VERSION ""

NS_ :

BS_:

BU_: Inverter1 Tester OBC_DDC VCU IPB Labcar_Transmit OBD_Tester TestTool_RB IMU_RB HU_B HU_C HU_A EPAS CKM12RX CKM12TX
VAL_TABLE_ CLU_Types 15 "Unknown" 14 "Unknown" 13 "Unknown" 12 "Unknown" 11 "Unknown" 10 "Unknown" 9 "Unknown" 8 "Unknown" 7 "Unknown" 6 "Unknown" 5 "Unknown" 4 "Unknown" 3 "Unknown" 2 " DRS-MM5.8" 1 "Unknown" 0 "Unknown" ;
VAL_TABLE_ CLU_Status 3 "Sync underflow" 2 "Sync overflow" 1 "Invalid" 0 "No sync failure" ;
VAL_TABLE_ Switches 1 "On" 0 "Off" ;
VAL_TABLE_ IMU_Sensor_Status 15 "Reserved" 14 "Reserved" 13 "Reserved" 12 "Reserved" 11 "Reserved" 10 "Reserved" 9 "Reserved" 8 "Reserved" 7 "Initialization running" 6 "Initialization running" 5 "Initialization running" 4 "Initialization running" 3 "Reserved" 2 "Signal failure" 1 "Sensor not available" 0 "Signal in specification" ;
VAL_TABLE_ Indicator_Color_Table 15 "Dim White" 14 "Dim Violet" 13 "Dim Blue" 12 "Dim Cyan" 11 "Dim Green" 10 "Dim Yellow" 9 "Dim Red" 8 "White" 7 "Violet" 6 "Blue" 5 "Cyan" 4 "Green" 3 "Yellow" 2 "Orange" 1 "Red" 0 "Black" ;

BO_ 3221225472 VECTOR__INDEPENDENT_SIG_MSG: 0 Vector__XXX
 SG_ MDriverRequest_Updated : 0|1@0+ (1,0) [0|1] "-" Vector__XXX
 SG_ MMotAct_Updated : 0|1@0+ (1,0) [0|1] "-" Vector__XXX
 SG_ HMI_OPD_Set_VirtualZeroPoint : 0|8@0+ (0.5,0) [0|50] "%" Vector__XXX
 SG_ HMI_OPD_MaxDeceleration : 0|8@0- (0.05,-3) [-3|0] "m/s 2" Vector__XXX

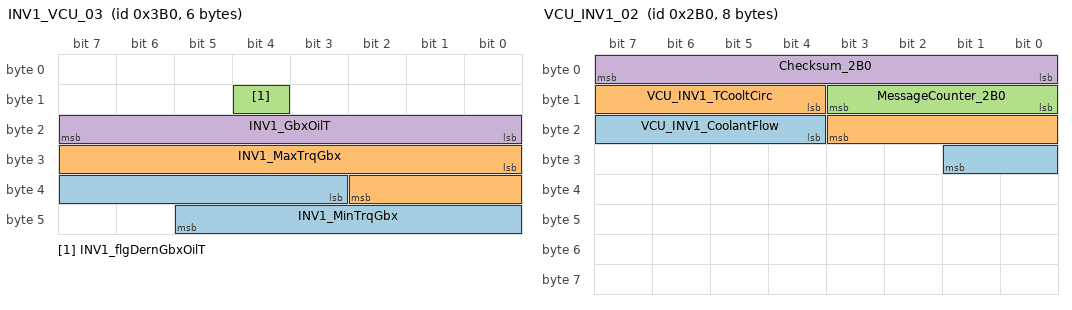
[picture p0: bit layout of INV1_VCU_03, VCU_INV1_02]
BO_ 944 INV1_VCU_03: 6 Inverter1
 SG_ INV1_MinTrqGbx : 35|11@1+ (1,-1023) [-1023|1024] "Nm"  VCU
 SG_ INV1_MaxTrqGbx : 24|11@1+ (1,-1023) [-1023|1024] "Nm"  VCU
 SG_ INV1_flgDernGbxOilT : 12|1@1+ (1,0) [0|1] "-"  VCU
 SG_ INV1_GbxOilT : 16|8@1+ (1,-40) [-40|213] "°C"  VCU

BO_ 688 VCU_INV1_02: 8 VCU
 SG_ VCU_INV1_CoolantFlow : 20|6@1+ (0.25,0) [0|15.5] "l/min"  Inverter1
 SG_ VCU_INV1_TCooltCirc : 12|8@1+ (1,-40) [-40|213] "°C"  Inverter1
 SG_ MessageCounter_2B0 : 8|4@1+ (1,0) [0|15] "-"  Inverter1
 SG_ Checksum_2B0 : 0|8@1+ (1,0) [0|255] "-"  Inverter1

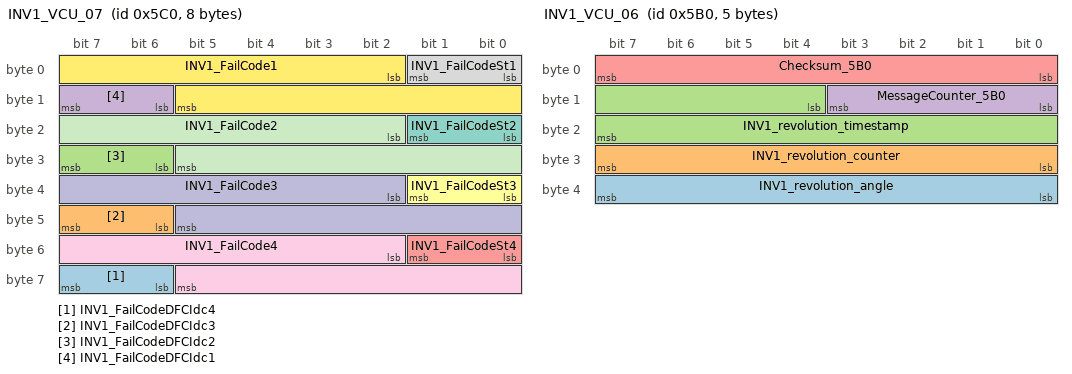
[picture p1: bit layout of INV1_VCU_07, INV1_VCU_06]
BO_ 1472 INV1_VCU_07: 8 Inverter1
 SG_ INV1_FailCodeDFCIdc4 : 62|2@1+ (1,0) [0|3] "" Vector__XXX
 SG_ INV1_FailCodeDFCIdc3 : 46|2@1+ (1,0) [0|3] "" Vector__XXX
 SG_ INV1_FailCodeDFCIdc2 : 30|2@1+ (1,0) [0|3] "" Vector__XXX
 SG_ INV1_FailCodeDFCIdc1 : 14|2@1+ (1,0) [0|3] "" Vector__XXX
 SG_ INV1_FailCodeSt4 : 48|2@1+ (1,0) [0|3] "" Vector__XXX
 SG_ INV1_FailCodeSt3 : 32|2@1+ (1,0) [0|3] "" Vector__XXX
 SG_ INV1_FailCodeSt2 : 16|2@1+ (1,0) [0|3] "" Vector__XXX
 SG_ INV1_FailCodeSt1 : 0|2@1+ (1,0) [0|3] "" Vector__XXX
 SG_ INV1_FailCode4 : 50|12@1+ (1,0) [0|4095] "" Vector__XXX
 SG_ INV1_FailCode3 : 34|12@1+ (1,0) [0|4095] "" Vector__XXX
 SG_ INV1_FailCode2 : 18|12@1+ (1,0) [0|4095] "" Vector__XXX
 SG_ INV1_FailCode1 : 2|12@1+ (1,0) [0|4095] "" Vector__XXX

BO_ 1456 INV1_VCU_06: 5 Inverter1
 SG_ INV1_revolution_angle : 32|8@1+ (2,0) [0|360] ""  VCU
 SG_ INV1_revolution_counter : 24|8@1+ (1,0) [0|255] ""  VCU
 SG_ INV1_revolution_timestamp : 12|12@1+ (1,0) [0|4095] ""  VCU
 SG_ MessageCounter_5B0 : 8|4@1+ (1,0) [0|15] "-"  VCU
 SG_ Checksum_5B0 : 0|8@1+ (1,0) [0|255] "-"  VCU

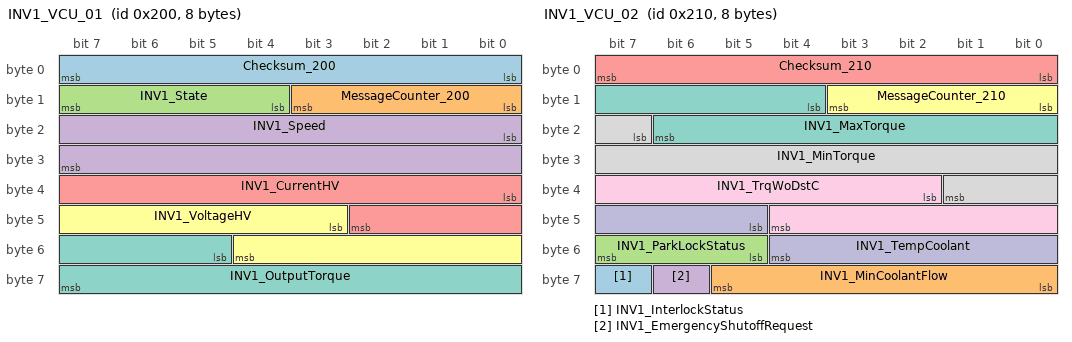
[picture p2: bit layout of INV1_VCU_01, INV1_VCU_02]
BO_ 512 INV1_VCU_01: 8 Inverter1
 SG_ Checksum_200 : 0|8@1+ (1,0) [0|255] "-"  VCU
 SG_ MessageCounter_200 : 8|4@1+ (1,0) [0|15] "-"  VCU
 SG_ INV1_State : 12|4@1+ (1,0) [0|15] "-"  VCU
 SG_ INV1_Speed : 16|16@1+ (1,-32767) [-32767|32766] "1/min"  VCU
 SG_ INV1_CurrentHV : 32|11@1+ (1,-1023) [-1023|1022] "A"  VCU
 SG_ INV1_VoltageHV : 43|10@1+ (1,0) [0|1021] "V"  VCU
 SG_ INV1_OutputTorque : 53|11@1+ (1,-1023) [-1023|1022] "Nm"  VCU

BO_ 528 INV1_VCU_02: 8 Inverter1
 SG_ INV1_InterlockStatus : 63|1@1+ (1,0) [0|1] "-"  VCU
 SG_ INV1_MinCoolantFlow : 56|6@1+ (0.25,0) [0|15.75] "l/min"  VCU
 SG_ INV1_ParkLockStatus : 53|3@1+ (1,0) [0|4] "-"  VCU
 SG_ INV1_EmergencyShutoffRequest : 62|1@1+ (1,0) [0|1] "-"  VCU
 SG_ Checksum_210 : 0|8@1+ (1,0) [0|255] "-"  VCU
 SG_ MessageCounter_210 : 8|4@1+ (1,0) [0|15] "-"  VCU
 SG_ INV1_MaxTorque : 12|11@1+ (1,-1023) [-1023|1024] "Nm"  VCU
 SG_ INV1_MinTorque : 23|11@1+ (1,-1023) [-1023|1024] "Nm"  VCU
 SG_ INV1_TrqWoDstC : 34|11@1+ (1,-1023) [-1023|1022] "Nm"  VCU
 SG_ INV1_TempCoolant : 45|8@1+ (1,-40) [-40|213] "°C"  VCU

BO_ 1568 INV1_VCU_04: 8 Inverter1
 SG_ INV1_MIL : 53|1@1+ (1,0) [0|1] "-"  VCU
 SG_ INV1_bDernTemp_Inverter : 48|1@1+ (1,0) [0|1] "-"  VCU
 SG_ INV1_bReadyHV : 63|1@1+ (1,0) [0|1] "-"  VCU
 SG_ INV1_bDstActive : 62|1@1+ (1,0) [0|1] "-"  VCU
 SG_ INV1_bDernTrqMax : 60|1@1+ (1,0) [0|1] "-"  VCU
 SG_ INV1_bDernTrqMin : 59|1@1+ (1,0) [0|1] "-"  VCU
 SG_ INV1_bDiagReq : 61|1@1+ (1,0) [0|1] "-"  VCU
 SG_ INV1_bDernTemp_EMachine : 58|1@1+ (1,0) [0|1] "-"  VCU
 SG_ INV1_bDernUndrIdc : 57|1@1+ (1,0) [0|1] "-"  VCU
 SG_ INV1_bDernOvrIdc : 56|1@1+ (1,0) [0|1] "-"  VCU
 SG_ INV1_bDernUndrUdc : 55|1@1+ (1,0) [0|1] "-"  VCU
 SG_ INV1_bDernOvrUdc : 54|1@1+ (1,0) [0|1] "-"  VCU
 SG_ INV1_StatorTemperature : 33|9@1+ (1,-40) [-40|469] "°C"  VCU
 SG_ Checksum_620 : 0|8@1+ (1,0) [0|255] "-"  VCU
 SG_ MessageCounter_620 : 8|4@1+ (1,0) [0|15] "-"  VCU
 SG_ INV1_EVServiceLight : 12|2@1+ (1,0) [0|3] "-"  VCU
 SG_ INV1_ElecTractionCtrlLight : 14|2@1+ (1,0) [0|3] "-"  VCU
 SG_ INV1_InverterTemperature : 16|8@1+ (1,-40) [-40|213] "°C"  VCU
 SG_ INV1_VoltageT30 : 42|6@1+ (0.5,0) [0|31.5] "V"  VCU
 SG_ INV1_RotorTemperature : 24|9@1+ (1,-40) [-40|469] "°C"  VCU

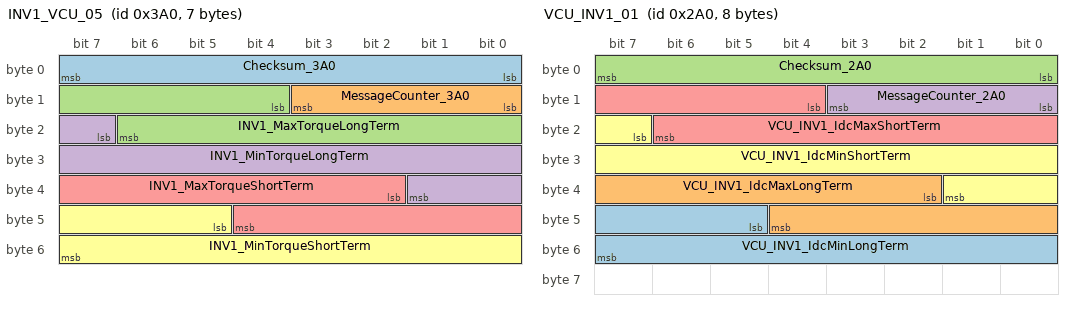
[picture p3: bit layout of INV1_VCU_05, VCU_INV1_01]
BO_ 928 INV1_VCU_05: 7 Inverter1
 SG_ Checksum_3A0 : 0|8@1+ (1,0) [0|255] "-"  VCU
 SG_ MessageCounter_3A0 : 8|4@1+ (1,0) [0|15] "-"  VCU
 SG_ INV1_MaxTorqueLongTerm : 12|11@1+ (1,-1023) [-1023|1024] "Nm"  VCU
 SG_ INV1_MinTorqueLongTerm : 23|11@1+ (1,-1023) [-1023|1024] "Nm"  VCU
 SG_ INV1_MaxTorqueShortTerm : 34|11@1+ (1,-1023) [-1023|1024] "Nm"  VCU
 SG_ INV1_MinTorqueShortTerm : 45|11@1+ (1,-1023) [-1023|1024] "Nm"  VCU

BO_ 672 VCU_INV1_01: 8 VCU
 SG_ VCU_INV1_IdcMinLongTerm : 45|11@1+ (1,-1023) [-1023|1022] "A"  Inverter1
 SG_ VCU_INV1_IdcMaxLongTerm : 34|11@1+ (1,-1023) [-1023|1022] "A"  Inverter1
 SG_ Checksum_2A0 : 0|8@1+ (1,0) [0|255] "-"  Inverter1
 SG_ MessageCounter_2A0 : 8|4@1+ (1,0) [0|15] "-"  Inverter1
 SG_ VCU_INV1_IdcMaxShortTerm : 12|11@1+ (1,-1023) [-1023|1022] "A"  Inverter1
 SG_ VCU_INV1_IdcMinShortTerm : 23|11@1+ (1,-1023) [-1023|1022] "A"  Inverter1

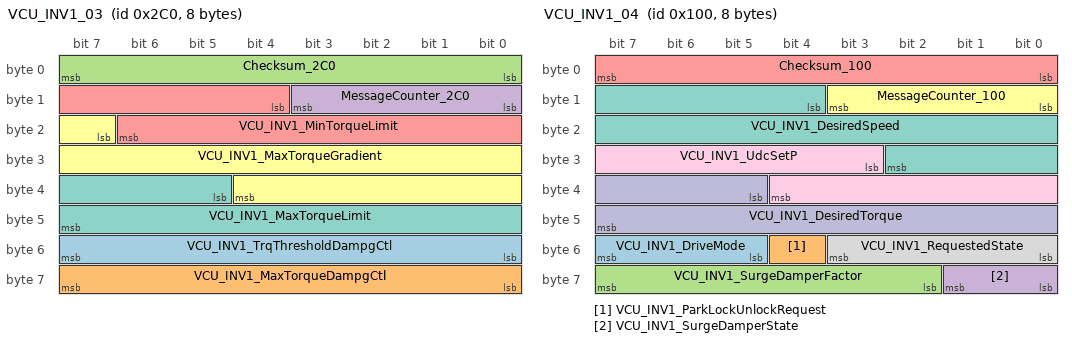
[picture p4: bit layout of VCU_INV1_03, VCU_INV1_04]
BO_ 704 VCU_INV1_03: 8 VCU
 SG_ VCU_INV1_TrqThresholdDampgCtl : 48|8@1+ (0.1,0) [0|25] "Nm"  Inverter1
 SG_ VCU_INV1_MaxTorqueDampgCtl : 56|8@1+ (1,0) [0|253] "Nm"  Inverter1
 SG_ Checksum_2C0 : 0|8@1+ (1,0) [0|255] "-"  Inverter1
 SG_ MessageCounter_2C0 : 8|4@1+ (1,0) [0|15] "-"  Inverter1
 SG_ VCU_INV1_MinTorqueLimit : 12|11@1+ (1,-1023) [-1023|1022] "Nm"  Inverter1
 SG_ VCU_INV1_MaxTorqueGradient : 23|14@1+ (32,0) [0|524192] "Nm/s"  Inverter1
 SG_ VCU_INV1_MaxTorqueLimit : 37|11@1+ (1,-1023) [-1023|1022] "Nm"  Inverter1

BO_ 256 VCU_INV1_04: 8 VCU
 SG_ VCU_INV1_DriveMode : 53|3@1+ (1,0) [0|7] ""  Inverter1
 SG_ VCU_INV1_ParkLockUnlockRequest : 52|1@1+ (1,0) [0|1] "-"  Inverter1
 SG_ VCU_INV1_SurgeDamperFactor : 58|6@1+ (0.125,0) [0|7.625] "-"  Inverter1
 SG_ VCU_INV1_SurgeDamperState : 56|2@1+ (1,0) [0|3] "-"  Inverter1
 SG_ Checksum_100 : 0|8@1+ (1,0) [0|255] "-"  Inverter1
 SG_ MessageCounter_100 : 8|4@1+ (1,0) [0|15] "-"  Inverter1
 SG_ VCU_INV1_DesiredSpeed : 12|15@1+ (1,-16383) [-16383|16382] "1/min"  Inverter1
 SG_ VCU_INV1_RequestedState : 48|4@1+ (1,0) [0|15] "-"  Inverter1
 SG_ VCU_INV1_UdcSetP : 27|10@1+ (1,0) [0|1021] "V"  Inverter1
 SG_ VCU_INV1_DesiredTorque : 37|11@1+ (1,-1023) [-1023|1022] "Nm"  Inverter1

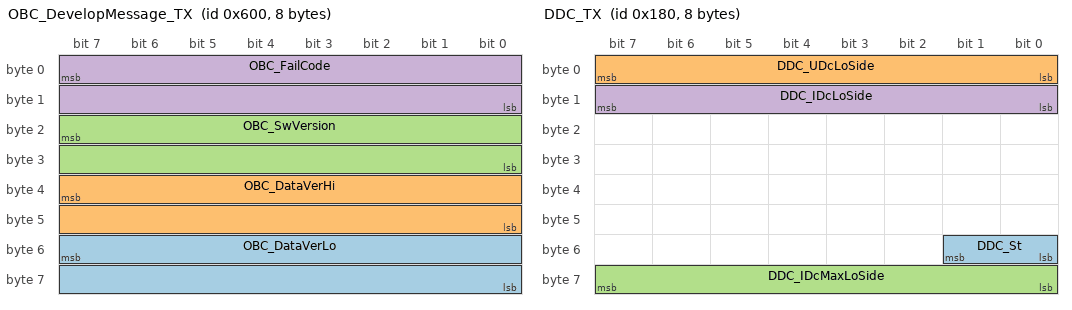
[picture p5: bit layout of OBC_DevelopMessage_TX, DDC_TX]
BO_ 1536 OBC_DevelopMessage_TX: 8 OBC_DDC
 SG_ OBC_DataVerLo : 55|16@0+ (1,0) [0|65535] ""  Tester
 SG_ OBC_DataVerHi : 39|16@0+ (1,0) [0|65535] ""  Tester
 SG_ OBC_SwVersion : 23|16@0+ (1,0) [0|65535] ""  Tester
 SG_ OBC_FailCode : 7|16@0+ (1,0) [0|65535] ""  Tester

BO_ 1637 DDC_TX1: 8 OBC_DDC
 SG_ DDC_UDcHiSide : 41|13@0+ (0.1,0) [0|510] "V"  Tester
 SG_ DDC_IDcHiSide : 15|8@0+ (1,0) [0|254] "A"  Tester

BO_ 384 DDC_TX: 8 OBC_DDC
 SG_ DDC_St : 49|2@0+ (1,0) [0|3] ""  Tester
 SG_ DDC_UDcLoSide : 7|8@0+ (0.1,0) [0|25.4] "V"  Tester
 SG_ DDC_IDcMaxLoSide : 63|8@0+ (1,0) [0|254] "A"  Tester
 SG_ DDC_IDcLoSide : 15|8@0+ (1,0) [0|255] "A"  Tester

BO_ 357 Tester_DDC_Ctrl: 8 Tester
 SG_ Tester_DDC_DesMod : 15|1@0+ (1,0) [0|1] ""  OBC_DDC
 SG_ Tester_DDC_UDcDes : 7|8@0+ (0.025,10.6) [10.6|16.95] "V"  OBC_DDC

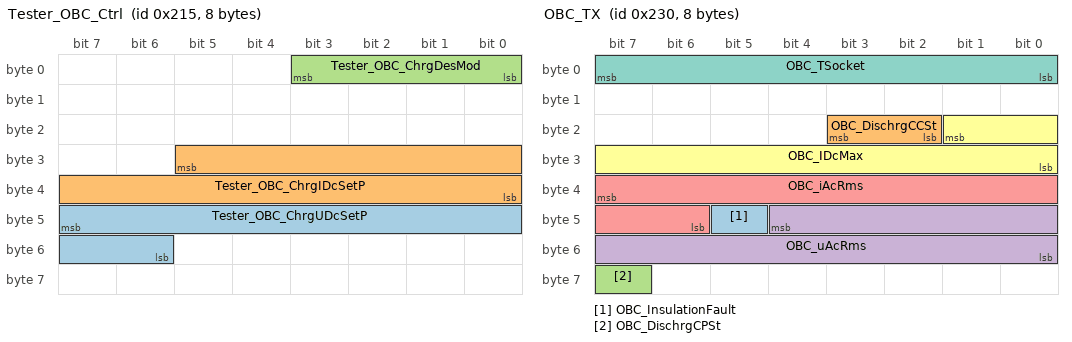
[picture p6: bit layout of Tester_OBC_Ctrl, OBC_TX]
BO_ 533 Tester_OBC_Ctrl: 8 Tester
 SG_ Tester_OBC_ChrgUDcSetP : 47|10@0+ (0.1,0) [0|100] "A"  OBC_DDC
 SG_ Tester_OBC_ChrgIDcSetP : 29|14@0+ (0.1,0) [0|500] "V"  OBC_DDC
 SG_ Tester_OBC_ChrgDesMod : 3|4@0+ (1,0) [0|15] ""  OBC_DDC

BO_ 640 Tester_ELK_Ctrl: 8 Tester
 SG_ Tester_ELK_Des : 7|3@0+ (1,0) [0|7] ""  OBC_DDC

BO_ 560 OBC_TX: 8 OBC_DDC
 SG_ OBC_InsulationFault : 45|1@0+ (1,0) [0|1] ""  Tester
 SG_ OBC_DischrgCCSt : 19|2@0+ (1,0) [0|3] ""  Tester
 SG_ OBC_DischrgCPSt : 63|1@0+ (1,0) [0|1] ""  Tester
 SG_ OBC_uAcRms : 44|13@0+ (0.1,0) [0|500] "V"  Tester
 SG_ OBC_iAcRms : 39|10@0+ (0.1,0) [0|100] "A"  Tester
 SG_ OBC_IDcMax : 17|10@0+ (0.1,0) [0|50] "A"  Tester
 SG_ OBC_TSocket : 7|8@0+ (1,-40) [-40|214] "DegreeC"  Tester

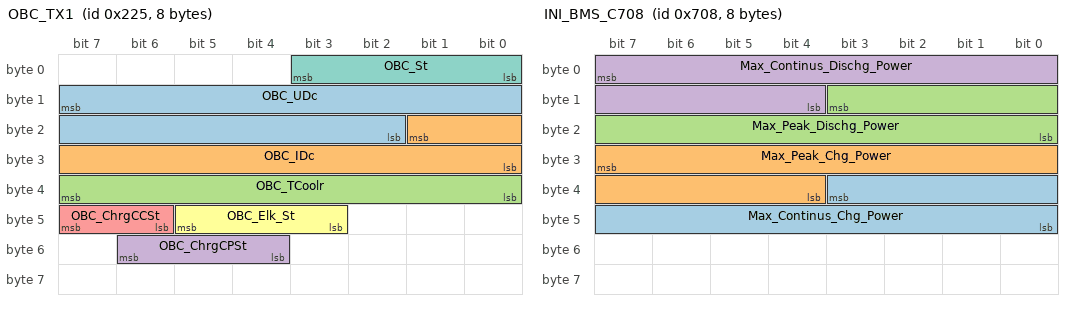
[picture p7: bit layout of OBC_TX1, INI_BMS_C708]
BO_ 549 OBC_TX1: 8 OBC_DDC
 SG_ OBC_UDc : 15|14@0+ (0.1,0) [0|1000] "V"  Tester
 SG_ OBC_IDc : 17|10@0+ (0.1,-50) [-50|50] "A"  Tester
 SG_ OBC_TCoolr : 39|8@0+ (1,-40) [-40|214] "DegreeC"  Tester
 SG_ OBC_ChrgCPSt : 54|3@0+ (1,0) [0|7] ""  Tester
 SG_ OBC_ChrgCCSt : 47|2@0+ (1,0) [0|3] ""  Tester
 SG_ OBC_Elk_St : 45|3@0+ (1,0) [0|4] ""  Tester
 SG_ OBC_St : 3|4@0+ (1,0) [0|15] ""  Tester

BO_ 1800 INI_BMS_C708: 8 Vector__XXX
 SG_ Max_Continus_Chg_Power : 35|12@0+ (0.1,0) [0|300] ""  VCU
 SG_ Max_Peak_Chg_Power : 31|12@0+ (0.1,0) [0|300] ""  VCU
 SG_ Max_Peak_Dischg_Power : 11|12@0+ (0.1,0) [0|300] ""  VCU
 SG_ Max_Continus_Dischg_Power : 7|12@0+ (0.1,0) [0|300] ""  VCU

BO_ 1799 INI_BMS_C707: 8 Vector__XXX
 SG_ BMUFault : 36|1@0+ (1,0) [0|1] ""  VCU
 SG_ LowVoltSupplyAlarm : 39|1@0+ (1,0) [0|1] ""  VCU
 SG_ PrechargeFaultAlarm : 37|1@0+ (1,0) [0|1] ""  VCU
 SG_ BattDischrgOverCurrAlarm : 31|2@0+ (1,0) [0|3] ""  VCU
 SG_ BattFBOverCurrAlarm : 17|2@0+ (1,0) [0|3] ""  VCU
 SG_ SOCJump : 19|2@0+ (1,0) [0|3] ""  VCU
 SG_ SOCLowAlarm : 21|2@0+ (1,0) [0|3] ""  VCU
 SG_ InsulationFault : 29|2@0+ (1,0) [0|3] ""  VCU
 SG_ PosMainRlyConglut : 26|1@0+ (1,0) [0|1] ""  VCU
 SG_ CAN3CommAlarm : 24|1@0+ (1,0) [0|1] ""  VCU
 SG_ CAN1CommAlarm : 25|1@0+ (1,0) [0|1] ""  VCU
 SG_ TotalBattVoltUnderAlarm : 15|2@0+ (1,0) [0|3] ""  VCU
 SG_ BattUnderTempAlarm : 11|2@0+ (1,0) [0|3] ""  VCU
 SG_ NegMainRlyConglut : 27|1@0+ (1,0) [0|1] ""  VCU
 SG_ HVILAlarm : 38|1@0+ (1,0) [0|1] ""  VCU
 SG_ TotalBattVoltOverAlarm : 1|2@0+ (1,0) [0|3] ""  VCU
 SG_ BattHighTempAlarm : 13|2@0+ (1,0) [0|3] ""  VCU
 SG_ SOCHighAlarm : 23|2@0+ (1,0) [0|3] ""  VCU
 SG_ CellVoltDiffOverAlarm : 3|2@0+ (1,0) [0|3] ""  VCU
 SG_ CellTempDiffOverAlarm : 9|2@0+ (1,0) [0|3] ""  VCU
 SG_ MinCellVoltUnderAlarm : 5|2@0+ (1,0) [0|3] ""  VCU
 SG_ MaxCellVoltOverAlarm : 7|2@0+ (1,0) [0|3] ""  VCU

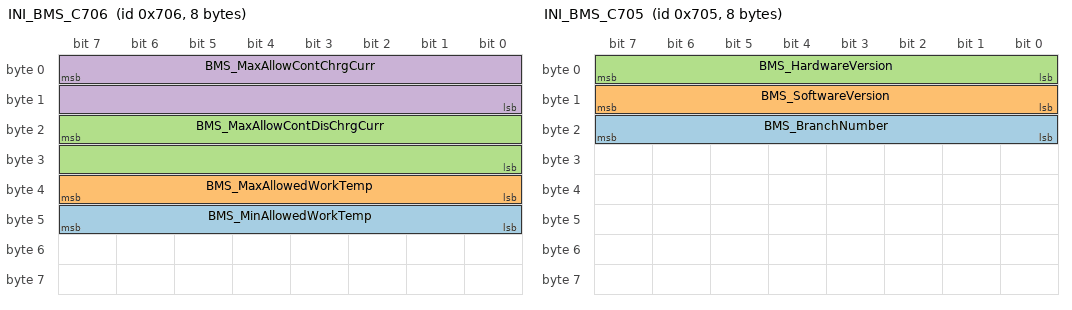
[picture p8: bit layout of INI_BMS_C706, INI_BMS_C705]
BO_ 1798 INI_BMS_C706: 8 Vector__XXX
 SG_ BMS_MinAllowedWorkTemp : 47|8@0+ (1,-40) [-40|210] "ºC"  VCU
 SG_ BMS_MaxAllowedWorkTemp : 39|8@0+ (1,-40) [-40|210] "ºC"  VCU
 SG_ BMS_MaxAllowContDisChrgCurr : 23|16@0+ (0.1,0) [0|1000] "A"  VCU
 SG_ BMS_MaxAllowContChrgCurr : 7|16@0+ (0.1,0) [0|1000] "A"  VCU

BO_ 1797 INI_BMS_C705: 8 Vector__XXX
 SG_ BMS_BranchNumber : 23|8@0+ (1,0) [0|255] ""  VCU
 SG_ BMS_SoftwareVersion : 15|8@0+ (0.1,0) [0|25.5] ""  VCU
 SG_ BMS_HardwareVersion : 7|8@0+ (0.1,0) [0|25.5] ""  VCU

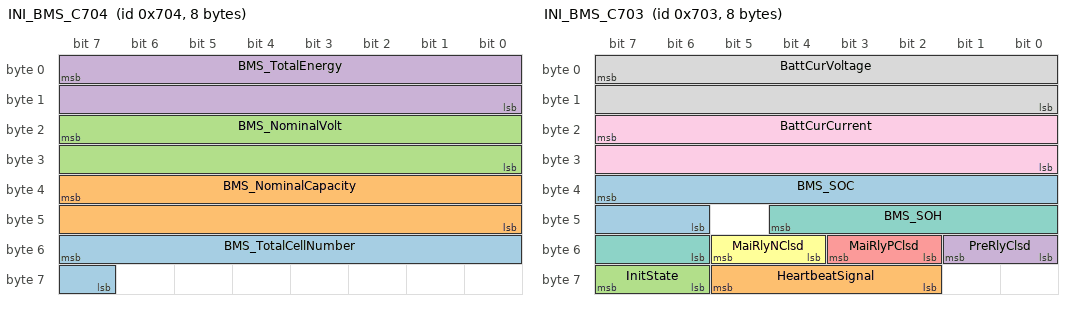
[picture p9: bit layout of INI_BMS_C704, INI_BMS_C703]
BO_ 1796 INI_BMS_C704: 8 Vector__XXX
 SG_ BMS_TotalCellNumber : 55|9@0+ (1,0) [0|511] ""  VCU
 SG_ BMS_NominalCapacity : 39|16@0+ (0.1,0) [0|1000] "AH"  VCU
 SG_ BMS_NominalVolt : 23|16@0+ (0.1,0) [0|1000] "V"  VCU
 SG_ BMS_TotalEnergy : 7|16@0+ (0.01,0) [0|655.35] "KWh"  VCU

BO_ 1795 INI_BMS_C703: 8 Vector__XXX
 SG_ BMS_SOC : 39|10@0+ (0.1,0) [0|102.3] "%"  VCU
 SG_ HeartbeatSignal : 61|4@0+ (1,0) [0|15] ""  VCU
 SG_ InitState : 63|2@0+ (1,0) [0|3] ""  VCU
 SG_ PreRlyClsd : 49|2@0+ (1,0) [0|3] ""  VCU
 SG_ MaiRlyPClsd : 51|2@0+ (1,0) [0|3] ""  VCU
 SG_ MaiRlyNClsd : 53|2@0+ (1,0) [0|3] ""  VCU
 SG_ BMS_SOH : 44|7@0+ (1,0) [0|100] "%"  VCU
 SG_ BattCurVoltage : 7|16@0+ (0.1,0) [0|500] "A"  VCU
 SG_ BattCurCurrent : 23|16@0+ (0.1,-600) [-600|600] "V"  VCU

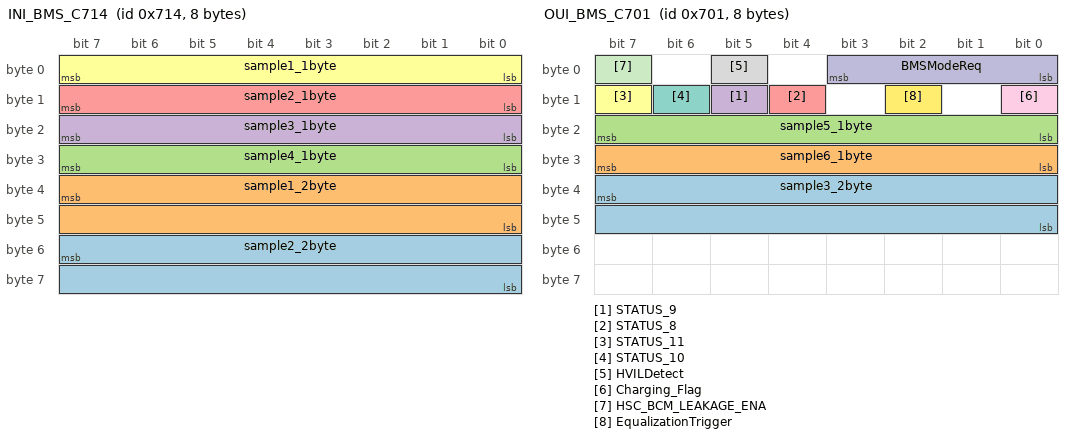
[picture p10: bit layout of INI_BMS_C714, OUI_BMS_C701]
BO_ 1812 INI_BMS_C714: 8 Vector__XXX
 SG_ sample2_2byte : 55|16@0+ (1,0) [0|65535] ""  VCU
 SG_ sample1_2byte : 39|16@0+ (1,0) [0|65535] ""  VCU
 SG_ sample4_1byte : 31|8@0+ (1,0) [0|255] ""  VCU
 SG_ sample3_1byte : 23|8@0+ (1,0) [0|255] ""  VCU
 SG_ sample2_1byte : 15|8@0+ (1,0) [0|255] ""  VCU
 SG_ sample1_1byte : 7|8@0+ (1,0) [0|255] ""  VCU

BO_ 1794 OUI_BMS_C702: 8 VCU
 SG_ Busbar_Voltage : 7|16@0+ (1,0) [0|500] "V" Vector__XXX

BO_ 1793 OUI_BMS_C701: 8 VCU
 SG_ sample3_2byte : 39|16@0+ (1,0) [0|65535] "" Vector__XXX
 SG_ sample6_1byte : 31|8@0+ (1,0) [0|255] "" Vector__XXX
 SG_ sample5_1byte : 23|8@0+ (1,0) [0|255] "" Vector__XXX
 SG_ STATUS_9 : 13|1@0+ (1,0) [0|1] "" Vector__XXX
 SG_ STATUS_8 : 12|1@0+ (1,0) [0|1] "" Vector__XXX
 SG_ STATUS_11 : 15|1@0+ (1,0) [0|1] "" Vector__XXX
 SG_ STATUS_10 : 14|1@0+ (1,0) [0|1] "" Vector__XXX
 SG_ HVILDetect : 5|1@0+ (1,0) [0|1] "" Vector__XXX
 SG_ Charging_Flag : 8|1@0+ (1,0) [0|1] "" Vector__XXX
 SG_ BMSModeReq : 3|4@0+ (1,0) [0|15] "" Vector__XXX
 SG_ HSC_BCM_LEAKAGE_ENA : 7|1@0+ (1,0) [0|1] "" Vector__XXX
 SG_ EqualizationTrigger : 10|1@0+ (1,0) [0|1] "" Vector__XXX

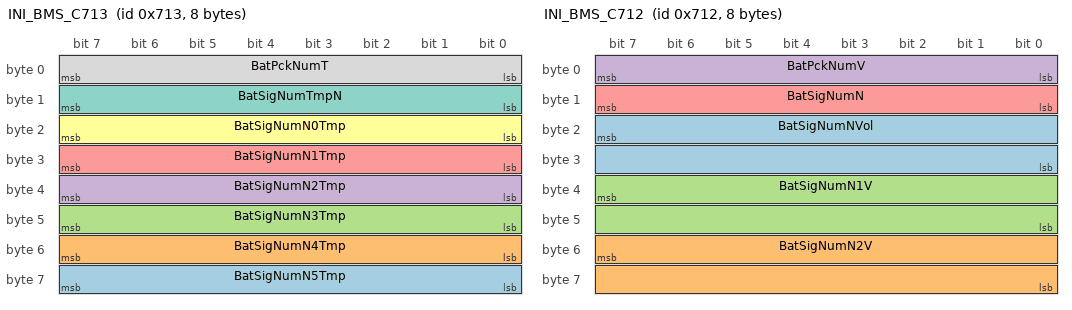
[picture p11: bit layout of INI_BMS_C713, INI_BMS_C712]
BO_ 1811 INI_BMS_C713: 8 Vector__XXX
 SG_ BatSigNumN5Tmp : 63|8@0+ (1,-40) [-40|215] "?"  VCU
 SG_ BatSigNumN4Tmp : 55|8@0+ (1,-40) [-40|215] "?"  VCU
 SG_ BatSigNumN3Tmp : 47|8@0+ (1,-40) [-40|215] "?"  VCU
 SG_ BatSigNumN2Tmp : 39|8@0+ (1,-40) [-40|215] "?"  VCU
 SG_ BatSigNumN1Tmp : 31|8@0+ (1,-40) [-40|215] "?"  VCU
 SG_ BatSigNumN0Tmp : 23|8@0+ (1,-40) [-40|215] "?"  VCU
 SG_ BatSigNumTmpN : 15|8@0+ (1,0) [0|255] ""  VCU
 SG_ BatPckNumT : 7|8@0+ (1,0) [0|255] ""  VCU

BO_ 1810 INI_BMS_C712: 8 Vector__XXX
 SG_ BatSigNumNVol : 23|16@0+ (0.001,0) [0|50] "V"  VCU
 SG_ BatSigNumN2V : 55|16@0+ (0.001,0) [0|50] "V"  VCU
 SG_ BatSigNumN1V : 39|16@0+ (0.001,0) [0|50] "V"  VCU
 SG_ BatPckNumV : 7|8@0+ (1,0) [0|255] ""  VCU
 SG_ BatSigNumN : 15|8@0+ (1,0) [0|255] ""  VCU

BO_ 1801 INI_BMS_C709: 7 Vector__XXX
 SG_ STATUS_1 : 49|1@0+ (1,0) [0|1] ""  VCU
 SG_ STATUS_2 : 50|1@0+ (1,0) [0|1] ""  VCU
 SG_ STATUS_3 : 51|1@0+ (1,0) [0|1] ""  VCU
 SG_ STATUS_4 : 52|1@0+ (1,0) [0|1] ""  VCU
 SG_ STATUS_5 : 53|1@0+ (1,0) [0|1] ""  VCU
 SG_ STATUS_6 : 54|1@0+ (1,0) [0|1] ""  VCU
 SG_ STATUS_7 : 55|1@0+ (1,0) [0|1] ""  VCU
 SG_ BMS_DerateFlag : 48|1@0+ (1,0) [0|1] ""  VCU
 SG_ SOC_CalibrationFlag : 40|1@0+ (1,0) [0|1] ""  VCU
 SG_ OperMod : 47|4@0+ (1,0) [0|15] ""  VCU
 SG_ MinTempProbeNo : 39|8@0+ (1,0) [0|255] ""  VCU
 SG_ MinTempBattPackSubSysNo : 3|4@0+ (1,0) [0|15] ""  VCU
 SG_ MinPresentTemp : 31|8@0+ (1,-50) [-50|200] "Temp"  VCU
 SG_ MaxTempProbeNo : 23|8@0+ (1,0) [0|255] ""  VCU
 SG_ MaxTempBattPackSubSysNo : 7|4@0+ (1,0) [0|15] ""  VCU
 SG_ MaxPresentTemp : 15|8@0+ (1,-50) [-50|200] "Temp"  VCU
 SG_ FltRank : 43|3@0+ (1,0) [0|7] ""  VCU

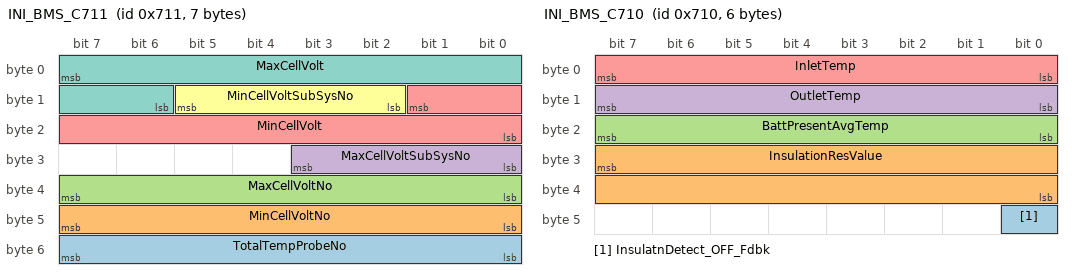
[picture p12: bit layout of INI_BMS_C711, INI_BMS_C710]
BO_ 1809 INI_BMS_C711: 7 Vector__XXX
 SG_ TotalTempProbeNo : 55|8@0+ (1,0) [0|255] ""  VCU
 SG_ MinCellVoltNo : 47|8@0+ (1,0) [0|255] ""  VCU
 SG_ MaxCellVoltNo : 39|8@0+ (1,0) [0|255] ""  VCU
 SG_ MaxCellVoltSubSysNo : 27|4@0+ (1,0) [0|15] ""  VCU
 SG_ MinCellVolt : 9|10@0+ (0.01,0) [0|10.23] ""  VCU
 SG_ MinCellVoltSubSysNo : 13|4@0+ (1,0) [0|15] ""  VCU
 SG_ MaxCellVolt : 7|10@0+ (0.01,0) [0|10.23] "V"  VCU

BO_ 1808 INI_BMS_C710: 6 Vector__XXX
 SG_ InsulatnDetect_OFF_Fdbk : 40|1@0+ (1,0) [0|1] ""  VCU
 SG_ InsulationResValue : 31|16@0+ (1,0) [0|50000] "KO"  VCU
 SG_ BattPresentAvgTemp : 23|8@0+ (1,-50) [-50|200] ""  VCU
 SG_ OutletTemp : 15|8@0+ (1,-50) [-50|200] ""  VCU
 SG_ InletTemp : 7|8@0+ (1,-50) [-50|200] ""  VCU

BO_ 701 OPD2: 3 VCU
 SG_ HMI_OPD_Enable : 7|8@0+ (1,0) [0|1] "-"  IPB

BO_ 0 New_Message_52: 8 Vector__XXX
 SG_ New_Signal_331 : 8|8@1+ (1,0) [0|0] "" Vector__XXX

BO_ 2019 VCU_DiagRequest: 8 Vector__XXX
 SG_ VCU_DiagRequest : 7|64@0+ (1,0) [0|0] ""  VCU

BO_ 2027 VCU_DiagResponse_USDT: 8 VCU
 SG_ VCU_DiagResponse_USDT : 7|64@0+ (1,0) [0|0] "" Vector__XXX

BO_ 280 BRAKE10: 8 Vector__XXX
 SG_ InhibitRecuprationAbsStatus : 6|2@0+ (1,0) [0|3] ""  VCU
 SG_ InhibitRecuprationAbs : 7|1@0+ (1,0) [0|1] ""  VCU

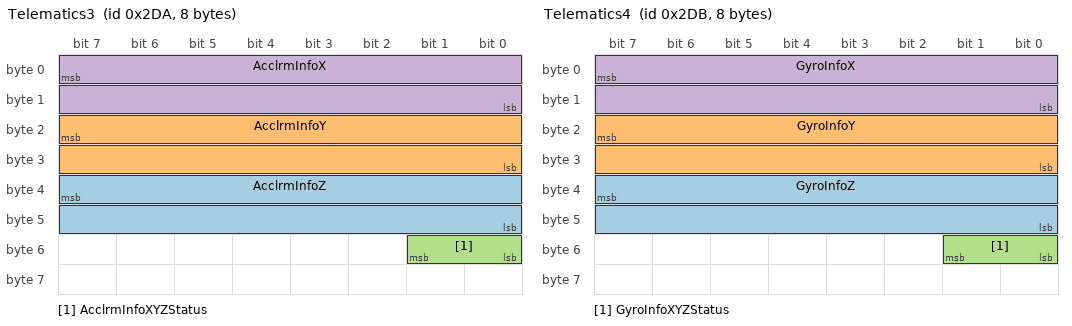
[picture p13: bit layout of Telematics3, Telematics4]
BO_ 730 Telematics3: 8 Vector__XXX
 SG_ AcclrmInfoZ : 39|16@0+ (0.01,-300) [-300|300] "m/s^2"  VCU
 SG_ AcclrmInfoY : 23|16@0+ (0.01,-300) [-300|300] "m/s^2"  VCU
 SG_ AcclrmInfoXYZStatus : 49|2@0+ (1,0) [0|3] ""  VCU
 SG_ AcclrmInfoX : 7|16@0+ (0.01,-300) [-300|300] "m/s^2"  VCU

BO_ 731 Telematics4: 8 Vector__XXX
 SG_ GyroInfoZ : 39|16@0+ (0.1,-2000) [-2000|2000] "deg/s"  VCU
 SG_ GyroInfoY : 23|16@0+ (0.1,-2000) [-2000|2000] "deg/s"  VCU
 SG_ GyroInfoXYZStatus : 49|2@0+ (1,0) [0|3] ""  VCU
 SG_ GyroInfoX : 7|16@0+ (0.1,-2000) [-2000|2000] "deg/s"  VCU

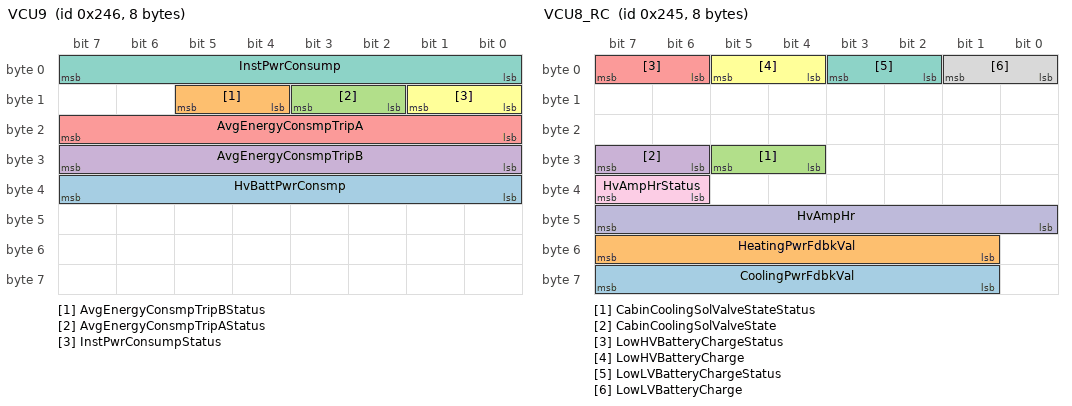
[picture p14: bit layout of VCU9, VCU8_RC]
BO_ 582 VCU9: 8 VCU
 SG_ HvBattPwrConsmp : 39|8@0+ (1,0) [0|250] "KwHr" Vector__XXX
 SG_ AvgEnergyConsmpTripBStatus : 13|2@0+ (1,0) [0|3] "" Vector__XXX
 SG_ AvgEnergyConsmpTripAStatus : 11|2@0+ (1,0) [0|3] "" Vector__XXX
 SG_ AvgEnergyConsmpTripB : 31|8@0+ (1,0) [0|250] "kwH/Km" Vector__XXX
 SG_ AvgEnergyConsmpTripA : 23|8@0+ (1,0) [0|250] "kwH/Km" Vector__XXX
 SG_ InstPwrConsumpStatus : 9|2@0+ (1,0) [0|3] "" Vector__XXX
 SG_ InstPwrConsump : 7|8@0+ (1,-100) [-100|100] "%" Vector__XXX

BO_ 719 CCM_RC2: 8 Vector__XXX
 SG_ PtcHtrForcedCutoff : 7|2@0+ (1,0) [0|3] ""  VCU

BO_ 1142 VCU_SF: 8 VCU
 SG_ PEPS_Invalid_failure_status : 55|2@0+ (1,0) [0|3] "" Vector__XXX
 SG_ Telematics_MTO_Failure_status : 61|2@0+ (1,0) [0|3] "" Vector__XXX
 SG_ Telematics_Invalid_FailureStatus : 63|2@0+ (1,0) [0|3] "" Vector__XXX
 SG_ SRS_MTO_Failure_Status : 59|2@0+ (1,0) [0|3] "" Vector__XXX
 SG_ PEPS_MTO_Failure_Status : 53|2@0+ (1,0) [0|3] "" Vector__XXX
 SG_ IPcMToFailureStatus : 49|2@0+ (1,0) [0|3] "" Vector__XXX
 SG_ IPcInvalidFailureStatus : 51|2@0+ (1,0) [0|3] "" Vector__XXX
 SG_ ABsMToFailureStatus : 7|2@0+ (1,0) [0|3] "" Vector__XXX
 SG_ ABsInvalidFailureStatus : 5|2@0+ (1,0) [0|3] "" Vector__XXX
 SG_ VCU_SW_Version : 31|16@0+ (1,0) [0|65535] "" Vector__XXX
 SG_ VCU_Err_State_Trans_Cntr : 23|8@0+ (1,0) [0|255] "" Vector__XXX
 SG_ VCU_EP_Failure_Status : 13|2@0+ (1,0) [0|3] "" Vector__XXX
 SG_ VCU_BO_Failure_Status : 15|2@0+ (1,0) [0|3] "" Vector__XXX
 SG_ GSS_EV_Invalid_Failure_Status : 41|2@0+ (1,0) [0|3] "" Vector__XXX
 SG_ GSS_EV_MTO_Failure_Status : 43|2@0+ (1,0) [0|3] "" Vector__XXX
 SG_ CCM_MTO_Failure_Status : 45|2@0+ (1,0) [0|3] "" Vector__XXX
 SG_ CCM_Invalid_Failure_Status : 47|2@0+ (1,0) [0|3] "" Vector__XXX
 SG_ BCmInvalidFailureStatus : 9|2@0+ (1,0) [0|3] "" Vector__XXX
 SG_ BCmMToFailureStatus : 11|2@0+ (1,0) [0|3] "" Vector__XXX

BO_ 581 VCU8_RC: 8 VCU
 SG_ CoolingPwrFdbkVal : 63|7@0+ (1,0) [0|100] "%" Vector__XXX
 SG_ HeatingPwrFdbkVal : 55|7@0+ (1,0) [0|100] "%" Vector__XXX
 SG_ CabinCoolingSolValveStateStatus : 29|2@0+ (1,0) [0|3] "" Vector__XXX
 SG_ CabinCoolingSolValveState : 31|2@0+ (1,0) [0|3] "" Vector__XXX
 SG_ LowHVBatteryChargeStatus : 7|2@0+ (1,0) [0|3] "" Vector__XXX
 SG_ LowHVBatteryCharge : 5|2@0+ (1,0) [0|3] "" Vector__XXX
 SG_ LowLVBatteryChargeStatus : 3|2@0+ (1,0) [0|3] "" Vector__XXX
 SG_ LowLVBatteryCharge : 1|2@0+ (1,0) [0|3] "" Vector__XXX
 SG_ HvAmpHrStatus : 39|2@0+ (1,0) [0|3] "" Vector__XXX
 SG_ HvAmpHr : 47|8@0+ (0.5,0) [0|125] "" Vector__XXX

BO_ 1288 TCU_NMPDU: 8 Vector__XXX
 SG_ PartialNetworkInformation_TCU : 14|1@0+ (1,0) [0|1] ""  VCU
 SG_ Reserved55 : 23|1@0+ (1,0) [0|1] ""  VCU
 SG_ Reserved54 : 22|1@0+ (1,0) [0|1] ""  VCU
 SG_ Reserved53 : 21|1@0+ (1,0) [0|1] ""  VCU
 SG_ Reserved52 : 20|1@0+ (1,0) [0|1] ""  VCU
 SG_ Reserved51 : 15|1@0+ (1,0) [0|1] ""  VCU
 SG_ Reserved50 : 13|1@0+ (1,0) [0|1] ""  VCU
 SG_ Reserved49 : 10|1@0+ (1,0) [0|1] ""  VCU
 SG_ Reserved48 : 9|1@0+ (1,0) [0|1] ""  VCU
 SG_ RepeatMessageReq_TCU : 8|1@0+ (1,0) [0|1] ""  VCU
 SG_ PreviousState_TCU : 19|3@0+ (1,0) [0|7] ""  VCU
 SG_ NMCoOrdSlpReady_TCU : 11|1@0+ (1,0) [0|1] ""  VCU
 SG_ CurrentState_TCU : 16|1@0+ (1,0) [0|1] ""  VCU
 SG_ TCU_NMPDU_USER_DATA_D5 : 63|8@0+ (1,0) [0|255] ""  VCU
 SG_ TCU_NMPDU_USER_DATA_D4 : 55|8@0+ (1,0) [0|255] ""  VCU
 SG_ TCU_NMPDU_USER_DATA_D3 : 47|8@0+ (1,0) [0|255] ""  VCU
 SG_ TCU_NMPDU_USER_DATA_D2 : 39|8@0+ (1,0) [0|255] ""  VCU
 SG_ TCU_NMPDU_USER_DATA_D1 : 31|8@0+ (1,0) [0|255] ""  VCU
 SG_ TCU_NMPDU_SRC_ECU_ID : 7|8@0+ (1,0) [0|255] ""  VCU
 SG_ ActiveWakeUp_TCU : 12|1@0+ (1,0) [0|1] ""  VCU

BO_ 1287 VCU_NMPDU: 8 VCU
 SG_ PartialNetworkInformation_VCU : 14|1@0+ (1,0) [0|1] "" Vector__XXX
 SG_ VCU_NMPDU_USER_DATA_D3 : 47|8@0+ (1,0) [0|255] "" Vector__XXX
 SG_ Reserved47 : 23|1@0+ (1,0) [0|1] "" Vector__XXX
 SG_ Reserved46 : 22|1@0+ (1,0) [0|1] "" Vector__XXX
 SG_ Reserved45 : 21|1@0+ (1,0) [0|1] "" Vector__XXX
 SG_ Reserved44 : 20|1@0+ (1,0) [0|1] "" Vector__XXX
 SG_ Reserved43 : 15|1@0+ (1,0) [0|1] "" Vector__XXX
 SG_ Reserved42 : 13|1@0+ (1,0) [0|1] "" Vector__XXX
 SG_ Reserved41 : 10|1@0+ (1,0) [0|1] "" Vector__XXX
 SG_ Reserved40 : 9|1@0+ (1,0) [0|1] "" Vector__XXX
 SG_ RepeatMessageReq_VCU : 8|1@0+ (1,0) [0|1] "" Vector__XXX
 SG_ PreviousState_VCU : 19|3@0+ (1,0) [0|7] "" Vector__XXX
 SG_ NMCoOrdSlpReady_VCU : 11|1@0+ (1,0) [0|1] "" Vector__XXX
 SG_ CurrentState_VCU : 16|1@0+ (1,0) [0|1] "" Vector__XXX
 SG_ VCU_NMPDU_USER_DATA_D5 : 63|8@0+ (1,0) [0|255] "" Vector__XXX
 SG_ VCU_NMPDU_USER_DATA_D4 : 55|8@0+ (1,0) [0|255] "" Vector__XXX
 SG_ VCU_NMPDU_USER_DATA_D2 : 39|8@0+ (1,0) [0|255] "" Vector__XXX
 SG_ VCU_NMPDU_USER_DATA_D1 : 31|8@0+ (1,0) [0|255] "" Vector__XXX
 SG_ VCU_NMPDU_SRC_ECU_ID : 7|8@0+ (1,0) [0|255] "" Vector__XXX
 SG_ ActiveWakeUp_VCU : 12|1@0+ (1,0) [0|1] "" Vector__XXX

BO_ 703 IPC_RC1: 8 Vector__XXX
 SG_ OATICSigNewStatus : 15|2@0+ (1,0) [0|3] ""  VCU
 SG_ OATICSigNew : 7|8@0+ (0.5,-40) [-40|85] "degC"  VCU

CM_ BU_ Inverter1 "Inverter";
CM_ BU_ VCU "Vehicle Control Unit";
CM_ BO_ 3221225472 "This is a message for not used signals, created by Vector CANdb++ DBC OLE DB Provider.";
CM_ BO_ 944 "Frame for Gearbox specific signals of eAxle. 
Inactive if INV1 is not an eAxle but a standalone Inverter.";
CM_ SG_ 944 INV1_MinTrqGbx "eAxle Gearbox minimum allowed torque";
CM_ SG_ 944 INV1_MaxTrqGbx "eAxle Gearbox maximum allowed torque";
CM_ SG_ 944 INV1_flgDernGbxOilT "Derating because of gearbox oil temperature";
CM_ SG_ 944 INV1_GbxOilT "Temperature of eAxle Gearbox Oil (INV1)";
CM_ SG_ 688 VCU_INV1_CoolantFlow "current coolant flow based on pump actuation";
CM_ SG_ 688 VCU_INV1_TCooltCirc "Temperature Coolant Circuit close to INV1 (upstream INV1 preferred)";
CM_ SG_ 688 MessageCounter_2B0 "Message counter signal for frame 2B0";
CM_ SG_ 688 Checksum_2B0 "Checksum signal for frame 2B0";
CM_ BO_ 1472 "Inverter1 Information Frame (Fault Codes).
For Fault Code Definition see TCD - technical customer documentation.";
CM_ SG_ 1472 INV1_FailCodeDFCIdc4 "Inverter1 Failure code4 DFC Id";
CM_ SG_ 1472 INV1_FailCodeDFCIdc3 "Inverter1 Failure code3 DFC Id";
CM_ SG_ 1472 INV1_FailCodeDFCIdc2 "Inverter1 Failure code2 DFC Id";
CM_ SG_ 1472 INV1_FailCodeDFCIdc1 "Inverter1 Failure code1 DFC Id";
CM_ SG_ 1472 INV1_FailCodeSt4 "Inverter1 Failure code4 state";
CM_ SG_ 1472 INV1_FailCodeSt3 "Inverter1 Failure code3 state";
CM_ SG_ 1472 INV1_FailCodeSt2 "Inverter1 Failure code2 state";
CM_ SG_ 1472 INV1_FailCodeSt1 "Inverter1 Failure code1 state";
CM_ SG_ 1472 INV1_FailCode4 "Inverter1 Failure code4 value.
For Fault Code Definition see TCD - technical customer documentation.";
CM_ SG_ 1472 INV1_FailCode3 "Inverter1 Failure code3 value.
For Fault Code Definition see TCD - technical customer documentation.";
CM_ SG_ 1472 INV1_FailCode2 "Inverter1 Failure code2 value.
For Fault Code Definition see TCD - technical customer documentation.";
CM_ SG_ 1472 INV1_FailCode1 "Inverter1 Failure code1 value.
For Fault Code Definition see TCD - technical customer documentation.";
CM_ BO_ 1456 "Inverter1 Information Frame (Temperatures / controller supply)";
CM_ SG_ 1456 INV1_revolution_angle "current angle position of the rotor";
CM_ SG_ 1456 INV1_revolution_counter "number of full electrical (not mechanical) revolutions of the e-machine";
CM_ SG_ 1456 INV1_revolution_timestamp "number of PWM task in which the other signals were calculated";
CM_ SG_ 1456 MessageCounter_5B0 "Message counter signal for frame";
CM_ SG_ 1456 Checksum_5B0 "Checksum signal for frame";
CM_ BO_ 512 "Inverter1 Information Frame (Operating Status)
DATA_ID=[0,1,2,3,4,5,6,7,8,9,10,11,12,13,14,15]";
CM_ SG_ 512 Checksum_200 "Checksum signal for frame";
CM_ SG_ 512 MessageCounter_200 "Message counter signal for frame";
CM_ SG_ 512 INV1_State "Information of the state of the electric machine";
CM_ SG_ 512 INV1_Speed "Rotional speed of electric machine";
CM_ SG_ 512 INV1_CurrentHV "HV current at the DC/AC converter";
CM_ SG_ 512 INV1_VoltageHV "HV voltage at the DC/AC converter";
CM_ SG_ 512 INV1_OutputTorque "Output torque which is currently provided by the electric machine";
CM_ BO_ 528 "Inverter1 Information Frame (Operating Limits)";
CM_ SG_ 528 INV1_InterlockStatus "Interlock Status";
CM_ SG_ 528 INV1_MinCoolantFlow "Minimum coolant flow needed for full operation";
CM_ SG_ 528 INV1_ParkLockStatus "Status of park lock system actuator";
CM_ SG_ 528 INV1_EmergencyShutoffRequest "Emergency shut off requested by inverter ECU";
CM_ SG_ 528 Checksum_210 "Checksum signal for frame";
CM_ SG_ 528 MessageCounter_210 "Message counter signal for frame";
CM_ SG_ 528 INV1_MaxTorque "Electric machine maximum available torque";
CM_ SG_ 528 INV1_MinTorque "Electric machine minimum available torque";
CM_ SG_ 528 INV1_TrqWoDstC "Electric machine actual torque without part of damping control";
CM_ SG_ 528 INV1_TempCoolant "temperature of inverter cooling water";
CM_ BO_ 1568 "Inverter1 Information Frame (Temperatures / controller supply)";
CM_ SG_ 1568 INV1_MIL "MIL (Malfunction Indicator Lamp) request by INV1";
CM_ SG_ 1568 INV1_bDernTemp_Inverter "Derating because of overtemperature E-machine";
CM_ SG_ 1568 INV1_bReadyHV "HV voltage operational";
CM_ SG_ 1568 INV1_bDstActive "Surge Damping active";
CM_ SG_ 1568 INV1_bDernTrqMax "Derating because of max torque";
CM_ SG_ 1568 INV1_bDernTrqMin "Derating because of max torque regenerative";
CM_ SG_ 1568 INV1_bDiagReq "Diag request for e-machine Inverter Calibration";
CM_ SG_ 1568 INV1_bDernTemp_EMachine "Derating because of overtemperature E-machine";
CM_ SG_ 1568 INV1_bDernUndrIdc "Derating because of overcurrent regenerative Inverter E-machine";
CM_ SG_ 1568 INV1_bDernOvrIdc "Derating because of overcurrent Inverter E-machine";
CM_ SG_ 1568 INV1_bDernUndrUdc "Derating because of undervoltage HV";
CM_ SG_ 1568 INV1_bDernOvrUdc "Derating because of overvoltage HV";
CM_ SG_ 1568 INV1_StatorTemperature "Temperature of stator";
CM_ SG_ 1568 Checksum_620 "Checksum signal for frame";
CM_ SG_ 1568 MessageCounter_620 "Message counter signal for frame";
CM_ SG_ 1568 INV1_EVServiceLight "Electric drive system light state";
CM_ SG_ 1568 INV1_ElecTractionCtrlLight "Electric traction control light state";
CM_ SG_ 1568 INV1_InverterTemperature "Current temperature of inverter";
CM_ SG_ 1568 INV1_VoltageT30 "Current UT30 Voltage at inverter";
CM_ SG_ 1568 INV1_RotorTemperature "Temperature of rotor";
CM_ BO_ 928 "Inverter1 Information Frame (Temperatures / controller supply)";
CM_ SG_ 928 Checksum_3A0 "Checksum signal for frame";
CM_ SG_ 928 MessageCounter_3A0 "Message counter signal for frame";
CM_ SG_ 928 INV1_MaxTorqueLongTerm "Maximal total drive long term torque";
CM_ SG_ 928 INV1_MinTorqueLongTerm "Minimum total brake long term torque ";
CM_ SG_ 928 INV1_MaxTorqueShortTerm "Maximal total drive short term torque";
CM_ SG_ 928 INV1_MinTorqueShortTerm "Minimum total brake short term torque ";
CM_ BO_ 672 "Inverter1 Control Frame - Limits";
CM_ SG_ 672 VCU_INV1_IdcMinLongTerm "maximum allowed inverter current generation (generator torque) for long term (negative values expected)";
CM_ SG_ 672 VCU_INV1_IdcMaxLongTerm "maximum allowed inverter current consumption (motor torque) for long term (positive values expected)";
CM_ SG_ 672 Checksum_2A0 "Checksum signal for frame";
CM_ SG_ 672 MessageCounter_2A0 "Message counter signal for frame";
CM_ SG_ 672 VCU_INV1_IdcMaxShortTerm "maximum allowed inverter current consumption (motor torque) for short term (positive values expected)";
CM_ SG_ 672 VCU_INV1_IdcMinShortTerm "maximum allowed inverter current generation (generator torque) for short term (negative values expected)";
CM_ BO_ 704 "Inverter1 Control Frame - Speed / Torque Controller Settings";
CM_ SG_ 704 VCU_INV1_TrqThresholdDampgCtl "Threshold torque for activation of damping control";
CM_ SG_ 704 VCU_INV1_MaxTorqueDampgCtl "Maximum torque active damping control";
CM_ SG_ 704 Checksum_2C0 "Checksum signal for frame";
CM_ SG_ 704 MessageCounter_2C0 "Message counter signal for frame";
CM_ SG_ 704 VCU_INV1_MinTorqueLimit "Lower limit output torque of electric machine";
CM_ SG_ 704 VCU_INV1_MaxTorqueGradient "Maximum allowed change rate of actual torque";
CM_ SG_ 704 VCU_INV1_MaxTorqueLimit "Upper limit output torque of electric machine";
CM_ BO_ 256 "Inverter1 Control Frame - Set-Points for Operation";
CM_ SG_ 256 VCU_INV1_ParkLockUnlockRequest "Lock or unlock request to park lock system";
CM_ SG_ 256 VCU_INV1_SurgeDamperFactor "Calculation factor for surge damper";
CM_ SG_ 256 VCU_INV1_SurgeDamperState "Requested surge damper state";
CM_ SG_ 256 Checksum_100 "Checksum signal for frame";
CM_ SG_ 256 MessageCounter_100 "Message counter signal for frame";
CM_ SG_ 256 VCU_INV1_DesiredSpeed "Desired speed electric machine";
CM_ SG_ 256 VCU_INV1_RequestedState "Request to the electric machine";
CM_ SG_ 256 VCU_INV1_UdcSetP "Setpoint voltage E-Machine";
CM_ SG_ 256 VCU_INV1_DesiredTorque "Desired torque electric machine";
CM_ SG_ 1536 OBC_DataVerLo "Data version low address";
CM_ SG_ 1536 OBC_DataVerHi "Data version high address";
CM_ SG_ 1536 OBC_SwVersion "Software version";
CM_ SG_ 1536 OBC_FailCode "Failure code";
CM_ SG_ 1637 DDC_UDcHiSide "Output voltage on the HV side";
CM_ SG_ 1637 DDC_IDcHiSide "Output current on the HV side";
CM_ SG_ 384 DDC_St "Operating mode DDC";
CM_ SG_ 384 DDC_UDcLoSide "Measured voltage on DDC LV side";
CM_ SG_ 384 DDC_IDcMaxLoSide "Maximum available output current from the DDC to the LV side";
CM_ SG_ 384 DDC_IDcLoSide "Output current on the LV side";
CM_ SG_ 357 Tester_DDC_DesMod "Signal requesting the DDC to be activated afterconditions are fullfilled";
CM_ SG_ 357 Tester_DDC_UDcDes "Requested Charging voltage from Voltage Control";
CM_ SG_ 533 Tester_OBC_ChrgUDcSetP "Requested Charging current";
CM_ SG_ 533 Tester_OBC_ChrgIDcSetP "Requested Charging voltage";
CM_ SG_ 533 Tester_OBC_ChrgDesMod "Signal requesting the OBC Charging";
CM_ SG_ 640 Tester_ELK_Des "Command of E-lock ";
CM_ SG_ 560 OBC_InsulationFault "Indicator of insulation fault";
CM_ SG_ 560 OBC_DischrgCCSt "Status of the discharger connection to the grid";
CM_ SG_ 560 OBC_DischrgCPSt "Status of S2";
CM_ SG_ 560 OBC_uAcRms "Actual input voltage OBC";
CM_ SG_ 560 OBC_iAcRms "Actual input current of OBC";
CM_ SG_ 560 OBC_IDcMax "Maximum available output current from the OBC to the HV side";
CM_ SG_ 560 OBC_TSocket "Temperature of AC vehicle inlet";
CM_ SG_ 549 OBC_UDc "Output voltage of charger";
CM_ SG_ 549 OBC_IDc "Output current of charger";
CM_ SG_ 549 OBC_TCoolr "Temperature of the onboard charger";
CM_ SG_ 549 OBC_ChrgCPSt "Status of the Onboard Charger PwrAvl from the grid";
CM_ SG_ 549 OBC_ChrgCCSt "Status of the Onboard Charger connection to the grid";
CM_ SG_ 549 OBC_Elk_St "State of E-lock";
CM_ SG_ 549 OBC_St "State of the charger";
CM_ SG_ 280 InhibitRecuprationAbsStatus "Recupration Request Status";
CM_ SG_ 280 InhibitRecuprationAbs "Recupration Request";
CM_ SG_ 730 AcclrmInfoZ "Z-axis accelerometer signal value published by TCU to VCU";
CM_ SG_ 730 AcclrmInfoY "Y-axis accelerometer signal value published by TCU to VCU";
CM_ SG_ 730 AcclrmInfoXYZStatus "States plausibility of the signal AccelerometerInfo ";
CM_ SG_ 730 AcclrmInfoX "X-axis accelerometer signal value published by TCU to VCU";
CM_ SG_ 731 GyroInfoZ "Z- axis gyroscope signal value published by TCU to VCU";
CM_ SG_ 731 GyroInfoY "Y- axis gyroscope signal value published by TCU to VCU";
CM_ SG_ 731 GyroInfoXYZStatus "Gyroscope signal  Status value published by TCU";
CM_ SG_ 731 GyroInfoX "X- axis gyroscope signal value published by TCU to VCU";
CM_ SG_ 582 HvBattPwrConsmp "HV Battery Power Consumption";
CM_ SG_ 582 AvgEnergyConsmpTripBStatus "Average Energy Consumption for Trip B Status";
CM_ SG_ 582 AvgEnergyConsmpTripAStatus "Average Energy Consumption for Trip A Status";
CM_ SG_ 582 AvgEnergyConsmpTripB "Average Energy Consumption for Trip B";
CM_ SG_ 582 AvgEnergyConsmpTripA "Average Energy Consumption for Trip A";
CM_ SG_ 582 InstPwrConsumpStatus "Instantaneous Power Consumption Status";
CM_ SG_ 582 InstPwrConsump "Instantaneous Power Consumption";
CM_ SG_ 719 PtcHtrForcedCutoff "This signal shall be used as a master control signal for PTC driving. ";
CM_ BO_ 1142 "Supervision frame transmitted by VCU.";
CM_ SG_ 1142 PEPS_Invalid_failure_status "Status of the PEPS invalid failure detected as per Tata-IVN_Specification_Network_Management.";
CM_ SG_ 1142 Telematics_MTO_Failure_status "Status of the Telematics Message timeout failure detected as per Tata-IVN_Specification_Network_Management.";
CM_ SG_ 1142 Telematics_Invalid_FailureStatus "Status of the Telematics Invalid failure detected as per Tata-IVN_Specification_Network_Management.";
CM_ SG_ 1142 SRS_MTO_Failure_Status "Status of the SRS  Message timeout  failure detected as per Tata-IVN_Specification_Network_Management.";
CM_ SG_ 1142 PEPS_MTO_Failure_Status "Status of the PEPS  Message timeout  failure detected as per Tata-IVN_Specification_Network_Management.";
CM_ SG_ 1142 IPcMToFailureStatus "Status of the IPC Message Timeout  failure detected as per Tata-IVN_Specification_Network_Management.";
CM_ SG_ 1142 IPcInvalidFailureStatus "Status of the IC Invalid  signal  failure detected as per Tata-IVN_Specification_Network_Management.";
CM_ SG_ 1142 ABsMToFailureStatus "Status of the ESP  Message timeout failure detected as per Tata-IVN_Specification_Network_Management.";
CM_ SG_ 1142 ABsInvalidFailureStatus "Status of the ESP signal implausible  failure detected  by EPAS  as per  communication layer spec";
CM_ SG_ 1142 VCU_SW_Version "software Version of VCU ECU";
CM_ SG_ 1142 VCU_Err_State_Trans_Cntr "Number of state transitions from bus ON to bus OFF state. Reset this value to Zero in each new Ignition cycle. Freeze this value to 65535 if number of state transitions are more than this value in a given Ignition cycle.";
CM_ SG_ 1142 VCU_EP_Failure_Status "Status of the error-passive failure detected by VCU ECU as per Tata-IVN_Specification_Network_Management.";
CM_ SG_ 1142 VCU_BO_Failure_Status "Status of the bus off failure detected by VCU  ECU as per Tata-IVN_Specification_Network_Management.";
CM_ SG_ 1142 GSS_EV_Invalid_Failure_Status "Invalid failure status of GSS";
CM_ SG_ 1142 GSS_EV_MTO_Failure_Status "Status of the GSS messege timeout";
CM_ SG_ 1142 CCM_MTO_Failure_Status "Status of the FATC Message timeout failure detected as per Tata-IVN_Specification_Network_Management.";
CM_ SG_ 1142 CCM_Invalid_Failure_Status "Status of the  FATC Invalid  signal  failure detected as per Tata-IVN_Specification_Network_Management.";
CM_ SG_ 1142 BCmInvalidFailureStatus "BCM Invalid Failure Status";
CM_ SG_ 1142 BCmMToFailureStatus "Status of the BCM Message timeout  failure detected as per Tata-IVN_Specification_Network_Management.";
CM_ SG_ 581 CoolingPwrFdbkVal "This signal is used to indicate the actual value of Cooling Power honored by VCU.";
CM_ SG_ 581 HeatingPwrFdbkVal "This signal is used to indicate the actual value of Heating Power honored by VCU.
";
CM_ SG_ 581 CabinCoolingSolValveStateStatus "Cabin Cooling Solenoid Valve Signal Status";
CM_ SG_ 581 CabinCoolingSolValveState "Cabin Cooling Solenoid Valve Signal";
CM_ SG_ 581 LowHVBatteryChargeStatus "Low HV Battery Charge Status";
CM_ SG_ 581 LowHVBatteryCharge "Low HV Battery Charge";
CM_ SG_ 581 LowLVBatteryChargeStatus "Low LV Battery Charge Status";
CM_ SG_ 581 LowLVBatteryCharge "Low LV Battery Charge";
CM_ SG_ 581 HvAmpHrStatus "HV Battery Charge Status";
CM_ SG_ 581 HvAmpHr "HV Battery Charge";
CM_ SG_ 703 OATICSigNewStatus "Signal represents Status of OATSig";
CM_ SG_ 703 OATICSigNew "Signal represents Outside Ambient Temperature raw value evaluated by Instrument Cluster 
";
BA_DEF_ SG_  "SignalType" STRING ;
BA_DEF_ SG_  "Remarks" STRING ;
BA_DEF_ SG_  "NWM_WakeupAllowed" ENUM  "No","Yes";
BA_DEF_ SG_  "GenSigTimeoutTime_HU_Mid_X451" INT 0 65535;
BA_DEF_ SG_  "GenSigTimeoutTime_HU_High_X451" INT 0 65535;
BA_DEF_ SG_  "GenSigTimeoutTime_HU_B" INT 0 65535;
BA_DEF_ SG_  "GenSigTimeoutTime_HU_A" INT 0 65535;
BA_DEF_ SG_  "GenSigTimeoutTime_BCM_Mid" INT 0 65535;
BA_DEF_ SG_  "GenSigTimeoutMsg_HU_Mid_X451" INT 0 65535;
BA_DEF_ SG_  "GenSigTimeoutMsg_HU_High_X451" INT 0 65535;
BA_DEF_ SG_  "GenSigTimeoutMsg_HU_B" INT 0 65535;
BA_DEF_ SG_  "GenSigTimeoutMsg_HU_A" INT 0 65535;
BA_DEF_ SG_  "GenSigStartValue" INT -2147483648 2147483647;
BA_DEF_ SG_  "GenSigSendType" ENUM  "Cyclic","OnWrite","OnWriteWithRepetition","OnChange","OnChangeWithRepetition","IfActive","IfActiveWithRepetition","NoSigSendType","NotUsed","NotUsed","NotUsed","NotUsed","NotUsed";
BA_DEF_ SG_  "GenSigInactiveValue" INT 0 0;
BA_DEF_ SG_  "GenSigEnvVarType" ENUM  "int","float","undef";
BA_DEF_ SG_  "GenSigCycleTimeActive" INT 0 0;
BA_DEF_ SG_  "GenSigCycleTime" INT 0 0;
BA_DEF_ SG_  "GenSigTimeoutMsg_HU_High_X445" INT 0 65535;
BA_DEF_ SG_  "GenSigTimeoutMsg_HU_Mid_X445" INT 0 65535;
BA_DEF_ SG_  "GenSigTimeoutTime_HU_High_X445" INT 0 65535;
BA_DEF_ SG_  "GenSigTimeoutTime_HU_Mid_X445" INT 0 65535;
BA_DEF_ BO_  "NmMessage" ENUM  "no","yes";
BA_DEF_ BO_  "NmAsrMessage" ENUM  "<n.a.>","No","Yes";
BA_DEF_ BO_  "MessageTimeout" INT 0 65535;
BA_DEF_ BO_  "GenMsgStartDelayTime" INT 0 0;
BA_DEF_ BO_  "GenMsgSendType" ENUM  "Cyclic","Event","Mixed","cyclicX","not_used","not_used","not_used","not_used","NoMsgSendType";
BA_DEF_ BO_  "GenMsgNrOfRepetition" INT 0 0;
BA_DEF_ BO_  "GenMsgILSupport" ENUM  "No","Yes";
BA_DEF_ BO_  "GenMsgCycleTimeFast" INT 0 0;
BA_DEF_ BO_  "GenMsgCycleTime" INT 0 65535;
BA_DEF_ BO_  "DiagUudtResponse" ENUM  "false","true";
BA_DEF_ BO_  "DiagUsdtResponse" ENUM  "false","true";
BA_DEF_ BO_  "DiagResponse" ENUM  "No","Yes";
BA_DEF_ BO_  "DiagRequest" ENUM  "No","Yes";
BA_DEF_ BU_  "NodeLayerModules" STRING ;
BA_DEF_ BU_  "NmStationAddress" INT 0 63;
BA_DEF_ BU_  "NmCAN" INT 1 3;
BA_DEF_ BU_  "NmAsrNodeIdentifier" HEX 0 255;
BA_DEF_ BU_  "NmAsrNode" ENUM  "<n.a.>","No","Yes";
BA_DEF_ BU_  "NmAsrCanMsgReducedTime" INT 1 65535;
BA_DEF_ BU_  "ECU" STRING ;
BA_DEF_  "NmType" STRING ;
BA_DEF_  "NmMessageCount" INT 0 128;
BA_DEF_  "NmAsrWaitBusSleepTime" INT 1 65535;
BA_DEF_  "NmAsrTimeoutTime" INT 1 65535;
BA_DEF_  "NmAsrRepeatMessageTime" INT 1 65535;
BA_DEF_  "NmAsrMessageCount" INT 128 128;
BA_DEF_  "NmAsrCanMsgCycleTime" INT 1 65535;
BA_DEF_  "NmAsrBaseAddress" HEX 0 2047;
BA_DEF_  "Manufacturer" STRING ;
BA_DEF_  "ILTxTimeout" INT 0 65535;
BA_DEF_  "GenEnvVarPrefix" STRING ;
BA_DEF_  "GenEnvVarEndingSnd" STRING ;
BA_DEF_  "GenEnvVarEndingDsp" STRING ;
BA_DEF_  "DBName" STRING ;
BA_DEF_  "Baudrate" INT 0 1000000;
BA_DEF_DEF_  "SignalType" "";
BA_DEF_DEF_  "Remarks" "null";
BA_DEF_DEF_  "NWM_WakeupAllowed" "No";
BA_DEF_DEF_  "GenSigTimeoutTime_HU_Mid_X451" 500;
BA_DEF_DEF_  "GenSigTimeoutTime_HU_High_X451" 500;
BA_DEF_DEF_  "GenSigTimeoutTime_HU_B" 500;
BA_DEF_DEF_  "GenSigTimeoutTime_HU_A" 500;
BA_DEF_DEF_  "GenSigTimeoutTime_BCM_Mid" 0;
BA_DEF_DEF_  "GenSigTimeoutMsg_HU_Mid_X451" 500;
BA_DEF_DEF_  "GenSigTimeoutMsg_HU_High_X451" 500;
BA_DEF_DEF_  "GenSigTimeoutMsg_HU_B" 500;
BA_DEF_DEF_  "GenSigTimeoutMsg_HU_A" 500;
BA_DEF_DEF_  "GenSigStartValue" 0;
BA_DEF_DEF_  "GenSigSendType" "Cyclic";
BA_DEF_DEF_  "GenSigInactiveValue" 0;
BA_DEF_DEF_  "GenSigEnvVarType" "undef";
BA_DEF_DEF_  "GenSigCycleTimeActive" 0;
BA_DEF_DEF_  "GenSigCycleTime" 0;
BA_DEF_DEF_  "GenSigTimeoutMsg_HU_High_X445" 500;
BA_DEF_DEF_  "GenSigTimeoutMsg_HU_Mid_X445" 500;
BA_DEF_DEF_  "GenSigTimeoutTime_HU_High_X445" 500;
BA_DEF_DEF_  "GenSigTimeoutTime_HU_Mid_X445" 500;
BA_DEF_DEF_  "NmMessage" "no";
BA_DEF_DEF_  "NmAsrMessage" "<n.a.>";
BA_DEF_DEF_  "MessageTimeout" 500;
BA_DEF_DEF_  "GenMsgStartDelayTime" 0;
BA_DEF_DEF_  "GenMsgSendType" "NoMsgSendType";
BA_DEF_DEF_  "GenMsgNrOfRepetition" 0;
BA_DEF_DEF_  "GenMsgILSupport" "Yes";
BA_DEF_DEF_  "GenMsgCycleTimeFast" 0;
BA_DEF_DEF_  "GenMsgCycleTime" 0;
BA_DEF_DEF_  "DiagUudtResponse" "false";
BA_DEF_DEF_  "DiagUsdtResponse" "false";
BA_DEF_DEF_  "DiagResponse" "No";
BA_DEF_DEF_  "DiagRequest" "No";
BA_DEF_DEF_  "NodeLayerModules" "null";
BA_DEF_DEF_  "NmStationAddress" 0;
BA_DEF_DEF_  "NmCAN" 3;
BA_DEF_DEF_  "NmAsrNodeIdentifier" 2;
BA_DEF_DEF_  "NmAsrNode" "<n.a.>";
BA_DEF_DEF_  "NmAsrCanMsgReducedTime" 50;
BA_DEF_DEF_  "ECU" "";
BA_DEF_DEF_  "NmType" "NmAsr";
BA_DEF_DEF_  "NmMessageCount" 128;
BA_DEF_DEF_  "NmAsrWaitBusSleepTime" 500;
BA_DEF_DEF_  "NmAsrTimeoutTime" 1000;
BA_DEF_DEF_  "NmAsrRepeatMessageTime" 1500;
BA_DEF_DEF_  "NmAsrMessageCount" 128;
BA_DEF_DEF_  "NmAsrCanMsgCycleTime" 200;
BA_DEF_DEF_  "NmAsrBaseAddress" 1280;
BA_DEF_DEF_  "Manufacturer" "TML";
BA_DEF_DEF_  "ILTxTimeout" 500;
BA_DEF_DEF_  "GenEnvVarPrefix" "Env";
BA_DEF_DEF_  "GenEnvVarEndingSnd" "_";
BA_DEF_DEF_  "GenEnvVarEndingDsp" "Dsp_";
BA_DEF_DEF_  "DBName" "null";
BA_DEF_DEF_  "Baudrate" 500000;
BA_ "NmMessageCount" 0;
BA_ "DBName" "CANBus_1";
BA_ "ECU" BU_ VCU "VCU";
BA_ "GenMsgCycleTime" BO_ 944 100;
BA_ "GenMsgSendType" BO_ 944 0;
BA_ "GenMsgCycleTime" BO_ 688 100;
BA_ "GenMsgSendType" BO_ 688 0;
BA_ "GenMsgCycleTime" BO_ 1472 100;
BA_ "GenMsgSendType" BO_ 1472 0;
BA_ "GenMsgCycleTime" BO_ 1456 10;
BA_ "GenMsgSendType" BO_ 1456 1;
BA_ "GenMsgCycleTime" BO_ 512 10;
BA_ "GenMsgSendType" BO_ 512 0;
BA_ "GenMsgCycleTime" BO_ 528 10;
BA_ "GenMsgSendType" BO_ 528 0;
BA_ "GenMsgCycleTime" BO_ 1568 100;
BA_ "GenMsgSendType" BO_ 1568 0;
BA_ "GenMsgCycleTime" BO_ 928 100;
BA_ "GenMsgSendType" BO_ 928 0;
BA_ "GenMsgCycleTime" BO_ 672 10;
BA_ "GenMsgSendType" BO_ 672 0;
BA_ "GenMsgCycleTime" BO_ 704 10;
BA_ "GenMsgSendType" BO_ 704 0;
BA_ "GenMsgCycleTime" BO_ 256 10;
BA_ "GenMsgSendType" BO_ 256 0;
BA_ "GenMsgCycleTime" BO_ 1536 200;
BA_ "GenMsgSendType" BO_ 1536 0;
BA_ "GenMsgCycleTime" BO_ 1637 100;
BA_ "GenMsgSendType" BO_ 1637 0;
BA_ "GenMsgCycleTime" BO_ 384 50;
BA_ "GenMsgSendType" BO_ 384 0;
BA_ "GenMsgCycleTime" BO_ 357 20;
BA_ "GenMsgCycleTime" BO_ 533 100;
BA_ "GenMsgCycleTime" BO_ 640 100;
BA_ "GenMsgSendType" BO_ 640 0;
BA_ "GenMsgCycleTime" BO_ 560 100;
BA_ "GenMsgSendType" BO_ 560 0;
BA_ "GenMsgCycleTime" BO_ 549 100;
BA_ "GenMsgSendType" BO_ 549 0;
BA_ "GenMsgCycleTime" BO_ 1800 100;
BA_ "GenMsgCycleTime" BO_ 1799 100;
BA_ "GenMsgCycleTime" BO_ 1798 100;
BA_ "GenMsgCycleTime" BO_ 1797 100;
BA_ "GenMsgCycleTime" BO_ 1796 100;
BA_ "GenMsgCycleTime" BO_ 1795 10;
BA_ "GenMsgCycleTime" BO_ 1812 100;
BA_ "GenMsgCycleTime" BO_ 1794 100;
BA_ "GenMsgCycleTime" BO_ 1793 10;
BA_ "GenMsgCycleTime" BO_ 1811 100;
BA_ "GenMsgCycleTime" BO_ 1810 100;
BA_ "GenMsgCycleTime" BO_ 1801 100;
BA_ "GenMsgCycleTime" BO_ 1809 100;
BA_ "GenMsgCycleTime" BO_ 1808 100;
BA_ "GenMsgCycleTime" BO_ 701 10;
BA_ "DiagRequest" BO_ 2019 1;
BA_ "GenMsgILSupport" BO_ 2019 0;
BA_ "MessageTimeout" BO_ 2019 0;
BA_ "DiagResponse" BO_ 2027 1;
BA_ "GenMsgILSupport" BO_ 2027 0;
BA_ "MessageTimeout" BO_ 2027 0;
BA_ "GenMsgCycleTime" BO_ 280 10;
BA_ "GenMsgCycleTime" BO_ 730 100;
BA_ "GenMsgCycleTime" BO_ 731 100;
BA_ "GenMsgCycleTime" BO_ 582 100;
BA_ "GenMsgCycleTime" BO_ 719 100;
BA_ "GenMsgCycleTime" BO_ 1142 100;
BA_ "GenMsgSendType" BO_ 1142 0;
BA_ "MessageTimeout" BO_ 1142 0;
BA_ "GenMsgCycleTime" BO_ 581 100;
BA_ "GenMsgCycleTime" BO_ 1288 200;
BA_ "MessageTimeout" BO_ 1288 1000;
BA_ "GenMsgCycleTime" BO_ 1287 200;
BA_ "MessageTimeout" BO_ 1287 1000;
BA_ "GenMsgCycleTime" BO_ 703 100;
BA_ "GenSigStartValue" SG_ 3221225472 HMI_OPD_MaxDeceleration 60;
BA_ "GenSigStartValue" SG_ 944 INV1_MinTrqGbx 1023;
BA_ "GenSigStartValue" SG_ 944 INV1_MaxTrqGbx 1023;
BA_ "GenSigStartValue" SG_ 944 INV1_GbxOilT 254;
BA_ "GenSigStartValue" SG_ 688 VCU_INV1_CoolantFlow 63;
BA_ "GenSigStartValue" SG_ 688 VCU_INV1_TCooltCirc 254;
BA_ "GenSigStartValue" SG_ 512 INV1_Speed 65534;
BA_ "GenSigStartValue" SG_ 512 INV1_CurrentHV 2046;
BA_ "GenSigStartValue" SG_ 512 INV1_VoltageHV 1022;
BA_ "GenSigStartValue" SG_ 512 INV1_OutputTorque 2046;
BA_ "GenSigStartValue" SG_ 528 INV1_MinCoolantFlow 63;
BA_ "GenSigStartValue" SG_ 528 INV1_ParkLockStatus 3;
BA_ "GenSigStartValue" SG_ 528 INV1_MaxTorque 1023;
BA_ "GenSigStartValue" SG_ 528 INV1_MinTorque 1023;
BA_ "GenSigStartValue" SG_ 528 INV1_TrqWoDstC 2046;
BA_ "GenSigStartValue" SG_ 528 INV1_TempCoolant 254;
BA_ "GenSigStartValue" SG_ 1568 INV1_StatorTemperature 510;
BA_ "GenSigStartValue" SG_ 1568 INV1_InverterTemperature 254;
BA_ "GenSigStartValue" SG_ 1568 INV1_RotorTemperature 510;
BA_ "GenSigStartValue" SG_ 928 INV1_MaxTorqueLongTerm 1023;
BA_ "GenSigStartValue" SG_ 928 INV1_MinTorqueLongTerm 1023;
BA_ "GenSigStartValue" SG_ 928 INV1_MaxTorqueShortTerm 1023;
BA_ "GenSigStartValue" SG_ 928 INV1_MinTorqueShortTerm 1023;
BA_ "GenSigStartValue" SG_ 672 VCU_INV1_IdcMinLongTerm 2046;
BA_ "GenSigStartValue" SG_ 672 VCU_INV1_IdcMaxLongTerm 2046;
BA_ "GenSigStartValue" SG_ 672 VCU_INV1_IdcMaxShortTerm 2046;
BA_ "GenSigStartValue" SG_ 672 VCU_INV1_IdcMinShortTerm 2046;
BA_ "GenSigStartValue" SG_ 704 VCU_INV1_MaxTorqueDampgCtl 254;
BA_ "GenSigStartValue" SG_ 704 VCU_INV1_MinTorqueLimit 2046;
BA_ "GenSigStartValue" SG_ 704 VCU_INV1_MaxTorqueGradient 16382;
BA_ "GenSigStartValue" SG_ 704 VCU_INV1_MaxTorqueLimit 2046;
BA_ "GenSigStartValue" SG_ 1637 DDC_UDcHiSide 200;
BA_ "GenSigStartValue" SG_ 560 OBC_TSocket 40;
BA_ "GenSigStartValue" SG_ 549 OBC_IDc 500;
BA_ "GenSigStartValue" SG_ 549 OBC_TCoolr 40;
BA_ "SignalType" SG_ 1799 BMUFault "ENM";
BA_ "SignalType" SG_ 1799 LowVoltSupplyAlarm "ENM";
BA_ "SignalType" SG_ 1799 PrechargeFaultAlarm "ENM";
BA_ "SignalType" SG_ 1799 BattDischrgOverCurrAlarm "ENM";
BA_ "SignalType" SG_ 1799 BattFBOverCurrAlarm "ENM";
BA_ "SignalType" SG_ 1799 SOCJump "ENM";
BA_ "SignalType" SG_ 1799 SOCLowAlarm "ENM";
BA_ "SignalType" SG_ 1799 InsulationFault "ENM";
BA_ "SignalType" SG_ 1799 PosMainRlyConglut "ENM";
BA_ "SignalType" SG_ 1799 CAN3CommAlarm "ENM";
BA_ "SignalType" SG_ 1799 CAN1CommAlarm "ENM";
BA_ "SignalType" SG_ 1799 TotalBattVoltUnderAlarm "ENM";
BA_ "SignalType" SG_ 1799 BattUnderTempAlarm "ENM";
BA_ "SignalType" SG_ 1799 NegMainRlyConglut "ENM";
BA_ "SignalType" SG_ 1799 HVILAlarm "ENM";
BA_ "SignalType" SG_ 1799 TotalBattVoltOverAlarm "ENM";
BA_ "SignalType" SG_ 1799 BattHighTempAlarm "ENM";
BA_ "SignalType" SG_ 1799 SOCHighAlarm "ENM";
BA_ "SignalType" SG_ 1799 CellVoltDiffOverAlarm "ENM";
BA_ "SignalType" SG_ 1799 CellTempDiffOverAlarm "ENM";
BA_ "SignalType" SG_ 1799 MinCellVoltUnderAlarm "ENM";
BA_ "SignalType" SG_ 1799 MaxCellVoltOverAlarm "ENM";
BA_ "SignalType" SG_ 1795 PreRlyClsd "ENM";
BA_ "SignalType" SG_ 1795 MaiRlyPClsd "ENM";
BA_ "SignalType" SG_ 1795 MaiRlyNClsd "ENM";
BA_ "SignalType" SG_ 1793 HVILDetect "ENM";
BA_ "SignalType" SG_ 1793 Charging_Flag "ENM";
BA_ "SignalType" SG_ 1793 BMSModeReq "ENM";
BA_ "SignalType" SG_ 1793 HSC_BCM_LEAKAGE_ENA "ENM";
BA_ "SignalType" SG_ 1793 EqualizationTrigger "ENM";
BA_ "SignalType" SG_ 1801 BMS_DerateFlag "ENM";
BA_ "SignalType" SG_ 1801 SOC_CalibrationFlag "ENM";
BA_ "SignalType" SG_ 1801 OperMod "ENM";
BA_ "SignalType" SG_ 1801 FltRank "ENM";
BA_ "SignalType" SG_ 1808 InsulatnDetect_OFF_Fdbk "ENM";
BA_ "GenSigTimeoutTime_HU_Mid_X445" SG_ 2019 VCU_DiagRequest 0;
BA_ "GenSigTimeoutTime_HU_High_X445" SG_ 2019 VCU_DiagRequest 0;
BA_ "GenSigTimeoutMsg_HU_Mid_X445" SG_ 2019 VCU_DiagRequest 0;
BA_ "GenSigTimeoutMsg_HU_High_X445" SG_ 2019 VCU_DiagRequest 0;
BA_ "GenSigSendType" SG_ 2019 VCU_DiagRequest 1;
BA_ "GenSigTimeoutMsg_HU_A" SG_ 2019 VCU_DiagRequest 0;
BA_ "GenSigTimeoutMsg_HU_B" SG_ 2019 VCU_DiagRequest 0;
BA_ "GenSigTimeoutMsg_HU_High_X451" SG_ 2019 VCU_DiagRequest 0;
BA_ "GenSigTimeoutMsg_HU_Mid_X451" SG_ 2019 VCU_DiagRequest 0;
BA_ "GenSigTimeoutTime_HU_A" SG_ 2019 VCU_DiagRequest 0;
BA_ "GenSigTimeoutTime_HU_B" SG_ 2019 VCU_DiagRequest 0;
BA_ "GenSigTimeoutTime_HU_High_X451" SG_ 2019 VCU_DiagRequest 0;
BA_ "GenSigTimeoutTime_HU_Mid_X451" SG_ 2019 VCU_DiagRequest 0;
BA_ "GenSigTimeoutTime_HU_Mid_X445" SG_ 2027 VCU_DiagResponse_USDT 0;
BA_ "GenSigTimeoutTime_HU_High_X445" SG_ 2027 VCU_DiagResponse_USDT 0;
BA_ "GenSigTimeoutMsg_HU_Mid_X445" SG_ 2027 VCU_DiagResponse_USDT 0;
BA_ "GenSigTimeoutMsg_HU_High_X445" SG_ 2027 VCU_DiagResponse_USDT 0;
BA_ "GenSigSendType" SG_ 2027 VCU_DiagResponse_USDT 1;
BA_ "GenSigTimeoutMsg_HU_A" SG_ 2027 VCU_DiagResponse_USDT 0;
BA_ "GenSigTimeoutMsg_HU_B" SG_ 2027 VCU_DiagResponse_USDT 0;
BA_ "GenSigTimeoutMsg_HU_High_X451" SG_ 2027 VCU_DiagResponse_USDT 0;
BA_ "GenSigTimeoutMsg_HU_Mid_X451" SG_ 2027 VCU_DiagResponse_USDT 0;
BA_ "GenSigTimeoutTime_HU_A" SG_ 2027 VCU_DiagResponse_USDT 0;
BA_ "GenSigTimeoutTime_HU_B" SG_ 2027 VCU_DiagResponse_USDT 0;
BA_ "GenSigTimeoutTime_HU_High_X451" SG_ 2027 VCU_DiagResponse_USDT 0;
BA_ "GenSigTimeoutTime_HU_Mid_X451" SG_ 2027 VCU_DiagResponse_USDT 0;
BA_ "GenSigTimeoutTime_HU_Mid_X445" SG_ 280 InhibitRecuprationAbsStatus 0;
BA_ "GenSigTimeoutTime_HU_High_X445" SG_ 280 InhibitRecuprationAbsStatus 0;
BA_ "GenSigTimeoutMsg_HU_Mid_X445" SG_ 280 InhibitRecuprationAbsStatus 0;
BA_ "GenSigTimeoutMsg_HU_High_X445" SG_ 280 InhibitRecuprationAbsStatus 0;
BA_ "GenSigCycleTime" SG_ 280 InhibitRecuprationAbsStatus 10;
BA_ "GenSigCycleTimeActive" SG_ 280 InhibitRecuprationAbsStatus 10;
BA_ "GenSigSendType" SG_ 280 InhibitRecuprationAbsStatus 7;
BA_ "GenSigTimeoutMsg_HU_A" SG_ 280 InhibitRecuprationAbsStatus 0;
BA_ "GenSigTimeoutMsg_HU_B" SG_ 280 InhibitRecuprationAbsStatus 0;
BA_ "GenSigTimeoutMsg_HU_High_X451" SG_ 280 InhibitRecuprationAbsStatus 0;
BA_ "GenSigTimeoutMsg_HU_Mid_X451" SG_ 280 InhibitRecuprationAbsStatus 0;
BA_ "GenSigTimeoutTime_HU_A" SG_ 280 InhibitRecuprationAbsStatus 0;
BA_ "GenSigTimeoutTime_HU_B" SG_ 280 InhibitRecuprationAbsStatus 0;
BA_ "GenSigTimeoutTime_HU_High_X451" SG_ 280 InhibitRecuprationAbsStatus 0;
BA_ "GenSigTimeoutTime_HU_Mid_X451" SG_ 280 InhibitRecuprationAbsStatus 0;
BA_ "GenSigTimeoutTime_HU_Mid_X445" SG_ 280 InhibitRecuprationAbs 0;
BA_ "GenSigTimeoutTime_HU_High_X445" SG_ 280 InhibitRecuprationAbs 0;
BA_ "GenSigTimeoutMsg_HU_Mid_X445" SG_ 280 InhibitRecuprationAbs 0;
BA_ "GenSigTimeoutMsg_HU_High_X445" SG_ 280 InhibitRecuprationAbs 0;
BA_ "GenSigCycleTime" SG_ 280 InhibitRecuprationAbs 10;
BA_ "GenSigCycleTimeActive" SG_ 280 InhibitRecuprationAbs 10;
BA_ "GenSigSendType" SG_ 280 InhibitRecuprationAbs 7;
BA_ "GenSigTimeoutMsg_HU_A" SG_ 280 InhibitRecuprationAbs 0;
BA_ "GenSigTimeoutMsg_HU_B" SG_ 280 InhibitRecuprationAbs 0;
BA_ "GenSigTimeoutMsg_HU_High_X451" SG_ 280 InhibitRecuprationAbs 0;
BA_ "GenSigTimeoutMsg_HU_Mid_X451" SG_ 280 InhibitRecuprationAbs 0;
BA_ "GenSigTimeoutTime_HU_A" SG_ 280 InhibitRecuprationAbs 0;
BA_ "GenSigTimeoutTime_HU_B" SG_ 280 InhibitRecuprationAbs 0;
BA_ "GenSigTimeoutTime_HU_High_X451" SG_ 280 InhibitRecuprationAbs 0;
BA_ "GenSigTimeoutTime_HU_Mid_X451" SG_ 280 InhibitRecuprationAbs 0;
BA_ "GenSigTimeoutTime_HU_Mid_X445" SG_ 730 AcclrmInfoZ 0;
BA_ "GenSigTimeoutTime_HU_High_X445" SG_ 730 AcclrmInfoZ 0;
BA_ "GenSigTimeoutMsg_HU_Mid_X445" SG_ 730 AcclrmInfoZ 0;
BA_ "GenSigTimeoutMsg_HU_High_X445" SG_ 730 AcclrmInfoZ 0;
BA_ "GenSigCycleTime" SG_ 730 AcclrmInfoZ 100;
BA_ "GenSigCycleTimeActive" SG_ 730 AcclrmInfoZ 100;
BA_ "GenSigSendType" SG_ 730 AcclrmInfoZ 7;
BA_ "GenSigStartValue" SG_ 730 AcclrmInfoZ 30000;
BA_ "GenSigTimeoutMsg_HU_A" SG_ 730 AcclrmInfoZ 0;
BA_ "GenSigTimeoutMsg_HU_B" SG_ 730 AcclrmInfoZ 0;
BA_ "GenSigTimeoutMsg_HU_High_X451" SG_ 730 AcclrmInfoZ 0;
BA_ "GenSigTimeoutMsg_HU_Mid_X451" SG_ 730 AcclrmInfoZ 0;
BA_ "GenSigTimeoutTime_HU_A" SG_ 730 AcclrmInfoZ 0;
BA_ "GenSigTimeoutTime_HU_B" SG_ 730 AcclrmInfoZ 0;
BA_ "GenSigTimeoutTime_HU_High_X451" SG_ 730 AcclrmInfoZ 0;
BA_ "GenSigTimeoutTime_HU_Mid_X451" SG_ 730 AcclrmInfoZ 0;
BA_ "GenSigTimeoutTime_HU_Mid_X445" SG_ 730 AcclrmInfoY 0;
BA_ "GenSigTimeoutTime_HU_High_X445" SG_ 730 AcclrmInfoY 0;
BA_ "GenSigTimeoutMsg_HU_Mid_X445" SG_ 730 AcclrmInfoY 0;
BA_ "GenSigTimeoutMsg_HU_High_X445" SG_ 730 AcclrmInfoY 0;
BA_ "GenSigCycleTime" SG_ 730 AcclrmInfoY 100;
BA_ "GenSigCycleTimeActive" SG_ 730 AcclrmInfoY 100;
BA_ "GenSigSendType" SG_ 730 AcclrmInfoY 7;
BA_ "GenSigStartValue" SG_ 730 AcclrmInfoY 30000;
BA_ "GenSigTimeoutMsg_HU_A" SG_ 730 AcclrmInfoY 0;
BA_ "GenSigTimeoutMsg_HU_B" SG_ 730 AcclrmInfoY 0;
BA_ "GenSigTimeoutMsg_HU_High_X451" SG_ 730 AcclrmInfoY 0;
BA_ "GenSigTimeoutMsg_HU_Mid_X451" SG_ 730 AcclrmInfoY 0;
BA_ "GenSigTimeoutTime_HU_A" SG_ 730 AcclrmInfoY 0;
BA_ "GenSigTimeoutTime_HU_B" SG_ 730 AcclrmInfoY 0;
BA_ "GenSigTimeoutTime_HU_High_X451" SG_ 730 AcclrmInfoY 0;
BA_ "GenSigTimeoutTime_HU_Mid_X451" SG_ 730 AcclrmInfoY 0;
BA_ "GenSigTimeoutTime_HU_Mid_X445" SG_ 730 AcclrmInfoXYZStatus 0;
BA_ "GenSigTimeoutTime_HU_High_X445" SG_ 730 AcclrmInfoXYZStatus 0;
BA_ "GenSigTimeoutMsg_HU_Mid_X445" SG_ 730 AcclrmInfoXYZStatus 0;
BA_ "GenSigTimeoutMsg_HU_High_X445" SG_ 730 AcclrmInfoXYZStatus 0;
BA_ "GenSigCycleTime" SG_ 730 AcclrmInfoXYZStatus 100;
BA_ "GenSigCycleTimeActive" SG_ 730 AcclrmInfoXYZStatus 100;
BA_ "GenSigSendType" SG_ 730 AcclrmInfoXYZStatus 7;
BA_ "GenSigTimeoutMsg_HU_A" SG_ 730 AcclrmInfoXYZStatus 0;
BA_ "GenSigTimeoutMsg_HU_B" SG_ 730 AcclrmInfoXYZStatus 0;
BA_ "GenSigTimeoutMsg_HU_High_X451" SG_ 730 AcclrmInfoXYZStatus 0;
BA_ "GenSigTimeoutMsg_HU_Mid_X451" SG_ 730 AcclrmInfoXYZStatus 0;
BA_ "GenSigTimeoutTime_HU_A" SG_ 730 AcclrmInfoXYZStatus 0;
BA_ "GenSigTimeoutTime_HU_B" SG_ 730 AcclrmInfoXYZStatus 0;
BA_ "GenSigTimeoutTime_HU_High_X451" SG_ 730 AcclrmInfoXYZStatus 0;
BA_ "GenSigTimeoutTime_HU_Mid_X451" SG_ 730 AcclrmInfoXYZStatus 0;
BA_ "GenSigTimeoutTime_HU_Mid_X445" SG_ 730 AcclrmInfoX 0;
BA_ "GenSigTimeoutTime_HU_High_X445" SG_ 730 AcclrmInfoX 0;
BA_ "GenSigTimeoutMsg_HU_Mid_X445" SG_ 730 AcclrmInfoX 0;
BA_ "GenSigTimeoutMsg_HU_High_X445" SG_ 730 AcclrmInfoX 0;
BA_ "GenSigCycleTime" SG_ 730 AcclrmInfoX 100;
BA_ "GenSigCycleTimeActive" SG_ 730 AcclrmInfoX 100;
BA_ "GenSigSendType" SG_ 730 AcclrmInfoX 7;
BA_ "GenSigStartValue" SG_ 730 AcclrmInfoX 30000;
BA_ "GenSigTimeoutMsg_HU_A" SG_ 730 AcclrmInfoX 0;
BA_ "GenSigTimeoutMsg_HU_B" SG_ 730 AcclrmInfoX 0;
BA_ "GenSigTimeoutMsg_HU_High_X451" SG_ 730 AcclrmInfoX 0;
BA_ "GenSigTimeoutMsg_HU_Mid_X451" SG_ 730 AcclrmInfoX 0;
BA_ "GenSigTimeoutTime_HU_A" SG_ 730 AcclrmInfoX 0;
BA_ "GenSigTimeoutTime_HU_B" SG_ 730 AcclrmInfoX 0;
BA_ "GenSigTimeoutTime_HU_High_X451" SG_ 730 AcclrmInfoX 0;
BA_ "GenSigTimeoutTime_HU_Mid_X451" SG_ 730 AcclrmInfoX 0;
BA_ "GenSigTimeoutTime_HU_Mid_X445" SG_ 731 GyroInfoZ 0;
BA_ "GenSigTimeoutTime_HU_High_X445" SG_ 731 GyroInfoZ 0;
BA_ "GenSigTimeoutMsg_HU_Mid_X445" SG_ 731 GyroInfoZ 0;
BA_ "GenSigTimeoutMsg_HU_High_X445" SG_ 731 GyroInfoZ 0;
BA_ "GenSigCycleTime" SG_ 731 GyroInfoZ 100;
BA_ "GenSigCycleTimeActive" SG_ 731 GyroInfoZ 100;
BA_ "GenSigSendType" SG_ 731 GyroInfoZ 7;
BA_ "GenSigStartValue" SG_ 731 GyroInfoZ 20000;
BA_ "GenSigTimeoutMsg_HU_A" SG_ 731 GyroInfoZ 0;
BA_ "GenSigTimeoutMsg_HU_B" SG_ 731 GyroInfoZ 0;
BA_ "GenSigTimeoutMsg_HU_High_X451" SG_ 731 GyroInfoZ 0;
BA_ "GenSigTimeoutMsg_HU_Mid_X451" SG_ 731 GyroInfoZ 0;
BA_ "GenSigTimeoutTime_HU_A" SG_ 731 GyroInfoZ 0;
BA_ "GenSigTimeoutTime_HU_B" SG_ 731 GyroInfoZ 0;
BA_ "GenSigTimeoutTime_HU_High_X451" SG_ 731 GyroInfoZ 0;
BA_ "GenSigTimeoutTime_HU_Mid_X451" SG_ 731 GyroInfoZ 0;
BA_ "GenSigTimeoutTime_HU_Mid_X445" SG_ 731 GyroInfoY 0;
BA_ "GenSigTimeoutTime_HU_High_X445" SG_ 731 GyroInfoY 0;
BA_ "GenSigTimeoutMsg_HU_Mid_X445" SG_ 731 GyroInfoY 0;
BA_ "GenSigTimeoutMsg_HU_High_X445" SG_ 731 GyroInfoY 0;
BA_ "GenSigCycleTime" SG_ 731 GyroInfoY 100;
BA_ "GenSigCycleTimeActive" SG_ 731 GyroInfoY 100;
BA_ "GenSigSendType" SG_ 731 GyroInfoY 7;
BA_ "GenSigStartValue" SG_ 731 GyroInfoY 20000;
BA_ "GenSigTimeoutMsg_HU_A" SG_ 731 GyroInfoY 0;
BA_ "GenSigTimeoutMsg_HU_B" SG_ 731 GyroInfoY 0;
BA_ "GenSigTimeoutMsg_HU_High_X451" SG_ 731 GyroInfoY 0;
BA_ "GenSigTimeoutMsg_HU_Mid_X451" SG_ 731 GyroInfoY 0;
BA_ "GenSigTimeoutTime_HU_A" SG_ 731 GyroInfoY 0;
BA_ "GenSigTimeoutTime_HU_B" SG_ 731 GyroInfoY 0;
BA_ "GenSigTimeoutTime_HU_High_X451" SG_ 731 GyroInfoY 0;
BA_ "GenSigTimeoutTime_HU_Mid_X451" SG_ 731 GyroInfoY 0;
BA_ "GenSigTimeoutTime_HU_Mid_X445" SG_ 731 GyroInfoXYZStatus 0;
BA_ "GenSigTimeoutTime_HU_High_X445" SG_ 731 GyroInfoXYZStatus 0;
BA_ "GenSigTimeoutMsg_HU_Mid_X445" SG_ 731 GyroInfoXYZStatus 0;
BA_ "GenSigTimeoutMsg_HU_High_X445" SG_ 731 GyroInfoXYZStatus 0;
BA_ "GenSigCycleTime" SG_ 731 GyroInfoXYZStatus 100;
BA_ "GenSigCycleTimeActive" SG_ 731 GyroInfoXYZStatus 100;
BA_ "GenSigSendType" SG_ 731 GyroInfoXYZStatus 7;
BA_ "GenSigTimeoutMsg_HU_A" SG_ 731 GyroInfoXYZStatus 0;
BA_ "GenSigTimeoutMsg_HU_B" SG_ 731 GyroInfoXYZStatus 0;
BA_ "GenSigTimeoutMsg_HU_High_X451" SG_ 731 GyroInfoXYZStatus 0;
BA_ "GenSigTimeoutMsg_HU_Mid_X451" SG_ 731 GyroInfoXYZStatus 0;
BA_ "GenSigTimeoutTime_HU_A" SG_ 731 GyroInfoXYZStatus 0;
BA_ "GenSigTimeoutTime_HU_B" SG_ 731 GyroInfoXYZStatus 0;
BA_ "GenSigTimeoutTime_HU_High_X451" SG_ 731 GyroInfoXYZStatus 0;
BA_ "GenSigTimeoutTime_HU_Mid_X451" SG_ 731 GyroInfoXYZStatus 0;
BA_ "GenSigTimeoutTime_HU_Mid_X445" SG_ 731 GyroInfoX 0;
BA_ "GenSigTimeoutTime_HU_High_X445" SG_ 731 GyroInfoX 0;
BA_ "GenSigTimeoutMsg_HU_Mid_X445" SG_ 731 GyroInfoX 0;
BA_ "GenSigTimeoutMsg_HU_High_X445" SG_ 731 GyroInfoX 0;
BA_ "GenSigCycleTime" SG_ 731 GyroInfoX 100;
BA_ "GenSigCycleTimeActive" SG_ 731 GyroInfoX 100;
BA_ "GenSigSendType" SG_ 731 GyroInfoX 7;
BA_ "GenSigStartValue" SG_ 731 GyroInfoX 20000;
BA_ "GenSigTimeoutMsg_HU_A" SG_ 731 GyroInfoX 0;
BA_ "GenSigTimeoutMsg_HU_B" SG_ 731 GyroInfoX 0;
BA_ "GenSigTimeoutMsg_HU_High_X451" SG_ 731 GyroInfoX 0;
BA_ "GenSigTimeoutMsg_HU_Mid_X451" SG_ 731 GyroInfoX 0;
BA_ "GenSigTimeoutTime_HU_A" SG_ 731 GyroInfoX 0;
BA_ "GenSigTimeoutTime_HU_B" SG_ 731 GyroInfoX 0;
BA_ "GenSigTimeoutTime_HU_High_X451" SG_ 731 GyroInfoX 0;
BA_ "GenSigTimeoutTime_HU_Mid_X451" SG_ 731 GyroInfoX 0;
BA_ "GenSigTimeoutTime_HU_Mid_X445" SG_ 582 HvBattPwrConsmp 0;
BA_ "GenSigTimeoutTime_HU_High_X445" SG_ 582 HvBattPwrConsmp 0;
BA_ "GenSigTimeoutMsg_HU_Mid_X445" SG_ 582 HvBattPwrConsmp 0;
BA_ "GenSigTimeoutMsg_HU_High_X445" SG_ 582 HvBattPwrConsmp 0;
BA_ "GenSigCycleTime" SG_ 582 HvBattPwrConsmp 100;
BA_ "GenSigCycleTimeActive" SG_ 582 HvBattPwrConsmp 100;
BA_ "GenSigSendType" SG_ 582 HvBattPwrConsmp 7;
BA_ "GenSigTimeoutMsg_HU_A" SG_ 582 HvBattPwrConsmp 0;
BA_ "GenSigTimeoutMsg_HU_B" SG_ 582 HvBattPwrConsmp 0;
BA_ "GenSigTimeoutMsg_HU_High_X451" SG_ 582 HvBattPwrConsmp 0;
BA_ "GenSigTimeoutMsg_HU_Mid_X451" SG_ 582 HvBattPwrConsmp 0;
BA_ "GenSigTimeoutTime_HU_A" SG_ 582 HvBattPwrConsmp 0;
BA_ "GenSigTimeoutTime_HU_B" SG_ 582 HvBattPwrConsmp 0;
BA_ "GenSigTimeoutTime_HU_High_X451" SG_ 582 HvBattPwrConsmp 0;
BA_ "GenSigTimeoutTime_HU_Mid_X451" SG_ 582 HvBattPwrConsmp 0;
BA_ "GenSigTimeoutTime_HU_Mid_X445" SG_ 582 AvgEnergyConsmpTripBStatus 0;
BA_ "GenSigTimeoutTime_HU_High_X445" SG_ 582 AvgEnergyConsmpTripBStatus 0;
BA_ "GenSigTimeoutMsg_HU_Mid_X445" SG_ 582 AvgEnergyConsmpTripBStatus 0;
BA_ "GenSigTimeoutMsg_HU_High_X445" SG_ 582 AvgEnergyConsmpTripBStatus 0;
BA_ "GenSigCycleTime" SG_ 582 AvgEnergyConsmpTripBStatus 100;
BA_ "GenSigCycleTimeActive" SG_ 582 AvgEnergyConsmpTripBStatus 100;
BA_ "GenSigSendType" SG_ 582 AvgEnergyConsmpTripBStatus 7;
BA_ "GenSigTimeoutMsg_HU_A" SG_ 582 AvgEnergyConsmpTripBStatus 0;
BA_ "GenSigTimeoutMsg_HU_B" SG_ 582 AvgEnergyConsmpTripBStatus 0;
BA_ "GenSigTimeoutMsg_HU_High_X451" SG_ 582 AvgEnergyConsmpTripBStatus 0;
BA_ "GenSigTimeoutMsg_HU_Mid_X451" SG_ 582 AvgEnergyConsmpTripBStatus 0;
BA_ "GenSigTimeoutTime_HU_A" SG_ 582 AvgEnergyConsmpTripBStatus 0;
BA_ "GenSigTimeoutTime_HU_B" SG_ 582 AvgEnergyConsmpTripBStatus 0;
BA_ "GenSigTimeoutTime_HU_High_X451" SG_ 582 AvgEnergyConsmpTripBStatus 0;
BA_ "GenSigTimeoutTime_HU_Mid_X451" SG_ 582 AvgEnergyConsmpTripBStatus 0;
BA_ "GenSigTimeoutTime_HU_Mid_X445" SG_ 582 AvgEnergyConsmpTripAStatus 0;
BA_ "GenSigTimeoutTime_HU_High_X445" SG_ 582 AvgEnergyConsmpTripAStatus 0;
BA_ "GenSigTimeoutMsg_HU_Mid_X445" SG_ 582 AvgEnergyConsmpTripAStatus 0;
BA_ "GenSigTimeoutMsg_HU_High_X445" SG_ 582 AvgEnergyConsmpTripAStatus 0;
BA_ "GenSigCycleTime" SG_ 582 AvgEnergyConsmpTripAStatus 100;
BA_ "GenSigCycleTimeActive" SG_ 582 AvgEnergyConsmpTripAStatus 100;
BA_ "GenSigSendType" SG_ 582 AvgEnergyConsmpTripAStatus 7;
BA_ "GenSigTimeoutMsg_HU_A" SG_ 582 AvgEnergyConsmpTripAStatus 0;
BA_ "GenSigTimeoutMsg_HU_B" SG_ 582 AvgEnergyConsmpTripAStatus 0;
BA_ "GenSigTimeoutMsg_HU_High_X451" SG_ 582 AvgEnergyConsmpTripAStatus 0;
BA_ "GenSigTimeoutMsg_HU_Mid_X451" SG_ 582 AvgEnergyConsmpTripAStatus 0;
BA_ "GenSigTimeoutTime_HU_A" SG_ 582 AvgEnergyConsmpTripAStatus 0;
BA_ "GenSigTimeoutTime_HU_B" SG_ 582 AvgEnergyConsmpTripAStatus 0;
BA_ "GenSigTimeoutTime_HU_High_X451" SG_ 582 AvgEnergyConsmpTripAStatus 0;
BA_ "GenSigTimeoutTime_HU_Mid_X451" SG_ 582 AvgEnergyConsmpTripAStatus 0;
BA_ "GenSigTimeoutTime_HU_Mid_X445" SG_ 582 AvgEnergyConsmpTripB 0;
BA_ "GenSigTimeoutTime_HU_High_X445" SG_ 582 AvgEnergyConsmpTripB 0;
BA_ "GenSigTimeoutMsg_HU_Mid_X445" SG_ 582 AvgEnergyConsmpTripB 0;
BA_ "GenSigTimeoutMsg_HU_High_X445" SG_ 582 AvgEnergyConsmpTripB 0;
BA_ "GenSigCycleTime" SG_ 582 AvgEnergyConsmpTripB 100;
BA_ "GenSigCycleTimeActive" SG_ 582 AvgEnergyConsmpTripB 100;
BA_ "GenSigSendType" SG_ 582 AvgEnergyConsmpTripB 7;
BA_ "GenSigTimeoutMsg_HU_A" SG_ 582 AvgEnergyConsmpTripB 0;
BA_ "GenSigTimeoutMsg_HU_B" SG_ 582 AvgEnergyConsmpTripB 0;
BA_ "GenSigTimeoutMsg_HU_High_X451" SG_ 582 AvgEnergyConsmpTripB 0;
BA_ "GenSigTimeoutMsg_HU_Mid_X451" SG_ 582 AvgEnergyConsmpTripB 0;
BA_ "GenSigTimeoutTime_HU_A" SG_ 582 AvgEnergyConsmpTripB 0;
BA_ "GenSigTimeoutTime_HU_B" SG_ 582 AvgEnergyConsmpTripB 0;
BA_ "GenSigTimeoutTime_HU_High_X451" SG_ 582 AvgEnergyConsmpTripB 0;
BA_ "GenSigTimeoutTime_HU_Mid_X451" SG_ 582 AvgEnergyConsmpTripB 0;
BA_ "GenSigTimeoutTime_HU_Mid_X445" SG_ 582 AvgEnergyConsmpTripA 0;
BA_ "GenSigTimeoutTime_HU_High_X445" SG_ 582 AvgEnergyConsmpTripA 0;
BA_ "GenSigTimeoutMsg_HU_Mid_X445" SG_ 582 AvgEnergyConsmpTripA 0;
BA_ "GenSigTimeoutMsg_HU_High_X445" SG_ 582 AvgEnergyConsmpTripA 0;
BA_ "GenSigCycleTime" SG_ 582 AvgEnergyConsmpTripA 100;
BA_ "GenSigCycleTimeActive" SG_ 582 AvgEnergyConsmpTripA 100;
BA_ "GenSigSendType" SG_ 582 AvgEnergyConsmpTripA 7;
BA_ "GenSigTimeoutMsg_HU_A" SG_ 582 AvgEnergyConsmpTripA 0;
BA_ "GenSigTimeoutMsg_HU_B" SG_ 582 AvgEnergyConsmpTripA 0;
BA_ "GenSigTimeoutMsg_HU_High_X451" SG_ 582 AvgEnergyConsmpTripA 0;
BA_ "GenSigTimeoutMsg_HU_Mid_X451" SG_ 582 AvgEnergyConsmpTripA 0;
BA_ "GenSigTimeoutTime_HU_A" SG_ 582 AvgEnergyConsmpTripA 0;
BA_ "GenSigTimeoutTime_HU_B" SG_ 582 AvgEnergyConsmpTripA 0;
BA_ "GenSigTimeoutTime_HU_High_X451" SG_ 582 AvgEnergyConsmpTripA 0;
BA_ "GenSigTimeoutTime_HU_Mid_X451" SG_ 582 AvgEnergyConsmpTripA 0;
BA_ "GenSigTimeoutTime_HU_Mid_X445" SG_ 582 InstPwrConsumpStatus 0;
BA_ "GenSigTimeoutTime_HU_High_X445" SG_ 582 InstPwrConsumpStatus 0;
BA_ "GenSigTimeoutMsg_HU_Mid_X445" SG_ 582 InstPwrConsumpStatus 0;
BA_ "GenSigTimeoutMsg_HU_High_X445" SG_ 582 InstPwrConsumpStatus 0;
BA_ "GenSigCycleTime" SG_ 582 InstPwrConsumpStatus 100;
BA_ "GenSigCycleTimeActive" SG_ 582 InstPwrConsumpStatus 100;
BA_ "GenSigSendType" SG_ 582 InstPwrConsumpStatus 7;
BA_ "GenSigTimeoutMsg_HU_A" SG_ 582 InstPwrConsumpStatus 0;
BA_ "GenSigTimeoutMsg_HU_B" SG_ 582 InstPwrConsumpStatus 0;
BA_ "GenSigTimeoutMsg_HU_High_X451" SG_ 582 InstPwrConsumpStatus 0;
BA_ "GenSigTimeoutMsg_HU_Mid_X451" SG_ 582 InstPwrConsumpStatus 0;
BA_ "GenSigTimeoutTime_HU_A" SG_ 582 InstPwrConsumpStatus 0;
BA_ "GenSigTimeoutTime_HU_B" SG_ 582 InstPwrConsumpStatus 0;
BA_ "GenSigTimeoutTime_HU_High_X451" SG_ 582 InstPwrConsumpStatus 0;
BA_ "GenSigTimeoutTime_HU_Mid_X451" SG_ 582 InstPwrConsumpStatus 0;
BA_ "GenSigTimeoutTime_HU_Mid_X445" SG_ 582 InstPwrConsump 0;
BA_ "GenSigTimeoutTime_HU_High_X445" SG_ 582 InstPwrConsump 0;
BA_ "GenSigTimeoutMsg_HU_Mid_X445" SG_ 582 InstPwrConsump 0;
BA_ "GenSigTimeoutMsg_HU_High_X445" SG_ 582 InstPwrConsump 0;
BA_ "GenSigCycleTime" SG_ 582 InstPwrConsump 100;
BA_ "GenSigCycleTimeActive" SG_ 582 InstPwrConsump 100;
BA_ "GenSigSendType" SG_ 582 InstPwrConsump 7;
BA_ "GenSigStartValue" SG_ 582 InstPwrConsump 100;
BA_ "GenSigTimeoutMsg_HU_A" SG_ 582 InstPwrConsump 0;
BA_ "GenSigTimeoutMsg_HU_B" SG_ 582 InstPwrConsump 0;
BA_ "GenSigTimeoutMsg_HU_High_X451" SG_ 582 InstPwrConsump 0;
BA_ "GenSigTimeoutMsg_HU_Mid_X451" SG_ 582 InstPwrConsump 0;
BA_ "GenSigTimeoutTime_HU_A" SG_ 582 InstPwrConsump 0;
BA_ "GenSigTimeoutTime_HU_B" SG_ 582 InstPwrConsump 0;
BA_ "GenSigTimeoutTime_HU_High_X451" SG_ 582 InstPwrConsump 0;
BA_ "GenSigTimeoutTime_HU_Mid_X451" SG_ 582 InstPwrConsump 0;
BA_ "GenSigTimeoutTime_HU_Mid_X445" SG_ 719 PtcHtrForcedCutoff 0;
BA_ "GenSigTimeoutTime_HU_High_X445" SG_ 719 PtcHtrForcedCutoff 0;
BA_ "GenSigTimeoutMsg_HU_Mid_X445" SG_ 719 PtcHtrForcedCutoff 0;
BA_ "GenSigTimeoutMsg_HU_High_X445" SG_ 719 PtcHtrForcedCutoff 0;
BA_ "GenSigCycleTime" SG_ 719 PtcHtrForcedCutoff 100;
BA_ "GenSigCycleTimeActive" SG_ 719 PtcHtrForcedCutoff 100;
BA_ "GenSigSendType" SG_ 719 PtcHtrForcedCutoff 7;
BA_ "GenSigTimeoutMsg_HU_A" SG_ 719 PtcHtrForcedCutoff 0;
BA_ "GenSigTimeoutMsg_HU_B" SG_ 719 PtcHtrForcedCutoff 0;
BA_ "GenSigTimeoutMsg_HU_High_X451" SG_ 719 PtcHtrForcedCutoff 0;
BA_ "GenSigTimeoutMsg_HU_Mid_X451" SG_ 719 PtcHtrForcedCutoff 0;
BA_ "GenSigTimeoutTime_HU_A" SG_ 719 PtcHtrForcedCutoff 0;
BA_ "GenSigTimeoutTime_HU_B" SG_ 719 PtcHtrForcedCutoff 0;
BA_ "GenSigTimeoutTime_HU_High_X451" SG_ 719 PtcHtrForcedCutoff 0;
BA_ "GenSigTimeoutTime_HU_Mid_X451" SG_ 719 PtcHtrForcedCutoff 0;
BA_ "GenSigCycleTime" SG_ 1142 PEPS_Invalid_failure_status 100;
BA_ "GenSigCycleTimeActive" SG_ 1142 PEPS_Invalid_failure_status 100;
BA_ "GenSigSendType" SG_ 1142 PEPS_Invalid_failure_status 7;
BA_ "GenSigTimeoutMsg_HU_A" SG_ 1142 PEPS_Invalid_failure_status 0;
BA_ "GenSigTimeoutMsg_HU_B" SG_ 1142 PEPS_Invalid_failure_status 0;
BA_ "GenSigTimeoutMsg_HU_High_X451" SG_ 1142 PEPS_Invalid_failure_status 0;
BA_ "GenSigTimeoutMsg_HU_Mid_X451" SG_ 1142 PEPS_Invalid_failure_status 0;
BA_ "GenSigTimeoutTime_HU_A" SG_ 1142 PEPS_Invalid_failure_status 0;
BA_ "GenSigTimeoutTime_HU_B" SG_ 1142 PEPS_Invalid_failure_status 0;
BA_ "GenSigTimeoutTime_HU_High_X451" SG_ 1142 PEPS_Invalid_failure_status 0;
BA_ "GenSigTimeoutTime_HU_Mid_X451" SG_ 1142 PEPS_Invalid_failure_status 0;
BA_ "GenSigCycleTime" SG_ 1142 Telematics_MTO_Failure_status 100;
BA_ "GenSigCycleTimeActive" SG_ 1142 Telematics_MTO_Failure_status 100;
BA_ "GenSigSendType" SG_ 1142 Telematics_MTO_Failure_status 7;
BA_ "GenSigTimeoutMsg_HU_A" SG_ 1142 Telematics_MTO_Failure_status 0;
BA_ "GenSigTimeoutMsg_HU_B" SG_ 1142 Telematics_MTO_Failure_status 0;
BA_ "GenSigTimeoutMsg_HU_High_X451" SG_ 1142 Telematics_MTO_Failure_status 0;
BA_ "GenSigTimeoutMsg_HU_Mid_X451" SG_ 1142 Telematics_MTO_Failure_status 0;
BA_ "GenSigTimeoutTime_HU_A" SG_ 1142 Telematics_MTO_Failure_status 0;
BA_ "GenSigTimeoutTime_HU_B" SG_ 1142 Telematics_MTO_Failure_status 0;
BA_ "GenSigTimeoutTime_HU_High_X451" SG_ 1142 Telematics_MTO_Failure_status 0;
BA_ "GenSigTimeoutTime_HU_Mid_X451" SG_ 1142 Telematics_MTO_Failure_status 0;
BA_ "GenSigCycleTime" SG_ 1142 Telematics_Invalid_FailureStatus 100;
BA_ "GenSigCycleTimeActive" SG_ 1142 Telematics_Invalid_FailureStatus 100;
BA_ "GenSigSendType" SG_ 1142 Telematics_Invalid_FailureStatus 7;
BA_ "GenSigTimeoutMsg_HU_A" SG_ 1142 Telematics_Invalid_FailureStatus 0;
BA_ "GenSigTimeoutMsg_HU_B" SG_ 1142 Telematics_Invalid_FailureStatus 0;
BA_ "GenSigTimeoutMsg_HU_High_X451" SG_ 1142 Telematics_Invalid_FailureStatus 0;
BA_ "GenSigTimeoutMsg_HU_Mid_X451" SG_ 1142 Telematics_Invalid_FailureStatus 0;
BA_ "GenSigTimeoutTime_HU_A" SG_ 1142 Telematics_Invalid_FailureStatus 0;
BA_ "GenSigTimeoutTime_HU_B" SG_ 1142 Telematics_Invalid_FailureStatus 0;
BA_ "GenSigTimeoutTime_HU_High_X451" SG_ 1142 Telematics_Invalid_FailureStatus 0;
BA_ "GenSigTimeoutTime_HU_Mid_X451" SG_ 1142 Telematics_Invalid_FailureStatus 0;
BA_ "GenSigCycleTime" SG_ 1142 SRS_MTO_Failure_Status 100;
BA_ "GenSigCycleTimeActive" SG_ 1142 SRS_MTO_Failure_Status 100;
BA_ "GenSigSendType" SG_ 1142 SRS_MTO_Failure_Status 7;
BA_ "GenSigTimeoutMsg_HU_A" SG_ 1142 SRS_MTO_Failure_Status 0;
BA_ "GenSigTimeoutMsg_HU_B" SG_ 1142 SRS_MTO_Failure_Status 0;
BA_ "GenSigTimeoutMsg_HU_High_X451" SG_ 1142 SRS_MTO_Failure_Status 0;
BA_ "GenSigTimeoutMsg_HU_Mid_X451" SG_ 1142 SRS_MTO_Failure_Status 0;
BA_ "GenSigTimeoutTime_HU_A" SG_ 1142 SRS_MTO_Failure_Status 0;
BA_ "GenSigTimeoutTime_HU_B" SG_ 1142 SRS_MTO_Failure_Status 0;
BA_ "GenSigTimeoutTime_HU_High_X451" SG_ 1142 SRS_MTO_Failure_Status 0;
BA_ "GenSigTimeoutTime_HU_Mid_X451" SG_ 1142 SRS_MTO_Failure_Status 0;
BA_ "GenSigCycleTime" SG_ 1142 PEPS_MTO_Failure_Status 100;
BA_ "GenSigCycleTimeActive" SG_ 1142 PEPS_MTO_Failure_Status 100;
BA_ "GenSigSendType" SG_ 1142 PEPS_MTO_Failure_Status 7;
BA_ "GenSigTimeoutMsg_HU_A" SG_ 1142 PEPS_MTO_Failure_Status 0;
BA_ "GenSigTimeoutMsg_HU_B" SG_ 1142 PEPS_MTO_Failure_Status 0;
BA_ "GenSigTimeoutMsg_HU_High_X451" SG_ 1142 PEPS_MTO_Failure_Status 0;
BA_ "GenSigTimeoutMsg_HU_Mid_X451" SG_ 1142 PEPS_MTO_Failure_Status 0;
BA_ "GenSigTimeoutTime_HU_A" SG_ 1142 PEPS_MTO_Failure_Status 0;
BA_ "GenSigTimeoutTime_HU_B" SG_ 1142 PEPS_MTO_Failure_Status 0;
BA_ "GenSigTimeoutTime_HU_High_X451" SG_ 1142 PEPS_MTO_Failure_Status 0;
BA_ "GenSigTimeoutTime_HU_Mid_X451" SG_ 1142 PEPS_MTO_Failure_Status 0;
BA_ "GenSigCycleTime" SG_ 1142 IPcMToFailureStatus 100;
BA_ "GenSigCycleTimeActive" SG_ 1142 IPcMToFailureStatus 100;
BA_ "GenSigSendType" SG_ 1142 IPcMToFailureStatus 7;
BA_ "GenSigTimeoutMsg_HU_A" SG_ 1142 IPcMToFailureStatus 0;
BA_ "GenSigTimeoutMsg_HU_B" SG_ 1142 IPcMToFailureStatus 0;
BA_ "GenSigTimeoutMsg_HU_High_X451" SG_ 1142 IPcMToFailureStatus 0;
BA_ "GenSigTimeoutMsg_HU_Mid_X451" SG_ 1142 IPcMToFailureStatus 0;
BA_ "GenSigTimeoutTime_HU_A" SG_ 1142 IPcMToFailureStatus 0;
BA_ "GenSigTimeoutTime_HU_B" SG_ 1142 IPcMToFailureStatus 0;
BA_ "GenSigTimeoutTime_HU_High_X451" SG_ 1142 IPcMToFailureStatus 0;
BA_ "GenSigTimeoutTime_HU_Mid_X451" SG_ 1142 IPcMToFailureStatus 0;
BA_ "GenSigCycleTime" SG_ 1142 IPcInvalidFailureStatus 100;
BA_ "GenSigCycleTimeActive" SG_ 1142 IPcInvalidFailureStatus 100;
BA_ "GenSigSendType" SG_ 1142 IPcInvalidFailureStatus 7;
BA_ "GenSigTimeoutMsg_HU_A" SG_ 1142 IPcInvalidFailureStatus 0;
BA_ "GenSigTimeoutMsg_HU_B" SG_ 1142 IPcInvalidFailureStatus 0;
BA_ "GenSigTimeoutMsg_HU_High_X451" SG_ 1142 IPcInvalidFailureStatus 0;
BA_ "GenSigTimeoutMsg_HU_Mid_X451" SG_ 1142 IPcInvalidFailureStatus 0;
BA_ "GenSigTimeoutTime_HU_A" SG_ 1142 IPcInvalidFailureStatus 0;
BA_ "GenSigTimeoutTime_HU_B" SG_ 1142 IPcInvalidFailureStatus 0;
BA_ "GenSigTimeoutTime_HU_High_X451" SG_ 1142 IPcInvalidFailureStatus 0;
BA_ "GenSigTimeoutTime_HU_Mid_X451" SG_ 1142 IPcInvalidFailureStatus 0;
BA_ "GenSigCycleTime" SG_ 1142 ABsMToFailureStatus 100;
BA_ "GenSigCycleTimeActive" SG_ 1142 ABsMToFailureStatus 100;
BA_ "GenSigSendType" SG_ 1142 ABsMToFailureStatus 7;
BA_ "GenSigTimeoutMsg_HU_A" SG_ 1142 ABsMToFailureStatus 0;
BA_ "GenSigTimeoutMsg_HU_B" SG_ 1142 ABsMToFailureStatus 0;
BA_ "GenSigTimeoutMsg_HU_High_X451" SG_ 1142 ABsMToFailureStatus 0;
BA_ "GenSigTimeoutMsg_HU_Mid_X451" SG_ 1142 ABsMToFailureStatus 0;
BA_ "GenSigTimeoutTime_HU_A" SG_ 1142 ABsMToFailureStatus 0;
BA_ "GenSigTimeoutTime_HU_B" SG_ 1142 ABsMToFailureStatus 0;
BA_ "GenSigTimeoutTime_HU_High_X451" SG_ 1142 ABsMToFailureStatus 0;
BA_ "GenSigTimeoutTime_HU_Mid_X451" SG_ 1142 ABsMToFailureStatus 0;
BA_ "GenSigCycleTime" SG_ 1142 ABsInvalidFailureStatus 100;
BA_ "GenSigCycleTimeActive" SG_ 1142 ABsInvalidFailureStatus 100;
BA_ "GenSigSendType" SG_ 1142 ABsInvalidFailureStatus 7;
BA_ "GenSigTimeoutMsg_HU_A" SG_ 1142 ABsInvalidFailureStatus 0;
BA_ "GenSigTimeoutMsg_HU_B" SG_ 1142 ABsInvalidFailureStatus 0;
BA_ "GenSigTimeoutMsg_HU_High_X451" SG_ 1142 ABsInvalidFailureStatus 0;
BA_ "GenSigTimeoutMsg_HU_Mid_X451" SG_ 1142 ABsInvalidFailureStatus 0;
BA_ "GenSigTimeoutTime_HU_A" SG_ 1142 ABsInvalidFailureStatus 0;
BA_ "GenSigTimeoutTime_HU_B" SG_ 1142 ABsInvalidFailureStatus 0;
BA_ "GenSigTimeoutTime_HU_High_X451" SG_ 1142 ABsInvalidFailureStatus 0;
BA_ "GenSigTimeoutTime_HU_Mid_X451" SG_ 1142 ABsInvalidFailureStatus 0;
BA_ "GenSigCycleTime" SG_ 1142 VCU_SW_Version 100;
BA_ "GenSigCycleTimeActive" SG_ 1142 VCU_SW_Version 100;
BA_ "GenSigSendType" SG_ 1142 VCU_SW_Version 7;
BA_ "GenSigTimeoutMsg_HU_A" SG_ 1142 VCU_SW_Version 0;
BA_ "GenSigTimeoutMsg_HU_B" SG_ 1142 VCU_SW_Version 0;
BA_ "GenSigTimeoutMsg_HU_High_X451" SG_ 1142 VCU_SW_Version 0;
BA_ "GenSigTimeoutMsg_HU_Mid_X451" SG_ 1142 VCU_SW_Version 0;
BA_ "GenSigTimeoutTime_HU_A" SG_ 1142 VCU_SW_Version 0;
BA_ "GenSigTimeoutTime_HU_B" SG_ 1142 VCU_SW_Version 0;
BA_ "GenSigTimeoutTime_HU_High_X451" SG_ 1142 VCU_SW_Version 0;
BA_ "GenSigTimeoutTime_HU_Mid_X451" SG_ 1142 VCU_SW_Version 0;
BA_ "GenSigCycleTime" SG_ 1142 VCU_Err_State_Trans_Cntr 100;
BA_ "GenSigCycleTimeActive" SG_ 1142 VCU_Err_State_Trans_Cntr 100;
BA_ "GenSigSendType" SG_ 1142 VCU_Err_State_Trans_Cntr 7;
BA_ "GenSigTimeoutMsg_HU_A" SG_ 1142 VCU_Err_State_Trans_Cntr 0;
BA_ "GenSigTimeoutMsg_HU_B" SG_ 1142 VCU_Err_State_Trans_Cntr 0;
BA_ "GenSigTimeoutMsg_HU_High_X451" SG_ 1142 VCU_Err_State_Trans_Cntr 0;
BA_ "GenSigTimeoutMsg_HU_Mid_X451" SG_ 1142 VCU_Err_State_Trans_Cntr 0;
BA_ "GenSigTimeoutTime_HU_A" SG_ 1142 VCU_Err_State_Trans_Cntr 0;
BA_ "GenSigTimeoutTime_HU_B" SG_ 1142 VCU_Err_State_Trans_Cntr 0;
BA_ "GenSigTimeoutTime_HU_High_X451" SG_ 1142 VCU_Err_State_Trans_Cntr 0;
BA_ "GenSigTimeoutTime_HU_Mid_X451" SG_ 1142 VCU_Err_State_Trans_Cntr 0;
BA_ "GenSigCycleTime" SG_ 1142 VCU_EP_Failure_Status 100;
BA_ "GenSigCycleTimeActive" SG_ 1142 VCU_EP_Failure_Status 100;
BA_ "GenSigSendType" SG_ 1142 VCU_EP_Failure_Status 7;
BA_ "GenSigTimeoutMsg_HU_A" SG_ 1142 VCU_EP_Failure_Status 0;
BA_ "GenSigTimeoutMsg_HU_B" SG_ 1142 VCU_EP_Failure_Status 0;
BA_ "GenSigTimeoutMsg_HU_High_X451" SG_ 1142 VCU_EP_Failure_Status 0;
BA_ "GenSigTimeoutMsg_HU_Mid_X451" SG_ 1142 VCU_EP_Failure_Status 0;
BA_ "GenSigTimeoutTime_HU_A" SG_ 1142 VCU_EP_Failure_Status 0;
BA_ "GenSigTimeoutTime_HU_B" SG_ 1142 VCU_EP_Failure_Status 0;
BA_ "GenSigTimeoutTime_HU_High_X451" SG_ 1142 VCU_EP_Failure_Status 0;
BA_ "GenSigTimeoutTime_HU_Mid_X451" SG_ 1142 VCU_EP_Failure_Status 0;
BA_ "GenSigCycleTime" SG_ 1142 VCU_BO_Failure_Status 100;
BA_ "GenSigCycleTimeActive" SG_ 1142 VCU_BO_Failure_Status 100;
BA_ "GenSigSendType" SG_ 1142 VCU_BO_Failure_Status 7;
BA_ "GenSigTimeoutMsg_HU_A" SG_ 1142 VCU_BO_Failure_Status 0;
BA_ "GenSigTimeoutMsg_HU_B" SG_ 1142 VCU_BO_Failure_Status 0;
BA_ "GenSigTimeoutMsg_HU_High_X451" SG_ 1142 VCU_BO_Failure_Status 0;
BA_ "GenSigTimeoutMsg_HU_Mid_X451" SG_ 1142 VCU_BO_Failure_Status 0;
BA_ "GenSigTimeoutTime_HU_A" SG_ 1142 VCU_BO_Failure_Status 0;
BA_ "GenSigTimeoutTime_HU_B" SG_ 1142 VCU_BO_Failure_Status 0;
BA_ "GenSigTimeoutTime_HU_High_X451" SG_ 1142 VCU_BO_Failure_Status 0;
BA_ "GenSigTimeoutTime_HU_Mid_X451" SG_ 1142 VCU_BO_Failure_Status 0;
BA_ "GenSigCycleTime" SG_ 1142 GSS_EV_Invalid_Failure_Status 100;
BA_ "GenSigCycleTimeActive" SG_ 1142 GSS_EV_Invalid_Failure_Status 100;
BA_ "GenSigSendType" SG_ 1142 GSS_EV_Invalid_Failure_Status 7;
BA_ "GenSigTimeoutMsg_HU_A" SG_ 1142 GSS_EV_Invalid_Failure_Status 0;
BA_ "GenSigTimeoutMsg_HU_B" SG_ 1142 GSS_EV_Invalid_Failure_Status 0;
BA_ "GenSigTimeoutMsg_HU_High_X451" SG_ 1142 GSS_EV_Invalid_Failure_Status 0;
BA_ "GenSigTimeoutMsg_HU_Mid_X451" SG_ 1142 GSS_EV_Invalid_Failure_Status 0;
BA_ "GenSigTimeoutTime_HU_A" SG_ 1142 GSS_EV_Invalid_Failure_Status 0;
BA_ "GenSigTimeoutTime_HU_B" SG_ 1142 GSS_EV_Invalid_Failure_Status 0;
BA_ "GenSigTimeoutTime_HU_High_X451" SG_ 1142 GSS_EV_Invalid_Failure_Status 0;
BA_ "GenSigTimeoutTime_HU_Mid_X451" SG_ 1142 GSS_EV_Invalid_Failure_Status 0;
BA_ "GenSigCycleTime" SG_ 1142 GSS_EV_MTO_Failure_Status 100;
BA_ "GenSigCycleTimeActive" SG_ 1142 GSS_EV_MTO_Failure_Status 100;
BA_ "GenSigSendType" SG_ 1142 GSS_EV_MTO_Failure_Status 7;
BA_ "GenSigTimeoutMsg_HU_A" SG_ 1142 GSS_EV_MTO_Failure_Status 0;
BA_ "GenSigTimeoutMsg_HU_B" SG_ 1142 GSS_EV_MTO_Failure_Status 0;
BA_ "GenSigTimeoutMsg_HU_High_X451" SG_ 1142 GSS_EV_MTO_Failure_Status 0;
BA_ "GenSigTimeoutMsg_HU_Mid_X451" SG_ 1142 GSS_EV_MTO_Failure_Status 0;
BA_ "GenSigTimeoutTime_HU_A" SG_ 1142 GSS_EV_MTO_Failure_Status 0;
BA_ "GenSigTimeoutTime_HU_B" SG_ 1142 GSS_EV_MTO_Failure_Status 0;
BA_ "GenSigTimeoutTime_HU_High_X451" SG_ 1142 GSS_EV_MTO_Failure_Status 0;
BA_ "GenSigTimeoutTime_HU_Mid_X451" SG_ 1142 GSS_EV_MTO_Failure_Status 0;
BA_ "GenSigCycleTime" SG_ 1142 CCM_MTO_Failure_Status 100;
BA_ "GenSigCycleTimeActive" SG_ 1142 CCM_MTO_Failure_Status 100;
BA_ "GenSigSendType" SG_ 1142 CCM_MTO_Failure_Status 7;
BA_ "GenSigTimeoutMsg_HU_A" SG_ 1142 CCM_MTO_Failure_Status 0;
BA_ "GenSigTimeoutMsg_HU_B" SG_ 1142 CCM_MTO_Failure_Status 0;
BA_ "GenSigTimeoutMsg_HU_High_X451" SG_ 1142 CCM_MTO_Failure_Status 0;
BA_ "GenSigTimeoutMsg_HU_Mid_X451" SG_ 1142 CCM_MTO_Failure_Status 0;
BA_ "GenSigTimeoutTime_HU_A" SG_ 1142 CCM_MTO_Failure_Status 0;
BA_ "GenSigTimeoutTime_HU_B" SG_ 1142 CCM_MTO_Failure_Status 0;
BA_ "GenSigTimeoutTime_HU_High_X451" SG_ 1142 CCM_MTO_Failure_Status 0;
BA_ "GenSigTimeoutTime_HU_Mid_X451" SG_ 1142 CCM_MTO_Failure_Status 0;
BA_ "GenSigCycleTime" SG_ 1142 CCM_Invalid_Failure_Status 100;
BA_ "GenSigCycleTimeActive" SG_ 1142 CCM_Invalid_Failure_Status 100;
BA_ "GenSigSendType" SG_ 1142 CCM_Invalid_Failure_Status 7;
BA_ "GenSigTimeoutMsg_HU_A" SG_ 1142 CCM_Invalid_Failure_Status 0;
BA_ "GenSigTimeoutMsg_HU_B" SG_ 1142 CCM_Invalid_Failure_Status 0;
BA_ "GenSigTimeoutMsg_HU_High_X451" SG_ 1142 CCM_Invalid_Failure_Status 0;
BA_ "GenSigTimeoutMsg_HU_Mid_X451" SG_ 1142 CCM_Invalid_Failure_Status 0;
BA_ "GenSigTimeoutTime_HU_A" SG_ 1142 CCM_Invalid_Failure_Status 0;
BA_ "GenSigTimeoutTime_HU_B" SG_ 1142 CCM_Invalid_Failure_Status 0;
BA_ "GenSigTimeoutTime_HU_High_X451" SG_ 1142 CCM_Invalid_Failure_Status 0;
BA_ "GenSigTimeoutTime_HU_Mid_X451" SG_ 1142 CCM_Invalid_Failure_Status 0;
BA_ "GenSigCycleTime" SG_ 1142 BCmInvalidFailureStatus 100;
BA_ "GenSigCycleTimeActive" SG_ 1142 BCmInvalidFailureStatus 100;
BA_ "GenSigSendType" SG_ 1142 BCmInvalidFailureStatus 7;
BA_ "GenSigTimeoutMsg_HU_A" SG_ 1142 BCmInvalidFailureStatus 0;
BA_ "GenSigTimeoutMsg_HU_B" SG_ 1142 BCmInvalidFailureStatus 0;
BA_ "GenSigTimeoutMsg_HU_High_X451" SG_ 1142 BCmInvalidFailureStatus 0;
BA_ "GenSigTimeoutMsg_HU_Mid_X451" SG_ 1142 BCmInvalidFailureStatus 0;
BA_ "GenSigTimeoutTime_HU_A" SG_ 1142 BCmInvalidFailureStatus 0;
BA_ "GenSigTimeoutTime_HU_B" SG_ 1142 BCmInvalidFailureStatus 0;
BA_ "GenSigTimeoutTime_HU_High_X451" SG_ 1142 BCmInvalidFailureStatus 0;
BA_ "GenSigTimeoutTime_HU_Mid_X451" SG_ 1142 BCmInvalidFailureStatus 0;
BA_ "GenSigCycleTime" SG_ 1142 BCmMToFailureStatus 100;
BA_ "GenSigCycleTimeActive" SG_ 1142 BCmMToFailureStatus 100;
BA_ "GenSigSendType" SG_ 1142 BCmMToFailureStatus 7;
BA_ "GenSigTimeoutMsg_HU_A" SG_ 1142 BCmMToFailureStatus 0;
BA_ "GenSigTimeoutMsg_HU_B" SG_ 1142 BCmMToFailureStatus 0;
BA_ "GenSigTimeoutMsg_HU_High_X451" SG_ 1142 BCmMToFailureStatus 0;
BA_ "GenSigTimeoutMsg_HU_Mid_X451" SG_ 1142 BCmMToFailureStatus 0;
BA_ "GenSigTimeoutTime_HU_A" SG_ 1142 BCmMToFailureStatus 0;
BA_ "GenSigTimeoutTime_HU_B" SG_ 1142 BCmMToFailureStatus 0;
BA_ "GenSigTimeoutTime_HU_High_X451" SG_ 1142 BCmMToFailureStatus 0;
BA_ "GenSigTimeoutTime_HU_Mid_X451" SG_ 1142 BCmMToFailureStatus 0;
BA_ "GenSigTimeoutTime_HU_Mid_X445" SG_ 581 CoolingPwrFdbkVal 0;
BA_ "GenSigTimeoutTime_HU_High_X445" SG_ 581 CoolingPwrFdbkVal 0;
BA_ "GenSigTimeoutMsg_HU_Mid_X445" SG_ 581 CoolingPwrFdbkVal 0;
BA_ "GenSigTimeoutMsg_HU_High_X445" SG_ 581 CoolingPwrFdbkVal 0;
BA_ "GenSigCycleTime" SG_ 581 CoolingPwrFdbkVal 100;
BA_ "GenSigCycleTimeActive" SG_ 581 CoolingPwrFdbkVal 100;
BA_ "GenSigSendType" SG_ 581 CoolingPwrFdbkVal 7;
BA_ "GenSigTimeoutMsg_HU_A" SG_ 581 CoolingPwrFdbkVal 0;
BA_ "GenSigTimeoutMsg_HU_B" SG_ 581 CoolingPwrFdbkVal 0;
BA_ "GenSigTimeoutMsg_HU_High_X451" SG_ 581 CoolingPwrFdbkVal 0;
BA_ "GenSigTimeoutMsg_HU_Mid_X451" SG_ 581 CoolingPwrFdbkVal 0;
BA_ "GenSigTimeoutTime_HU_A" SG_ 581 CoolingPwrFdbkVal 0;
BA_ "GenSigTimeoutTime_HU_B" SG_ 581 CoolingPwrFdbkVal 0;
BA_ "GenSigTimeoutTime_HU_High_X451" SG_ 581 CoolingPwrFdbkVal 0;
BA_ "GenSigTimeoutTime_HU_Mid_X451" SG_ 581 CoolingPwrFdbkVal 0;
BA_ "GenSigTimeoutTime_HU_Mid_X445" SG_ 581 HeatingPwrFdbkVal 0;
BA_ "GenSigTimeoutTime_HU_High_X445" SG_ 581 HeatingPwrFdbkVal 0;
BA_ "GenSigTimeoutMsg_HU_Mid_X445" SG_ 581 HeatingPwrFdbkVal 0;
BA_ "GenSigTimeoutMsg_HU_High_X445" SG_ 581 HeatingPwrFdbkVal 0;
BA_ "GenSigCycleTime" SG_ 581 HeatingPwrFdbkVal 100;
BA_ "GenSigCycleTimeActive" SG_ 581 HeatingPwrFdbkVal 100;
BA_ "GenSigSendType" SG_ 581 HeatingPwrFdbkVal 7;
BA_ "GenSigTimeoutMsg_HU_A" SG_ 581 HeatingPwrFdbkVal 0;
BA_ "GenSigTimeoutMsg_HU_B" SG_ 581 HeatingPwrFdbkVal 0;
BA_ "GenSigTimeoutMsg_HU_High_X451" SG_ 581 HeatingPwrFdbkVal 0;
BA_ "GenSigTimeoutMsg_HU_Mid_X451" SG_ 581 HeatingPwrFdbkVal 0;
BA_ "GenSigTimeoutTime_HU_A" SG_ 581 HeatingPwrFdbkVal 0;
BA_ "GenSigTimeoutTime_HU_B" SG_ 581 HeatingPwrFdbkVal 0;
BA_ "GenSigTimeoutTime_HU_High_X451" SG_ 581 HeatingPwrFdbkVal 0;
BA_ "GenSigTimeoutTime_HU_Mid_X451" SG_ 581 HeatingPwrFdbkVal 0;
BA_ "GenSigCycleTime" SG_ 581 CabinCoolingSolValveStateStatus 100;
BA_ "GenSigCycleTimeActive" SG_ 581 CabinCoolingSolValveStateStatus 100;
BA_ "GenSigSendType" SG_ 581 CabinCoolingSolValveStateStatus 7;
BA_ "GenSigTimeoutMsg_HU_A" SG_ 581 CabinCoolingSolValveStateStatus 0;
BA_ "GenSigTimeoutMsg_HU_B" SG_ 581 CabinCoolingSolValveStateStatus 0;
BA_ "GenSigTimeoutMsg_HU_High_X451" SG_ 581 CabinCoolingSolValveStateStatus 0;
BA_ "GenSigTimeoutMsg_HU_Mid_X451" SG_ 581 CabinCoolingSolValveStateStatus 0;
BA_ "GenSigTimeoutTime_HU_A" SG_ 581 CabinCoolingSolValveStateStatus 0;
BA_ "GenSigTimeoutTime_HU_B" SG_ 581 CabinCoolingSolValveStateStatus 0;
BA_ "GenSigTimeoutTime_HU_High_X451" SG_ 581 CabinCoolingSolValveStateStatus 0;
BA_ "GenSigTimeoutTime_HU_Mid_X451" SG_ 581 CabinCoolingSolValveStateStatus 0;
BA_ "GenSigCycleTime" SG_ 581 CabinCoolingSolValveState 100;
BA_ "GenSigCycleTimeActive" SG_ 581 CabinCoolingSolValveState 100;
BA_ "GenSigSendType" SG_ 581 CabinCoolingSolValveState 7;
BA_ "GenSigTimeoutMsg_HU_A" SG_ 581 CabinCoolingSolValveState 0;
BA_ "GenSigTimeoutMsg_HU_B" SG_ 581 CabinCoolingSolValveState 0;
BA_ "GenSigTimeoutMsg_HU_High_X451" SG_ 581 CabinCoolingSolValveState 0;
BA_ "GenSigTimeoutMsg_HU_Mid_X451" SG_ 581 CabinCoolingSolValveState 0;
BA_ "GenSigTimeoutTime_HU_A" SG_ 581 CabinCoolingSolValveState 0;
BA_ "GenSigTimeoutTime_HU_B" SG_ 581 CabinCoolingSolValveState 0;
BA_ "GenSigTimeoutTime_HU_High_X451" SG_ 581 CabinCoolingSolValveState 0;
BA_ "GenSigTimeoutTime_HU_Mid_X451" SG_ 581 CabinCoolingSolValveState 0;
BA_ "GenSigCycleTime" SG_ 581 LowHVBatteryChargeStatus 100;
BA_ "GenSigCycleTimeActive" SG_ 581 LowHVBatteryChargeStatus 100;
BA_ "GenSigSendType" SG_ 581 LowHVBatteryChargeStatus 7;
BA_ "GenSigTimeoutMsg_HU_A" SG_ 581 LowHVBatteryChargeStatus 0;
BA_ "GenSigTimeoutMsg_HU_B" SG_ 581 LowHVBatteryChargeStatus 0;
BA_ "GenSigTimeoutMsg_HU_High_X451" SG_ 581 LowHVBatteryChargeStatus 0;
BA_ "GenSigTimeoutMsg_HU_Mid_X451" SG_ 581 LowHVBatteryChargeStatus 0;
BA_ "GenSigTimeoutTime_HU_A" SG_ 581 LowHVBatteryChargeStatus 0;
BA_ "GenSigTimeoutTime_HU_B" SG_ 581 LowHVBatteryChargeStatus 0;
BA_ "GenSigTimeoutTime_HU_High_X451" SG_ 581 LowHVBatteryChargeStatus 0;
BA_ "GenSigTimeoutTime_HU_Mid_X451" SG_ 581 LowHVBatteryChargeStatus 0;
BA_ "GenSigCycleTime" SG_ 581 LowHVBatteryCharge 100;
BA_ "GenSigCycleTimeActive" SG_ 581 LowHVBatteryCharge 100;
BA_ "GenSigSendType" SG_ 581 LowHVBatteryCharge 7;
BA_ "GenSigTimeoutMsg_HU_A" SG_ 581 LowHVBatteryCharge 0;
BA_ "GenSigTimeoutMsg_HU_B" SG_ 581 LowHVBatteryCharge 0;
BA_ "GenSigTimeoutMsg_HU_High_X451" SG_ 581 LowHVBatteryCharge 0;
BA_ "GenSigTimeoutMsg_HU_Mid_X451" SG_ 581 LowHVBatteryCharge 0;
BA_ "GenSigTimeoutTime_HU_A" SG_ 581 LowHVBatteryCharge 0;
BA_ "GenSigTimeoutTime_HU_B" SG_ 581 LowHVBatteryCharge 0;
BA_ "GenSigTimeoutTime_HU_High_X451" SG_ 581 LowHVBatteryCharge 0;
BA_ "GenSigTimeoutTime_HU_Mid_X451" SG_ 581 LowHVBatteryCharge 0;
BA_ "GenSigCycleTime" SG_ 581 LowLVBatteryChargeStatus 100;
BA_ "GenSigCycleTimeActive" SG_ 581 LowLVBatteryChargeStatus 100;
BA_ "GenSigSendType" SG_ 581 LowLVBatteryChargeStatus 7;
BA_ "GenSigTimeoutMsg_HU_A" SG_ 581 LowLVBatteryChargeStatus 0;
BA_ "GenSigTimeoutMsg_HU_B" SG_ 581 LowLVBatteryChargeStatus 0;
BA_ "GenSigTimeoutMsg_HU_High_X451" SG_ 581 LowLVBatteryChargeStatus 0;
BA_ "GenSigTimeoutMsg_HU_Mid_X451" SG_ 581 LowLVBatteryChargeStatus 0;
BA_ "GenSigTimeoutTime_HU_A" SG_ 581 LowLVBatteryChargeStatus 0;
BA_ "GenSigTimeoutTime_HU_B" SG_ 581 LowLVBatteryChargeStatus 0;
BA_ "GenSigTimeoutTime_HU_High_X451" SG_ 581 LowLVBatteryChargeStatus 0;
BA_ "GenSigTimeoutTime_HU_Mid_X451" SG_ 581 LowLVBatteryChargeStatus 0;
BA_ "GenSigCycleTime" SG_ 581 LowLVBatteryCharge 100;
BA_ "GenSigCycleTimeActive" SG_ 581 LowLVBatteryCharge 100;
BA_ "GenSigSendType" SG_ 581 LowLVBatteryCharge 7;
BA_ "GenSigTimeoutMsg_HU_A" SG_ 581 LowLVBatteryCharge 0;
BA_ "GenSigTimeoutMsg_HU_B" SG_ 581 LowLVBatteryCharge 0;
BA_ "GenSigTimeoutMsg_HU_High_X451" SG_ 581 LowLVBatteryCharge 0;
BA_ "GenSigTimeoutMsg_HU_Mid_X451" SG_ 581 LowLVBatteryCharge 0;
BA_ "GenSigTimeoutTime_HU_A" SG_ 581 LowLVBatteryCharge 0;
BA_ "GenSigTimeoutTime_HU_B" SG_ 581 LowLVBatteryCharge 0;
BA_ "GenSigTimeoutTime_HU_High_X451" SG_ 581 LowLVBatteryCharge 0;
BA_ "GenSigTimeoutTime_HU_Mid_X451" SG_ 581 LowLVBatteryCharge 0;
BA_ "GenSigCycleTime" SG_ 581 HvAmpHrStatus 100;
BA_ "GenSigCycleTimeActive" SG_ 581 HvAmpHrStatus 100;
BA_ "GenSigSendType" SG_ 581 HvAmpHrStatus 7;
BA_ "GenSigTimeoutMsg_HU_A" SG_ 581 HvAmpHrStatus 0;
BA_ "GenSigTimeoutMsg_HU_B" SG_ 581 HvAmpHrStatus 0;
BA_ "GenSigTimeoutMsg_HU_High_X451" SG_ 581 HvAmpHrStatus 0;
BA_ "GenSigTimeoutMsg_HU_Mid_X451" SG_ 581 HvAmpHrStatus 0;
BA_ "GenSigTimeoutTime_HU_A" SG_ 581 HvAmpHrStatus 0;
BA_ "GenSigTimeoutTime_HU_B" SG_ 581 HvAmpHrStatus 0;
BA_ "GenSigTimeoutTime_HU_High_X451" SG_ 581 HvAmpHrStatus 0;
BA_ "GenSigTimeoutTime_HU_Mid_X451" SG_ 581 HvAmpHrStatus 0;
BA_ "GenSigCycleTime" SG_ 581 HvAmpHr 100;
BA_ "GenSigCycleTimeActive" SG_ 581 HvAmpHr 100;
BA_ "GenSigSendType" SG_ 581 HvAmpHr 7;
BA_ "GenSigTimeoutMsg_HU_A" SG_ 581 HvAmpHr 0;
BA_ "GenSigTimeoutMsg_HU_B" SG_ 581 HvAmpHr 0;
BA_ "GenSigTimeoutMsg_HU_High_X451" SG_ 581 HvAmpHr 0;
BA_ "GenSigTimeoutMsg_HU_Mid_X451" SG_ 581 HvAmpHr 0;
BA_ "GenSigTimeoutTime_HU_A" SG_ 581 HvAmpHr 0;
BA_ "GenSigTimeoutTime_HU_B" SG_ 581 HvAmpHr 0;
BA_ "GenSigTimeoutTime_HU_High_X451" SG_ 581 HvAmpHr 0;
BA_ "GenSigTimeoutTime_HU_Mid_X451" SG_ 581 HvAmpHr 0;
BA_ "GenSigCycleTime" SG_ 1288 PartialNetworkInformation_TCU 200;
BA_ "GenSigCycleTimeActive" SG_ 1288 PartialNetworkInformation_TCU 200;
BA_ "GenSigSendType" SG_ 1288 PartialNetworkInformation_TCU 7;
BA_ "GenSigTimeoutMsg_HU_A" SG_ 1288 PartialNetworkInformation_TCU 0;
BA_ "GenSigTimeoutMsg_HU_B" SG_ 1288 PartialNetworkInformation_TCU 0;
BA_ "GenSigTimeoutMsg_HU_High_X451" SG_ 1288 PartialNetworkInformation_TCU 0;
BA_ "GenSigTimeoutMsg_HU_Mid_X451" SG_ 1288 PartialNetworkInformation_TCU 0;
BA_ "GenSigTimeoutTime_HU_A" SG_ 1288 PartialNetworkInformation_TCU 0;
BA_ "GenSigTimeoutTime_HU_B" SG_ 1288 PartialNetworkInformation_TCU 0;
BA_ "GenSigTimeoutTime_HU_High_X451" SG_ 1288 PartialNetworkInformation_TCU 0;
BA_ "GenSigTimeoutTime_HU_Mid_X451" SG_ 1288 PartialNetworkInformation_TCU 0;
BA_ "GenSigCycleTime" SG_ 1288 Reserved55 200;
BA_ "GenSigCycleTimeActive" SG_ 1288 Reserved55 200;
BA_ "GenSigSendType" SG_ 1288 Reserved55 7;
BA_ "GenSigTimeoutMsg_HU_A" SG_ 1288 Reserved55 0;
BA_ "GenSigTimeoutMsg_HU_B" SG_ 1288 Reserved55 0;
BA_ "GenSigTimeoutMsg_HU_High_X451" SG_ 1288 Reserved55 0;
BA_ "GenSigTimeoutMsg_HU_Mid_X451" SG_ 1288 Reserved55 0;
BA_ "GenSigTimeoutTime_HU_A" SG_ 1288 Reserved55 0;
BA_ "GenSigTimeoutTime_HU_B" SG_ 1288 Reserved55 0;
BA_ "GenSigTimeoutTime_HU_High_X451" SG_ 1288 Reserved55 0;
BA_ "GenSigTimeoutTime_HU_Mid_X451" SG_ 1288 Reserved55 0;
BA_ "GenSigCycleTime" SG_ 1288 Reserved54 200;
BA_ "GenSigCycleTimeActive" SG_ 1288 Reserved54 200;
BA_ "GenSigSendType" SG_ 1288 Reserved54 7;
BA_ "GenSigTimeoutMsg_HU_A" SG_ 1288 Reserved54 0;
BA_ "GenSigTimeoutMsg_HU_B" SG_ 1288 Reserved54 0;
BA_ "GenSigTimeoutMsg_HU_High_X451" SG_ 1288 Reserved54 0;
BA_ "GenSigTimeoutMsg_HU_Mid_X451" SG_ 1288 Reserved54 0;
BA_ "GenSigTimeoutTime_HU_A" SG_ 1288 Reserved54 0;
BA_ "GenSigTimeoutTime_HU_B" SG_ 1288 Reserved54 0;
BA_ "GenSigTimeoutTime_HU_High_X451" SG_ 1288 Reserved54 0;
BA_ "GenSigTimeoutTime_HU_Mid_X451" SG_ 1288 Reserved54 0;
BA_ "GenSigCycleTime" SG_ 1288 Reserved53 200;
BA_ "GenSigCycleTimeActive" SG_ 1288 Reserved53 200;
BA_ "GenSigSendType" SG_ 1288 Reserved53 7;
BA_ "GenSigTimeoutMsg_HU_A" SG_ 1288 Reserved53 0;
BA_ "GenSigTimeoutMsg_HU_B" SG_ 1288 Reserved53 0;
BA_ "GenSigTimeoutMsg_HU_High_X451" SG_ 1288 Reserved53 0;
BA_ "GenSigTimeoutMsg_HU_Mid_X451" SG_ 1288 Reserved53 0;
BA_ "GenSigTimeoutTime_HU_A" SG_ 1288 Reserved53 0;
BA_ "GenSigTimeoutTime_HU_B" SG_ 1288 Reserved53 0;
BA_ "GenSigTimeoutTime_HU_High_X451" SG_ 1288 Reserved53 0;
BA_ "GenSigTimeoutTime_HU_Mid_X451" SG_ 1288 Reserved53 0;
BA_ "GenSigCycleTime" SG_ 1288 Reserved52 200;
BA_ "GenSigCycleTimeActive" SG_ 1288 Reserved52 200;
BA_ "GenSigSendType" SG_ 1288 Reserved52 7;
BA_ "GenSigTimeoutMsg_HU_A" SG_ 1288 Reserved52 0;
BA_ "GenSigTimeoutMsg_HU_B" SG_ 1288 Reserved52 0;
BA_ "GenSigTimeoutMsg_HU_High_X451" SG_ 1288 Reserved52 0;
BA_ "GenSigTimeoutMsg_HU_Mid_X451" SG_ 1288 Reserved52 0;
BA_ "GenSigTimeoutTime_HU_A" SG_ 1288 Reserved52 0;
BA_ "GenSigTimeoutTime_HU_B" SG_ 1288 Reserved52 0;
BA_ "GenSigTimeoutTime_HU_High_X451" SG_ 1288 Reserved52 0;
BA_ "GenSigTimeoutTime_HU_Mid_X451" SG_ 1288 Reserved52 0;
BA_ "GenSigCycleTime" SG_ 1288 Reserved51 200;
BA_ "GenSigCycleTimeActive" SG_ 1288 Reserved51 200;
BA_ "GenSigSendType" SG_ 1288 Reserved51 7;
BA_ "GenSigTimeoutMsg_HU_A" SG_ 1288 Reserved51 0;
BA_ "GenSigTimeoutMsg_HU_B" SG_ 1288 Reserved51 0;
BA_ "GenSigTimeoutMsg_HU_High_X451" SG_ 1288 Reserved51 0;
BA_ "GenSigTimeoutMsg_HU_Mid_X451" SG_ 1288 Reserved51 0;
BA_ "GenSigTimeoutTime_HU_A" SG_ 1288 Reserved51 0;
BA_ "GenSigTimeoutTime_HU_B" SG_ 1288 Reserved51 0;
BA_ "GenSigTimeoutTime_HU_High_X451" SG_ 1288 Reserved51 0;
BA_ "GenSigTimeoutTime_HU_Mid_X451" SG_ 1288 Reserved51 0;
BA_ "GenSigCycleTime" SG_ 1288 Reserved50 200;
BA_ "GenSigCycleTimeActive" SG_ 1288 Reserved50 200;
BA_ "GenSigSendType" SG_ 1288 Reserved50 7;
BA_ "GenSigTimeoutMsg_HU_A" SG_ 1288 Reserved50 0;
BA_ "GenSigTimeoutMsg_HU_B" SG_ 1288 Reserved50 0;
BA_ "GenSigTimeoutMsg_HU_High_X451" SG_ 1288 Reserved50 0;
BA_ "GenSigTimeoutMsg_HU_Mid_X451" SG_ 1288 Reserved50 0;
BA_ "GenSigTimeoutTime_HU_A" SG_ 1288 Reserved50 0;
BA_ "GenSigTimeoutTime_HU_B" SG_ 1288 Reserved50 0;
BA_ "GenSigTimeoutTime_HU_High_X451" SG_ 1288 Reserved50 0;
BA_ "GenSigTimeoutTime_HU_Mid_X451" SG_ 1288 Reserved50 0;
BA_ "GenSigCycleTime" SG_ 1288 Reserved49 200;
BA_ "GenSigCycleTimeActive" SG_ 1288 Reserved49 200;
BA_ "GenSigSendType" SG_ 1288 Reserved49 7;
BA_ "GenSigTimeoutMsg_HU_A" SG_ 1288 Reserved49 0;
BA_ "GenSigTimeoutMsg_HU_B" SG_ 1288 Reserved49 0;
BA_ "GenSigTimeoutMsg_HU_High_X451" SG_ 1288 Reserved49 0;
BA_ "GenSigTimeoutMsg_HU_Mid_X451" SG_ 1288 Reserved49 0;
BA_ "GenSigTimeoutTime_HU_A" SG_ 1288 Reserved49 0;
BA_ "GenSigTimeoutTime_HU_B" SG_ 1288 Reserved49 0;
BA_ "GenSigTimeoutTime_HU_High_X451" SG_ 1288 Reserved49 0;
BA_ "GenSigTimeoutTime_HU_Mid_X451" SG_ 1288 Reserved49 0;
BA_ "GenSigCycleTime" SG_ 1288 Reserved48 200;
BA_ "GenSigCycleTimeActive" SG_ 1288 Reserved48 200;
BA_ "GenSigSendType" SG_ 1288 Reserved48 7;
BA_ "GenSigTimeoutMsg_HU_A" SG_ 1288 Reserved48 0;
BA_ "GenSigTimeoutMsg_HU_B" SG_ 1288 Reserved48 0;
BA_ "GenSigTimeoutMsg_HU_High_X451" SG_ 1288 Reserved48 0;
BA_ "GenSigTimeoutMsg_HU_Mid_X451" SG_ 1288 Reserved48 0;
BA_ "GenSigTimeoutTime_HU_A" SG_ 1288 Reserved48 0;
BA_ "GenSigTimeoutTime_HU_B" SG_ 1288 Reserved48 0;
BA_ "GenSigTimeoutTime_HU_High_X451" SG_ 1288 Reserved48 0;
BA_ "GenSigTimeoutTime_HU_Mid_X451" SG_ 1288 Reserved48 0;
BA_ "GenSigCycleTime" SG_ 1288 RepeatMessageReq_TCU 200;
BA_ "GenSigCycleTimeActive" SG_ 1288 RepeatMessageReq_TCU 200;
BA_ "GenSigSendType" SG_ 1288 RepeatMessageReq_TCU 7;
BA_ "GenSigTimeoutMsg_HU_A" SG_ 1288 RepeatMessageReq_TCU 0;
BA_ "GenSigTimeoutMsg_HU_B" SG_ 1288 RepeatMessageReq_TCU 0;
BA_ "GenSigTimeoutMsg_HU_High_X451" SG_ 1288 RepeatMessageReq_TCU 0;
BA_ "GenSigTimeoutMsg_HU_Mid_X451" SG_ 1288 RepeatMessageReq_TCU 0;
BA_ "GenSigTimeoutTime_HU_A" SG_ 1288 RepeatMessageReq_TCU 0;
BA_ "GenSigTimeoutTime_HU_B" SG_ 1288 RepeatMessageReq_TCU 0;
BA_ "GenSigTimeoutTime_HU_High_X451" SG_ 1288 RepeatMessageReq_TCU 0;
BA_ "GenSigTimeoutTime_HU_Mid_X451" SG_ 1288 RepeatMessageReq_TCU 0;
BA_ "GenSigCycleTime" SG_ 1288 PreviousState_TCU 200;
BA_ "GenSigCycleTimeActive" SG_ 1288 PreviousState_TCU 200;
BA_ "GenSigSendType" SG_ 1288 PreviousState_TCU 7;
BA_ "GenSigTimeoutMsg_HU_A" SG_ 1288 PreviousState_TCU 0;
BA_ "GenSigTimeoutMsg_HU_B" SG_ 1288 PreviousState_TCU 0;
BA_ "GenSigTimeoutMsg_HU_High_X451" SG_ 1288 PreviousState_TCU 0;
BA_ "GenSigTimeoutMsg_HU_Mid_X451" SG_ 1288 PreviousState_TCU 0;
BA_ "GenSigTimeoutTime_HU_A" SG_ 1288 PreviousState_TCU 0;
BA_ "GenSigTimeoutTime_HU_B" SG_ 1288 PreviousState_TCU 0;
BA_ "GenSigTimeoutTime_HU_High_X451" SG_ 1288 PreviousState_TCU 0;
BA_ "GenSigTimeoutTime_HU_Mid_X451" SG_ 1288 PreviousState_TCU 0;
BA_ "GenSigCycleTime" SG_ 1288 NMCoOrdSlpReady_TCU 200;
BA_ "GenSigCycleTimeActive" SG_ 1288 NMCoOrdSlpReady_TCU 200;
BA_ "GenSigSendType" SG_ 1288 NMCoOrdSlpReady_TCU 7;
BA_ "GenSigTimeoutMsg_HU_A" SG_ 1288 NMCoOrdSlpReady_TCU 0;
BA_ "GenSigTimeoutMsg_HU_B" SG_ 1288 NMCoOrdSlpReady_TCU 0;
BA_ "GenSigTimeoutMsg_HU_High_X451" SG_ 1288 NMCoOrdSlpReady_TCU 0;
BA_ "GenSigTimeoutMsg_HU_Mid_X451" SG_ 1288 NMCoOrdSlpReady_TCU 0;
BA_ "GenSigTimeoutTime_HU_A" SG_ 1288 NMCoOrdSlpReady_TCU 0;
BA_ "GenSigTimeoutTime_HU_B" SG_ 1288 NMCoOrdSlpReady_TCU 0;
BA_ "GenSigTimeoutTime_HU_High_X451" SG_ 1288 NMCoOrdSlpReady_TCU 0;
BA_ "GenSigTimeoutTime_HU_Mid_X451" SG_ 1288 NMCoOrdSlpReady_TCU 0;
BA_ "GenSigCycleTime" SG_ 1288 CurrentState_TCU 200;
BA_ "GenSigCycleTimeActive" SG_ 1288 CurrentState_TCU 200;
BA_ "GenSigSendType" SG_ 1288 CurrentState_TCU 7;
BA_ "GenSigTimeoutMsg_HU_A" SG_ 1288 CurrentState_TCU 0;
BA_ "GenSigTimeoutMsg_HU_B" SG_ 1288 CurrentState_TCU 0;
BA_ "GenSigTimeoutMsg_HU_High_X451" SG_ 1288 CurrentState_TCU 0;
BA_ "GenSigTimeoutMsg_HU_Mid_X451" SG_ 1288 CurrentState_TCU 0;
BA_ "GenSigTimeoutTime_HU_A" SG_ 1288 CurrentState_TCU 0;
BA_ "GenSigTimeoutTime_HU_B" SG_ 1288 CurrentState_TCU 0;
BA_ "GenSigTimeoutTime_HU_High_X451" SG_ 1288 CurrentState_TCU 0;
BA_ "GenSigTimeoutTime_HU_Mid_X451" SG_ 1288 CurrentState_TCU 0;
BA_ "GenSigCycleTime" SG_ 1288 TCU_NMPDU_USER_DATA_D5 200;
BA_ "GenSigCycleTimeActive" SG_ 1288 TCU_NMPDU_USER_DATA_D5 200;
BA_ "GenSigSendType" SG_ 1288 TCU_NMPDU_USER_DATA_D5 7;
BA_ "GenSigTimeoutMsg_HU_A" SG_ 1288 TCU_NMPDU_USER_DATA_D5 0;
BA_ "GenSigTimeoutMsg_HU_B" SG_ 1288 TCU_NMPDU_USER_DATA_D5 0;
BA_ "GenSigTimeoutMsg_HU_High_X451" SG_ 1288 TCU_NMPDU_USER_DATA_D5 0;
BA_ "GenSigTimeoutMsg_HU_Mid_X451" SG_ 1288 TCU_NMPDU_USER_DATA_D5 0;
BA_ "GenSigTimeoutTime_HU_A" SG_ 1288 TCU_NMPDU_USER_DATA_D5 0;
BA_ "GenSigTimeoutTime_HU_B" SG_ 1288 TCU_NMPDU_USER_DATA_D5 0;
BA_ "GenSigTimeoutTime_HU_High_X451" SG_ 1288 TCU_NMPDU_USER_DATA_D5 0;
BA_ "GenSigTimeoutTime_HU_Mid_X451" SG_ 1288 TCU_NMPDU_USER_DATA_D5 0;
BA_ "GenSigCycleTime" SG_ 1288 TCU_NMPDU_USER_DATA_D4 200;
BA_ "GenSigCycleTimeActive" SG_ 1288 TCU_NMPDU_USER_DATA_D4 200;
BA_ "GenSigSendType" SG_ 1288 TCU_NMPDU_USER_DATA_D4 7;
BA_ "GenSigTimeoutMsg_HU_A" SG_ 1288 TCU_NMPDU_USER_DATA_D4 0;
BA_ "GenSigTimeoutMsg_HU_B" SG_ 1288 TCU_NMPDU_USER_DATA_D4 0;
BA_ "GenSigTimeoutMsg_HU_High_X451" SG_ 1288 TCU_NMPDU_USER_DATA_D4 0;
BA_ "GenSigTimeoutMsg_HU_Mid_X451" SG_ 1288 TCU_NMPDU_USER_DATA_D4 0;
BA_ "GenSigTimeoutTime_HU_A" SG_ 1288 TCU_NMPDU_USER_DATA_D4 0;
BA_ "GenSigTimeoutTime_HU_B" SG_ 1288 TCU_NMPDU_USER_DATA_D4 0;
BA_ "GenSigTimeoutTime_HU_High_X451" SG_ 1288 TCU_NMPDU_USER_DATA_D4 0;
BA_ "GenSigTimeoutTime_HU_Mid_X451" SG_ 1288 TCU_NMPDU_USER_DATA_D4 0;
BA_ "GenSigCycleTime" SG_ 1288 TCU_NMPDU_USER_DATA_D3 200;
BA_ "GenSigCycleTimeActive" SG_ 1288 TCU_NMPDU_USER_DATA_D3 200;
BA_ "GenSigSendType" SG_ 1288 TCU_NMPDU_USER_DATA_D3 7;
BA_ "GenSigTimeoutMsg_HU_A" SG_ 1288 TCU_NMPDU_USER_DATA_D3 0;
BA_ "GenSigTimeoutMsg_HU_B" SG_ 1288 TCU_NMPDU_USER_DATA_D3 0;
BA_ "GenSigTimeoutMsg_HU_High_X451" SG_ 1288 TCU_NMPDU_USER_DATA_D3 0;
BA_ "GenSigTimeoutMsg_HU_Mid_X451" SG_ 1288 TCU_NMPDU_USER_DATA_D3 0;
BA_ "GenSigTimeoutTime_HU_A" SG_ 1288 TCU_NMPDU_USER_DATA_D3 0;
BA_ "GenSigTimeoutTime_HU_B" SG_ 1288 TCU_NMPDU_USER_DATA_D3 0;
BA_ "GenSigTimeoutTime_HU_High_X451" SG_ 1288 TCU_NMPDU_USER_DATA_D3 0;
BA_ "GenSigTimeoutTime_HU_Mid_X451" SG_ 1288 TCU_NMPDU_USER_DATA_D3 0;
BA_ "GenSigCycleTime" SG_ 1288 TCU_NMPDU_USER_DATA_D2 200;
BA_ "GenSigCycleTimeActive" SG_ 1288 TCU_NMPDU_USER_DATA_D2 200;
BA_ "GenSigSendType" SG_ 1288 TCU_NMPDU_USER_DATA_D2 7;
BA_ "GenSigTimeoutMsg_HU_A" SG_ 1288 TCU_NMPDU_USER_DATA_D2 0;
BA_ "GenSigTimeoutMsg_HU_B" SG_ 1288 TCU_NMPDU_USER_DATA_D2 0;
BA_ "GenSigTimeoutMsg_HU_High_X451" SG_ 1288 TCU_NMPDU_USER_DATA_D2 0;
BA_ "GenSigTimeoutMsg_HU_Mid_X451" SG_ 1288 TCU_NMPDU_USER_DATA_D2 0;
BA_ "GenSigTimeoutTime_HU_A" SG_ 1288 TCU_NMPDU_USER_DATA_D2 0;
BA_ "GenSigTimeoutTime_HU_B" SG_ 1288 TCU_NMPDU_USER_DATA_D2 0;
BA_ "GenSigTimeoutTime_HU_High_X451" SG_ 1288 TCU_NMPDU_USER_DATA_D2 0;
BA_ "GenSigTimeoutTime_HU_Mid_X451" SG_ 1288 TCU_NMPDU_USER_DATA_D2 0;
BA_ "GenSigCycleTime" SG_ 1288 TCU_NMPDU_USER_DATA_D1 200;
BA_ "GenSigCycleTimeActive" SG_ 1288 TCU_NMPDU_USER_DATA_D1 200;
BA_ "GenSigSendType" SG_ 1288 TCU_NMPDU_USER_DATA_D1 7;
BA_ "GenSigTimeoutMsg_HU_A" SG_ 1288 TCU_NMPDU_USER_DATA_D1 0;
BA_ "GenSigTimeoutMsg_HU_B" SG_ 1288 TCU_NMPDU_USER_DATA_D1 0;
BA_ "GenSigTimeoutMsg_HU_High_X451" SG_ 1288 TCU_NMPDU_USER_DATA_D1 0;
BA_ "GenSigTimeoutMsg_HU_Mid_X451" SG_ 1288 TCU_NMPDU_USER_DATA_D1 0;
BA_ "GenSigTimeoutTime_HU_A" SG_ 1288 TCU_NMPDU_USER_DATA_D1 0;
BA_ "GenSigTimeoutTime_HU_B" SG_ 1288 TCU_NMPDU_USER_DATA_D1 0;
BA_ "GenSigTimeoutTime_HU_High_X451" SG_ 1288 TCU_NMPDU_USER_DATA_D1 0;
BA_ "GenSigTimeoutTime_HU_Mid_X451" SG_ 1288 TCU_NMPDU_USER_DATA_D1 0;
BA_ "GenSigCycleTime" SG_ 1288 TCU_NMPDU_SRC_ECU_ID 200;
BA_ "GenSigCycleTimeActive" SG_ 1288 TCU_NMPDU_SRC_ECU_ID 200;
BA_ "GenSigSendType" SG_ 1288 TCU_NMPDU_SRC_ECU_ID 7;
BA_ "GenSigTimeoutMsg_HU_A" SG_ 1288 TCU_NMPDU_SRC_ECU_ID 0;
BA_ "GenSigTimeoutMsg_HU_B" SG_ 1288 TCU_NMPDU_SRC_ECU_ID 0;
BA_ "GenSigTimeoutMsg_HU_High_X451" SG_ 1288 TCU_NMPDU_SRC_ECU_ID 0;
BA_ "GenSigTimeoutMsg_HU_Mid_X451" SG_ 1288 TCU_NMPDU_SRC_ECU_ID 0;
BA_ "GenSigTimeoutTime_HU_A" SG_ 1288 TCU_NMPDU_SRC_ECU_ID 0;
BA_ "GenSigTimeoutTime_HU_B" SG_ 1288 TCU_NMPDU_SRC_ECU_ID 0;
BA_ "GenSigTimeoutTime_HU_High_X451" SG_ 1288 TCU_NMPDU_SRC_ECU_ID 0;
BA_ "GenSigTimeoutTime_HU_Mid_X451" SG_ 1288 TCU_NMPDU_SRC_ECU_ID 0;
BA_ "GenSigCycleTime" SG_ 1288 ActiveWakeUp_TCU 200;
BA_ "GenSigCycleTimeActive" SG_ 1288 ActiveWakeUp_TCU 200;
BA_ "GenSigSendType" SG_ 1288 ActiveWakeUp_TCU 7;
BA_ "GenSigTimeoutMsg_HU_A" SG_ 1288 ActiveWakeUp_TCU 0;
BA_ "GenSigTimeoutMsg_HU_B" SG_ 1288 ActiveWakeUp_TCU 0;
BA_ "GenSigTimeoutMsg_HU_High_X451" SG_ 1288 ActiveWakeUp_TCU 0;
BA_ "GenSigTimeoutMsg_HU_Mid_X451" SG_ 1288 ActiveWakeUp_TCU 0;
BA_ "GenSigTimeoutTime_HU_A" SG_ 1288 ActiveWakeUp_TCU 0;
BA_ "GenSigTimeoutTime_HU_B" SG_ 1288 ActiveWakeUp_TCU 0;
BA_ "GenSigTimeoutTime_HU_High_X451" SG_ 1288 ActiveWakeUp_TCU 0;
BA_ "GenSigTimeoutTime_HU_Mid_X451" SG_ 1288 ActiveWakeUp_TCU 0;
BA_ "GenSigCycleTime" SG_ 1287 PartialNetworkInformation_VCU 200;
BA_ "GenSigCycleTimeActive" SG_ 1287 PartialNetworkInformation_VCU 200;
BA_ "GenSigSendType" SG_ 1287 PartialNetworkInformation_VCU 7;
BA_ "GenSigTimeoutMsg_HU_A" SG_ 1287 PartialNetworkInformation_VCU 0;
BA_ "GenSigTimeoutMsg_HU_B" SG_ 1287 PartialNetworkInformation_VCU 0;
BA_ "GenSigTimeoutMsg_HU_High_X451" SG_ 1287 PartialNetworkInformation_VCU 0;
BA_ "GenSigTimeoutMsg_HU_Mid_X451" SG_ 1287 PartialNetworkInformation_VCU 0;
BA_ "GenSigTimeoutTime_HU_A" SG_ 1287 PartialNetworkInformation_VCU 0;
BA_ "GenSigTimeoutTime_HU_B" SG_ 1287 PartialNetworkInformation_VCU 0;
BA_ "GenSigTimeoutTime_HU_High_X451" SG_ 1287 PartialNetworkInformation_VCU 0;
BA_ "GenSigTimeoutTime_HU_Mid_X451" SG_ 1287 PartialNetworkInformation_VCU 0;
BA_ "GenSigCycleTime" SG_ 1287 VCU_NMPDU_USER_DATA_D3 200;
BA_ "GenSigCycleTimeActive" SG_ 1287 VCU_NMPDU_USER_DATA_D3 200;
BA_ "GenSigSendType" SG_ 1287 VCU_NMPDU_USER_DATA_D3 7;
BA_ "GenSigTimeoutMsg_HU_A" SG_ 1287 VCU_NMPDU_USER_DATA_D3 0;
BA_ "GenSigTimeoutMsg_HU_B" SG_ 1287 VCU_NMPDU_USER_DATA_D3 0;
BA_ "GenSigTimeoutMsg_HU_High_X451" SG_ 1287 VCU_NMPDU_USER_DATA_D3 0;
BA_ "GenSigTimeoutMsg_HU_Mid_X451" SG_ 1287 VCU_NMPDU_USER_DATA_D3 0;
BA_ "GenSigTimeoutTime_HU_A" SG_ 1287 VCU_NMPDU_USER_DATA_D3 0;
BA_ "GenSigTimeoutTime_HU_B" SG_ 1287 VCU_NMPDU_USER_DATA_D3 0;
BA_ "GenSigTimeoutTime_HU_High_X451" SG_ 1287 VCU_NMPDU_USER_DATA_D3 0;
BA_ "GenSigTimeoutTime_HU_Mid_X451" SG_ 1287 VCU_NMPDU_USER_DATA_D3 0;
BA_ "GenSigCycleTime" SG_ 1287 Reserved47 200;
BA_ "GenSigCycleTimeActive" SG_ 1287 Reserved47 200;
BA_ "GenSigSendType" SG_ 1287 Reserved47 7;
BA_ "GenSigTimeoutMsg_HU_A" SG_ 1287 Reserved47 0;
BA_ "GenSigTimeoutMsg_HU_B" SG_ 1287 Reserved47 0;
BA_ "GenSigTimeoutMsg_HU_High_X451" SG_ 1287 Reserved47 0;
BA_ "GenSigTimeoutMsg_HU_Mid_X451" SG_ 1287 Reserved47 0;
BA_ "GenSigTimeoutTime_HU_A" SG_ 1287 Reserved47 0;
BA_ "GenSigTimeoutTime_HU_B" SG_ 1287 Reserved47 0;
BA_ "GenSigTimeoutTime_HU_High_X451" SG_ 1287 Reserved47 0;
BA_ "GenSigTimeoutTime_HU_Mid_X451" SG_ 1287 Reserved47 0;
BA_ "GenSigCycleTime" SG_ 1287 Reserved46 200;
BA_ "GenSigCycleTimeActive" SG_ 1287 Reserved46 200;
BA_ "GenSigSendType" SG_ 1287 Reserved46 7;
BA_ "GenSigTimeoutMsg_HU_A" SG_ 1287 Reserved46 0;
BA_ "GenSigTimeoutMsg_HU_B" SG_ 1287 Reserved46 0;
BA_ "GenSigTimeoutMsg_HU_High_X451" SG_ 1287 Reserved46 0;
BA_ "GenSigTimeoutMsg_HU_Mid_X451" SG_ 1287 Reserved46 0;
BA_ "GenSigTimeoutTime_HU_A" SG_ 1287 Reserved46 0;
BA_ "GenSigTimeoutTime_HU_B" SG_ 1287 Reserved46 0;
BA_ "GenSigTimeoutTime_HU_High_X451" SG_ 1287 Reserved46 0;
BA_ "GenSigTimeoutTime_HU_Mid_X451" SG_ 1287 Reserved46 0;
BA_ "GenSigCycleTime" SG_ 1287 Reserved45 200;
BA_ "GenSigCycleTimeActive" SG_ 1287 Reserved45 200;
BA_ "GenSigSendType" SG_ 1287 Reserved45 7;
BA_ "GenSigTimeoutMsg_HU_A" SG_ 1287 Reserved45 0;
BA_ "GenSigTimeoutMsg_HU_B" SG_ 1287 Reserved45 0;
BA_ "GenSigTimeoutMsg_HU_High_X451" SG_ 1287 Reserved45 0;
BA_ "GenSigTimeoutMsg_HU_Mid_X451" SG_ 1287 Reserved45 0;
BA_ "GenSigTimeoutTime_HU_A" SG_ 1287 Reserved45 0;
BA_ "GenSigTimeoutTime_HU_B" SG_ 1287 Reserved45 0;
BA_ "GenSigTimeoutTime_HU_High_X451" SG_ 1287 Reserved45 0;
BA_ "GenSigTimeoutTime_HU_Mid_X451" SG_ 1287 Reserved45 0;
BA_ "GenSigCycleTime" SG_ 1287 Reserved44 200;
BA_ "GenSigCycleTimeActive" SG_ 1287 Reserved44 200;
BA_ "GenSigSendType" SG_ 1287 Reserved44 7;
BA_ "GenSigTimeoutMsg_HU_A" SG_ 1287 Reserved44 0;
BA_ "GenSigTimeoutMsg_HU_B" SG_ 1287 Reserved44 0;
BA_ "GenSigTimeoutMsg_HU_High_X451" SG_ 1287 Reserved44 0;
BA_ "GenSigTimeoutMsg_HU_Mid_X451" SG_ 1287 Reserved44 0;
BA_ "GenSigTimeoutTime_HU_A" SG_ 1287 Reserved44 0;
BA_ "GenSigTimeoutTime_HU_B" SG_ 1287 Reserved44 0;
BA_ "GenSigTimeoutTime_HU_High_X451" SG_ 1287 Reserved44 0;
BA_ "GenSigTimeoutTime_HU_Mid_X451" SG_ 1287 Reserved44 0;
BA_ "GenSigCycleTime" SG_ 1287 Reserved43 200;
BA_ "GenSigCycleTimeActive" SG_ 1287 Reserved43 200;
BA_ "GenSigSendType" SG_ 1287 Reserved43 7;
BA_ "GenSigTimeoutMsg_HU_A" SG_ 1287 Reserved43 0;
BA_ "GenSigTimeoutMsg_HU_B" SG_ 1287 Reserved43 0;
BA_ "GenSigTimeoutMsg_HU_High_X451" SG_ 1287 Reserved43 0;
BA_ "GenSigTimeoutMsg_HU_Mid_X451" SG_ 1287 Reserved43 0;
BA_ "GenSigTimeoutTime_HU_A" SG_ 1287 Reserved43 0;
BA_ "GenSigTimeoutTime_HU_B" SG_ 1287 Reserved43 0;
BA_ "GenSigTimeoutTime_HU_High_X451" SG_ 1287 Reserved43 0;
BA_ "GenSigTimeoutTime_HU_Mid_X451" SG_ 1287 Reserved43 0;
BA_ "GenSigCycleTime" SG_ 1287 Reserved42 200;
BA_ "GenSigCycleTimeActive" SG_ 1287 Reserved42 200;
BA_ "GenSigSendType" SG_ 1287 Reserved42 7;
BA_ "GenSigTimeoutMsg_HU_A" SG_ 1287 Reserved42 0;
BA_ "GenSigTimeoutMsg_HU_B" SG_ 1287 Reserved42 0;
BA_ "GenSigTimeoutMsg_HU_High_X451" SG_ 1287 Reserved42 0;
BA_ "GenSigTimeoutMsg_HU_Mid_X451" SG_ 1287 Reserved42 0;
BA_ "GenSigTimeoutTime_HU_A" SG_ 1287 Reserved42 0;
BA_ "GenSigTimeoutTime_HU_B" SG_ 1287 Reserved42 0;
BA_ "GenSigTimeoutTime_HU_High_X451" SG_ 1287 Reserved42 0;
BA_ "GenSigTimeoutTime_HU_Mid_X451" SG_ 1287 Reserved42 0;
BA_ "GenSigCycleTime" SG_ 1287 Reserved41 200;
BA_ "GenSigCycleTimeActive" SG_ 1287 Reserved41 200;
BA_ "GenSigSendType" SG_ 1287 Reserved41 7;
BA_ "GenSigTimeoutMsg_HU_A" SG_ 1287 Reserved41 0;
BA_ "GenSigTimeoutMsg_HU_B" SG_ 1287 Reserved41 0;
BA_ "GenSigTimeoutMsg_HU_High_X451" SG_ 1287 Reserved41 0;
BA_ "GenSigTimeoutMsg_HU_Mid_X451" SG_ 1287 Reserved41 0;
BA_ "GenSigTimeoutTime_HU_A" SG_ 1287 Reserved41 0;
BA_ "GenSigTimeoutTime_HU_B" SG_ 1287 Reserved41 0;
BA_ "GenSigTimeoutTime_HU_High_X451" SG_ 1287 Reserved41 0;
BA_ "GenSigTimeoutTime_HU_Mid_X451" SG_ 1287 Reserved41 0;
BA_ "GenSigCycleTime" SG_ 1287 Reserved40 200;
BA_ "GenSigCycleTimeActive" SG_ 1287 Reserved40 200;
BA_ "GenSigSendType" SG_ 1287 Reserved40 7;
BA_ "GenSigTimeoutMsg_HU_A" SG_ 1287 Reserved40 0;
BA_ "GenSigTimeoutMsg_HU_B" SG_ 1287 Reserved40 0;
BA_ "GenSigTimeoutMsg_HU_High_X451" SG_ 1287 Reserved40 0;
BA_ "GenSigTimeoutMsg_HU_Mid_X451" SG_ 1287 Reserved40 0;
BA_ "GenSigTimeoutTime_HU_A" SG_ 1287 Reserved40 0;
BA_ "GenSigTimeoutTime_HU_B" SG_ 1287 Reserved40 0;
BA_ "GenSigTimeoutTime_HU_High_X451" SG_ 1287 Reserved40 0;
BA_ "GenSigTimeoutTime_HU_Mid_X451" SG_ 1287 Reserved40 0;
BA_ "GenSigCycleTime" SG_ 1287 RepeatMessageReq_VCU 200;
BA_ "GenSigCycleTimeActive" SG_ 1287 RepeatMessageReq_VCU 200;
BA_ "GenSigSendType" SG_ 1287 RepeatMessageReq_VCU 7;
BA_ "GenSigTimeoutMsg_HU_A" SG_ 1287 RepeatMessageReq_VCU 0;
BA_ "GenSigTimeoutMsg_HU_B" SG_ 1287 RepeatMessageReq_VCU 0;
BA_ "GenSigTimeoutMsg_HU_High_X451" SG_ 1287 RepeatMessageReq_VCU 0;
BA_ "GenSigTimeoutMsg_HU_Mid_X451" SG_ 1287 RepeatMessageReq_VCU 0;
BA_ "GenSigTimeoutTime_HU_A" SG_ 1287 RepeatMessageReq_VCU 0;
BA_ "GenSigTimeoutTime_HU_B" SG_ 1287 RepeatMessageReq_VCU 0;
BA_ "GenSigTimeoutTime_HU_High_X451" SG_ 1287 RepeatMessageReq_VCU 0;
BA_ "GenSigTimeoutTime_HU_Mid_X451" SG_ 1287 RepeatMessageReq_VCU 0;
BA_ "GenSigCycleTime" SG_ 1287 PreviousState_VCU 200;
BA_ "GenSigCycleTimeActive" SG_ 1287 PreviousState_VCU 200;
BA_ "GenSigSendType" SG_ 1287 PreviousState_VCU 7;
BA_ "GenSigTimeoutMsg_HU_A" SG_ 1287 PreviousState_VCU 0;
BA_ "GenSigTimeoutMsg_HU_B" SG_ 1287 PreviousState_VCU 0;
BA_ "GenSigTimeoutMsg_HU_High_X451" SG_ 1287 PreviousState_VCU 0;
BA_ "GenSigTimeoutMsg_HU_Mid_X451" SG_ 1287 PreviousState_VCU 0;
BA_ "GenSigTimeoutTime_HU_A" SG_ 1287 PreviousState_VCU 0;
BA_ "GenSigTimeoutTime_HU_B" SG_ 1287 PreviousState_VCU 0;
BA_ "GenSigTimeoutTime_HU_High_X451" SG_ 1287 PreviousState_VCU 0;
BA_ "GenSigTimeoutTime_HU_Mid_X451" SG_ 1287 PreviousState_VCU 0;
BA_ "GenSigCycleTime" SG_ 1287 NMCoOrdSlpReady_VCU 200;
BA_ "GenSigCycleTimeActive" SG_ 1287 NMCoOrdSlpReady_VCU 200;
BA_ "GenSigSendType" SG_ 1287 NMCoOrdSlpReady_VCU 7;
BA_ "GenSigTimeoutMsg_HU_A" SG_ 1287 NMCoOrdSlpReady_VCU 0;
BA_ "GenSigTimeoutMsg_HU_B" SG_ 1287 NMCoOrdSlpReady_VCU 0;
BA_ "GenSigTimeoutMsg_HU_High_X451" SG_ 1287 NMCoOrdSlpReady_VCU 0;
BA_ "GenSigTimeoutMsg_HU_Mid_X451" SG_ 1287 NMCoOrdSlpReady_VCU 0;
BA_ "GenSigTimeoutTime_HU_A" SG_ 1287 NMCoOrdSlpReady_VCU 0;
BA_ "GenSigTimeoutTime_HU_B" SG_ 1287 NMCoOrdSlpReady_VCU 0;
BA_ "GenSigTimeoutTime_HU_High_X451" SG_ 1287 NMCoOrdSlpReady_VCU 0;
BA_ "GenSigTimeoutTime_HU_Mid_X451" SG_ 1287 NMCoOrdSlpReady_VCU 0;
BA_ "GenSigCycleTime" SG_ 1287 CurrentState_VCU 200;
BA_ "GenSigCycleTimeActive" SG_ 1287 CurrentState_VCU 200;
BA_ "GenSigSendType" SG_ 1287 CurrentState_VCU 7;
BA_ "GenSigTimeoutMsg_HU_A" SG_ 1287 CurrentState_VCU 0;
BA_ "GenSigTimeoutMsg_HU_B" SG_ 1287 CurrentState_VCU 0;
BA_ "GenSigTimeoutMsg_HU_High_X451" SG_ 1287 CurrentState_VCU 0;
BA_ "GenSigTimeoutMsg_HU_Mid_X451" SG_ 1287 CurrentState_VCU 0;
BA_ "GenSigTimeoutTime_HU_A" SG_ 1287 CurrentState_VCU 0;
BA_ "GenSigTimeoutTime_HU_B" SG_ 1287 CurrentState_VCU 0;
BA_ "GenSigTimeoutTime_HU_High_X451" SG_ 1287 CurrentState_VCU 0;
BA_ "GenSigTimeoutTime_HU_Mid_X451" SG_ 1287 CurrentState_VCU 0;
BA_ "GenSigCycleTime" SG_ 1287 VCU_NMPDU_USER_DATA_D5 200;
BA_ "GenSigCycleTimeActive" SG_ 1287 VCU_NMPDU_USER_DATA_D5 200;
BA_ "GenSigSendType" SG_ 1287 VCU_NMPDU_USER_DATA_D5 7;
BA_ "GenSigTimeoutMsg_HU_A" SG_ 1287 VCU_NMPDU_USER_DATA_D5 0;
BA_ "GenSigTimeoutMsg_HU_B" SG_ 1287 VCU_NMPDU_USER_DATA_D5 0;
BA_ "GenSigTimeoutMsg_HU_High_X451" SG_ 1287 VCU_NMPDU_USER_DATA_D5 0;
BA_ "GenSigTimeoutMsg_HU_Mid_X451" SG_ 1287 VCU_NMPDU_USER_DATA_D5 0;
BA_ "GenSigTimeoutTime_HU_A" SG_ 1287 VCU_NMPDU_USER_DATA_D5 0;
BA_ "GenSigTimeoutTime_HU_B" SG_ 1287 VCU_NMPDU_USER_DATA_D5 0;
BA_ "GenSigTimeoutTime_HU_High_X451" SG_ 1287 VCU_NMPDU_USER_DATA_D5 0;
BA_ "GenSigTimeoutTime_HU_Mid_X451" SG_ 1287 VCU_NMPDU_USER_DATA_D5 0;
BA_ "GenSigCycleTime" SG_ 1287 VCU_NMPDU_USER_DATA_D4 200;
BA_ "GenSigCycleTimeActive" SG_ 1287 VCU_NMPDU_USER_DATA_D4 200;
BA_ "GenSigSendType" SG_ 1287 VCU_NMPDU_USER_DATA_D4 7;
BA_ "GenSigTimeoutMsg_HU_A" SG_ 1287 VCU_NMPDU_USER_DATA_D4 0;
BA_ "GenSigTimeoutMsg_HU_B" SG_ 1287 VCU_NMPDU_USER_DATA_D4 0;
BA_ "GenSigTimeoutMsg_HU_High_X451" SG_ 1287 VCU_NMPDU_USER_DATA_D4 0;
BA_ "GenSigTimeoutMsg_HU_Mid_X451" SG_ 1287 VCU_NMPDU_USER_DATA_D4 0;
BA_ "GenSigTimeoutTime_HU_A" SG_ 1287 VCU_NMPDU_USER_DATA_D4 0;
BA_ "GenSigTimeoutTime_HU_B" SG_ 1287 VCU_NMPDU_USER_DATA_D4 0;
BA_ "GenSigTimeoutTime_HU_High_X451" SG_ 1287 VCU_NMPDU_USER_DATA_D4 0;
BA_ "GenSigTimeoutTime_HU_Mid_X451" SG_ 1287 VCU_NMPDU_USER_DATA_D4 0;
BA_ "GenSigCycleTime" SG_ 1287 VCU_NMPDU_USER_DATA_D2 200;
BA_ "GenSigCycleTimeActive" SG_ 1287 VCU_NMPDU_USER_DATA_D2 200;
BA_ "GenSigSendType" SG_ 1287 VCU_NMPDU_USER_DATA_D2 7;
BA_ "GenSigTimeoutMsg_HU_A" SG_ 1287 VCU_NMPDU_USER_DATA_D2 0;
BA_ "GenSigTimeoutMsg_HU_B" SG_ 1287 VCU_NMPDU_USER_DATA_D2 0;
BA_ "GenSigTimeoutMsg_HU_High_X451" SG_ 1287 VCU_NMPDU_USER_DATA_D2 0;
BA_ "GenSigTimeoutMsg_HU_Mid_X451" SG_ 1287 VCU_NMPDU_USER_DATA_D2 0;
BA_ "GenSigTimeoutTime_HU_A" SG_ 1287 VCU_NMPDU_USER_DATA_D2 0;
BA_ "GenSigTimeoutTime_HU_B" SG_ 1287 VCU_NMPDU_USER_DATA_D2 0;
BA_ "GenSigTimeoutTime_HU_High_X451" SG_ 1287 VCU_NMPDU_USER_DATA_D2 0;
BA_ "GenSigTimeoutTime_HU_Mid_X451" SG_ 1287 VCU_NMPDU_USER_DATA_D2 0;
BA_ "GenSigCycleTime" SG_ 1287 VCU_NMPDU_USER_DATA_D1 200;
BA_ "GenSigCycleTimeActive" SG_ 1287 VCU_NMPDU_USER_DATA_D1 200;
BA_ "GenSigSendType" SG_ 1287 VCU_NMPDU_USER_DATA_D1 7;
BA_ "GenSigTimeoutMsg_HU_A" SG_ 1287 VCU_NMPDU_USER_DATA_D1 0;
BA_ "GenSigTimeoutMsg_HU_B" SG_ 1287 VCU_NMPDU_USER_DATA_D1 0;
BA_ "GenSigTimeoutMsg_HU_High_X451" SG_ 1287 VCU_NMPDU_USER_DATA_D1 0;
BA_ "GenSigTimeoutMsg_HU_Mid_X451" SG_ 1287 VCU_NMPDU_USER_DATA_D1 0;
BA_ "GenSigTimeoutTime_HU_A" SG_ 1287 VCU_NMPDU_USER_DATA_D1 0;
BA_ "GenSigTimeoutTime_HU_B" SG_ 1287 VCU_NMPDU_USER_DATA_D1 0;
BA_ "GenSigTimeoutTime_HU_High_X451" SG_ 1287 VCU_NMPDU_USER_DATA_D1 0;
BA_ "GenSigTimeoutTime_HU_Mid_X451" SG_ 1287 VCU_NMPDU_USER_DATA_D1 0;
BA_ "GenSigCycleTime" SG_ 1287 VCU_NMPDU_SRC_ECU_ID 200;
BA_ "GenSigCycleTimeActive" SG_ 1287 VCU_NMPDU_SRC_ECU_ID 200;
BA_ "GenSigSendType" SG_ 1287 VCU_NMPDU_SRC_ECU_ID 7;
BA_ "GenSigTimeoutMsg_HU_A" SG_ 1287 VCU_NMPDU_SRC_ECU_ID 0;
BA_ "GenSigTimeoutMsg_HU_B" SG_ 1287 VCU_NMPDU_SRC_ECU_ID 0;
BA_ "GenSigTimeoutMsg_HU_High_X451" SG_ 1287 VCU_NMPDU_SRC_ECU_ID 0;
BA_ "GenSigTimeoutMsg_HU_Mid_X451" SG_ 1287 VCU_NMPDU_SRC_ECU_ID 0;
BA_ "GenSigTimeoutTime_HU_A" SG_ 1287 VCU_NMPDU_SRC_ECU_ID 0;
BA_ "GenSigTimeoutTime_HU_B" SG_ 1287 VCU_NMPDU_SRC_ECU_ID 0;
BA_ "GenSigTimeoutTime_HU_High_X451" SG_ 1287 VCU_NMPDU_SRC_ECU_ID 0;
BA_ "GenSigTimeoutTime_HU_Mid_X451" SG_ 1287 VCU_NMPDU_SRC_ECU_ID 0;
BA_ "GenSigCycleTime" SG_ 1287 ActiveWakeUp_VCU 200;
BA_ "GenSigCycleTimeActive" SG_ 1287 ActiveWakeUp_VCU 200;
BA_ "GenSigSendType" SG_ 1287 ActiveWakeUp_VCU 7;
BA_ "GenSigTimeoutMsg_HU_A" SG_ 1287 ActiveWakeUp_VCU 0;
BA_ "GenSigTimeoutMsg_HU_B" SG_ 1287 ActiveWakeUp_VCU 0;
BA_ "GenSigTimeoutMsg_HU_High_X451" SG_ 1287 ActiveWakeUp_VCU 0;
BA_ "GenSigTimeoutMsg_HU_Mid_X451" SG_ 1287 ActiveWakeUp_VCU 0;
BA_ "GenSigTimeoutTime_HU_A" SG_ 1287 ActiveWakeUp_VCU 0;
BA_ "GenSigTimeoutTime_HU_B" SG_ 1287 ActiveWakeUp_VCU 0;
BA_ "GenSigTimeoutTime_HU_High_X451" SG_ 1287 ActiveWakeUp_VCU 0;
BA_ "GenSigTimeoutTime_HU_Mid_X451" SG_ 1287 ActiveWakeUp_VCU 0;
BA_ "GenSigCycleTime" SG_ 703 OATICSigNewStatus 100;
BA_ "GenSigCycleTimeActive" SG_ 703 OATICSigNewStatus 100;
BA_ "GenSigSendType" SG_ 703 OATICSigNewStatus 7;
BA_ "GenSigStartValue" SG_ 703 OATICSigNewStatus 2;
BA_ "GenSigTimeoutMsg_HU_A" SG_ 703 OATICSigNewStatus 0;
BA_ "GenSigTimeoutMsg_HU_B" SG_ 703 OATICSigNewStatus 0;
BA_ "GenSigTimeoutMsg_HU_High_X451" SG_ 703 OATICSigNewStatus 0;
BA_ "GenSigTimeoutMsg_HU_Mid_X451" SG_ 703 OATICSigNewStatus 0;
BA_ "GenSigTimeoutTime_HU_A" SG_ 703 OATICSigNewStatus 0;
BA_ "GenSigTimeoutTime_HU_B" SG_ 703 OATICSigNewStatus 0;
BA_ "GenSigTimeoutTime_HU_High_X451" SG_ 703 OATICSigNewStatus 0;
BA_ "GenSigTimeoutTime_HU_Mid_X451" SG_ 703 OATICSigNewStatus 0;
BA_ "GenSigCycleTime" SG_ 703 OATICSigNew 100;
BA_ "GenSigCycleTimeActive" SG_ 703 OATICSigNew 100;
BA_ "GenSigSendType" SG_ 703 OATICSigNew 7;
BA_ "GenSigStartValue" SG_ 703 OATICSigNew 80;
BA_ "GenSigTimeoutMsg_HU_A" SG_ 703 OATICSigNew 0;
BA_ "GenSigTimeoutMsg_HU_B" SG_ 703 OATICSigNew 0;
BA_ "GenSigTimeoutMsg_HU_High_X451" SG_ 703 OATICSigNew 0;
BA_ "GenSigTimeoutMsg_HU_Mid_X451" SG_ 703 OATICSigNew 0;
BA_ "GenSigTimeoutTime_HU_A" SG_ 703 OATICSigNew 0;
BA_ "GenSigTimeoutTime_HU_B" SG_ 703 OATICSigNew 0;
BA_ "GenSigTimeoutTime_HU_High_X451" SG_ 703 OATICSigNew 0;
BA_ "GenSigTimeoutTime_HU_Mid_X451" SG_ 703 OATICSigNew 0;
VAL_ 3221225472 MDriverRequest_Updated 0 "Not Updated" 1 "Updated" ;
VAL_ 3221225472 MMotAct_Updated 0 "Not Updated" 1 "Updated" ;
VAL_ 944 INV1_MinTrqGbx 1023 "Init" ;
VAL_ 944 INV1_MaxTrqGbx 1023 "Init" ;
VAL_ 944 INV1_GbxOilT 254 "Init" 255 "Error" ;
VAL_ 688 VCU_INV1_CoolantFlow 63 "Init" ;
VAL_ 688 VCU_INV1_TCooltCirc 254 "Init" 255 "Error" ;
VAL_ 688 MessageCounter_2B0 0 "Init" ;
VAL_ 688 Checksum_2B0 0 "Init" ;
VAL_ 1472 INV1_FailCodeDFCIdc4 3 "not used" 2 "not used" 1 "FailCode contains a DFC-ID" 0 "FailCode contains a DTC" ;
VAL_ 1472 INV1_FailCodeDFCIdc3 3 "not used" 2 "not used" 1 "FailCode contains a DFC-ID" 0 "FailCode contains a DTC" ;
VAL_ 1472 INV1_FailCodeDFCIdc2 3 "not used" 2 "not used" 1 "FailCode contains a DFC-ID" 0 "FailCode contains a DTC" ;
VAL_ 1472 INV1_FailCodeDFCIdc1 3 "not used" 2 "not used" 1 "FailCode contains a DFC-ID" 0 "FailCode contains a DTC" ;
VAL_ 1472 INV1_FailCodeSt4 3 "not used" 2 "not used" 1 "fault active" 0 "fault since last clear" ;
VAL_ 1472 INV1_FailCodeSt3 3 "not used" 2 "not used" 1 "fault active" 0 "fault since last clear" ;
VAL_ 1472 INV1_FailCodeSt2 3 "not used" 2 "not used" 1 "fault active" 0 "fault since last clear" ;
VAL_ 1472 INV1_FailCodeSt1 3 "not used" 2 "not used" 1 "fault active" 0 "fault since last clear" ;
VAL_ 1456 MessageCounter_5B0 0 "Init" ;
VAL_ 512 Checksum_200 0 "Init" ;
VAL_ 512 MessageCounter_200 0 "Init" ;
VAL_ 512 INV1_State 12 "ResdHillHld" 0 "Init" 1 "WaitForPreChrg" 3 "Standby" 4 "UdcCtrl" 5 "AlOffsetCal" 6 "NCtlExt" 7 "NCtlInt" 8 "TrqCtrl" 9 "IsCtrl" 10 "UdcCtlBatt" 11 "Afterrun" 13 "Failure" 14 "Discharge" 15 "Freewheel" ;
VAL_ 512 INV1_Speed 65534 "Init" 65535 "Error" ;
VAL_ 512 INV1_CurrentHV 2047 "Error" 2046 "Init" ;
VAL_ 512 INV1_VoltageHV 1023 "Error" 1022 "Init" ;
VAL_ 512 INV1_OutputTorque 2047 "Error" 2046 "Init" ;
VAL_ 528 INV1_InterlockStatus 0 "Open" 1 "Closed" ;
VAL_ 528 INV1_MinCoolantFlow 63 "Init" ;
VAL_ 528 INV1_ParkLockStatus 0 "Running" 1 "UnlockPosReached" 2 "LockPosReached" 3 "PosUnknown" 4 "Failure" ;
VAL_ 528 INV1_EmergencyShutoffRequest 0 "NoShutOffRequested" 1 "ShutOffRequested" ;
VAL_ 528 Checksum_210 0 "Init" ;
VAL_ 528 MessageCounter_210 0 "Init" ;
VAL_ 528 INV1_MaxTorque 1023 "Init" ;
VAL_ 528 INV1_MinTorque 1023 "Init" ;
VAL_ 528 INV1_TrqWoDstC 2047 "Error" 2046 "Init" ;
VAL_ 528 INV1_TempCoolant 254 "Init" 255 "Error" ;
VAL_ 1568 INV1_MIL 0 "Off" 1 "On" ;
VAL_ 1568 INV1_StatorTemperature 511 "Error" 510 "Init" ;
VAL_ 1568 Checksum_620 0 "Init" ;
VAL_ 1568 MessageCounter_620 0 "Init" ;
VAL_ 1568 INV1_EVServiceLight 0 "Off" 1 "On" ;
VAL_ 1568 INV1_ElecTractionCtrlLight 0 "Off" 1 "On" ;
VAL_ 1568 INV1_InverterTemperature 254 "Init" 255 "Error" ;
VAL_ 1568 INV1_VoltageT30 0 "Init" ;
VAL_ 1568 INV1_RotorTemperature 511 "Error" 510 "Init" ;
VAL_ 928 Checksum_3A0 0 "Init" ;
VAL_ 928 MessageCounter_3A0 0 "Init" ;
VAL_ 928 INV1_MaxTorqueLongTerm 1023 "Init" ;
VAL_ 928 INV1_MinTorqueLongTerm 1023 "Init" ;
VAL_ 928 INV1_MaxTorqueShortTerm 1023 "Init" ;
VAL_ 928 INV1_MinTorqueShortTerm 1023 "Init" ;
VAL_ 672 VCU_INV1_IdcMinLongTerm 2046 "Init" 2047 "Error" ;
VAL_ 672 VCU_INV1_IdcMaxLongTerm 2046 "Init" 2047 "Error" ;
VAL_ 672 Checksum_2A0 0 "Init" ;
VAL_ 672 MessageCounter_2A0 0 "Init" ;
VAL_ 672 VCU_INV1_IdcMaxShortTerm 2046 "Init" 2047 "Error" ;
VAL_ 672 VCU_INV1_IdcMinShortTerm 2046 "Init" 2047 "Error" ;
VAL_ 704 VCU_INV1_TrqThresholdDampgCtl 0 "Init" ;
VAL_ 704 VCU_INV1_MaxTorqueDampgCtl 254 "Init" 255 "Error" ;
VAL_ 704 Checksum_2C0 0 "Init" ;
VAL_ 704 MessageCounter_2C0 0 "Init" ;
VAL_ 704 VCU_INV1_MinTorqueLimit 2046 "Init" 2047 "Error" ;
VAL_ 704 VCU_INV1_MaxTorqueGradient 16382 "Init" 16383 "Error" ;
VAL_ 704 VCU_INV1_MaxTorqueLimit 2046 "Init" 2047 "Error" ;
VAL_ 357 Tester_DDC_DesMod 1 "Buck request" 0 "Standby request" ;
VAL_ 533 Tester_OBC_ChrgDesMod 10 "Shutdown request" 6 "Heating Charging request" 5 "Discharging request" 4 "Charging request" 0 "Standby request" ;
VAL_ 640 Tester_ELK_Des 3 "All door unlock" 1 "All door lock" 0 "No command" ;
VAL_ 560 OBC_InsulationFault 1 "error" 0 "No error" ;
VAL_ 560 OBC_DischrgCCSt 3 "V2V connected" 2 "V2L connected" 1 "Half connected" 0 "Not connected" ;
VAL_ 560 OBC_DischrgCPSt 1 "Closed" 0 "Open" ;
VAL_ 560 OBC_uAcRms 8191 "Invalid" ;
VAL_ 560 OBC_iAcRms 1023 "Invalid" ;
VAL_ 560 OBC_IDcMax 1023 "Invalid" ;
VAL_ 560 OBC_TSocket 255 "Invalid" ;
VAL_ 549 OBC_UDc 16383 "Invalid" ;
VAL_ 549 OBC_TCoolr 255 "Invalid" ;
VAL_ 549 OBC_ChrgCPSt 7 "CP signal failure" 3 "ContectedWithPower" 2 "PowAvailableButNotActivated" 1 "S2 lock-up failure" 0 "Not Connected " ;
VAL_ 549 OBC_ChrgCCSt 2 "Half connected " 1 "Connected" 0 "Not connected " ;
VAL_ 549 OBC_Elk_St 4 "Unlock error" 3 "Lock error" 2 "Unlock" 1 "Lock" 0 "Default" ;
VAL_ 549 OBC_St 15 "Sleep" 14 "Heating Charging" 12 "Off" 11 "Shutdown" 10 "Failure" 9 "Derating" 5 "Disharging" 4 "Charging" 1 "Init" ;
VAL_ 1799 BMUFault 1 "Third Level Fault (High)" 0 "No Fault" ;
VAL_ 1799 LowVoltSupplyAlarm 1 "Third Fault Level(high)" 0 "No Fault" ;
VAL_ 1799 PrechargeFaultAlarm 1 "Third Fault Level(high)" 0 "No Fault" ;
VAL_ 1799 BattDischrgOverCurrAlarm 3 "Third Fault Level(high)" 2 "Second  Fault Level" 1 " First Fault Level" 0 "No Fault" ;
VAL_ 1799 BattFBOverCurrAlarm 3 "Third Fault Level(high)" 2 "Second  Fault Level" 1 " First Fault Level" 0 "No Fault" ;
VAL_ 1799 SOCJump 3 "Third Fault Level(high)" 2 "Second  Fault Level" 1 " First Fault Level" 0 "No Fault" ;
VAL_ 1799 SOCLowAlarm 3 "Third Fault Level(high)" 2 "Second  Fault Level" 1 " First Fault Level" 0 "No Fault" ;
VAL_ 1799 InsulationFault 3 "Third Fault Level(high)" 2 "Second  Fault Level" 1 " First Fault Level" 0 "No Fault" ;
VAL_ 1799 PosMainRlyConglut 1 "Third Fault Level(high)" 0 "No Fault" ;
VAL_ 1799 CAN3CommAlarm 1 "Third Fault Level(high)" 0 "No Fault" ;
VAL_ 1799 CAN1CommAlarm 1 "Third Fault Level(high)" 0 "No Fault" ;
VAL_ 1799 TotalBattVoltUnderAlarm 3 "Third Fault Level(high)" 2 "Second  Fault Level" 1 " First Fault Level" 0 "No Fault" ;
VAL_ 1799 BattUnderTempAlarm 3 "Third Fault Level(high)" 2 "Second  Fault Level" 1 " First Fault Level" 0 "No Fault" ;
VAL_ 1799 NegMainRlyConglut 1 "Third Fault Level(high)" 0 "No Fault" ;
VAL_ 1799 HVILAlarm 1 "Third Fault Level(high)" 0 "No Fault" ;
VAL_ 1799 TotalBattVoltOverAlarm 3 "Third Fault Level(high)" 2 "Second  Fault Level" 1 " First Fault Level" 0 "No Fault" ;
VAL_ 1799 BattHighTempAlarm 3 "Third Fault Level(high)" 2 "Second  Fault Level" 1 " First Fault Level" 0 "No Fault" ;
VAL_ 1799 SOCHighAlarm 3 "Third Fault Level(high)" 2 "Second  Fault Level" 1 " First Fault Level" 0 "No Fault" ;
VAL_ 1799 CellVoltDiffOverAlarm 3 "Third Fault Level(high)" 2 "Second  Fault Level" 1 " First Fault Level" 0 "No Fault" ;
VAL_ 1799 CellTempDiffOverAlarm 3 "Third Fault Level(high)" 2 "Second  Fault Level" 1 " First Fault Level" 0 "No Fault" ;
VAL_ 1799 MinCellVoltUnderAlarm 3 "Third Fault Level(high)" 2 "Second  Fault Level" 1 " First Fault Level" 0 "No Fault" ;
VAL_ 1799 MaxCellVoltOverAlarm 3 "Third Fault Level(high)" 2 "Second  Fault Level" 1 " First Fault Level" 0 "No Fault" ;
VAL_ 1795 PreRlyClsd 1 "Close" 0 "Open" ;
VAL_ 1795 MaiRlyPClsd 1 "Close" 0 "Open" ;
VAL_ 1795 MaiRlyNClsd 1 "Close" 0 "Open" ;
VAL_ 1793 HVILDetect 1 "HVIL Detect Turn ON" 0 "HVIL Detect Turn OFF" ;
VAL_ 1793 Charging_Flag 1 "On" 0 "Off" ;
VAL_ 1793 BMSModeReq 4 "HVPowerdown" 3 "HVActive" 2 "Reserved" 1 "Standby" 0 "Initializing" ;
VAL_ 1793 HSC_BCM_LEAKAGE_ENA 1 "On" 0 "Off" ;
VAL_ 1793 EqualizationTrigger 1 "On" 0 "Off" ;
VAL_ 1801 BMS_DerateFlag 1 "Derate enabled" 0 "No derate" ;
VAL_ 1801 SOC_CalibrationFlag 1 "Reached" 0 "Not Reached" ;
VAL_ 1801 OperMod 7 "Ready to Sleep" 6 "Fault" 5 "Precharge Failure" 4 "NA" 3 "HVActive" 2 "Precharge" 1 "Standby" 0 "Initialization" ;
VAL_ 1801 FltRank 3 "Third Fault Level High" 2 "Second Fault Level" 1 "First Fault Level" 0 "No Fault" ;
VAL_ 1808 InsulatnDetect_OFF_Fdbk 1 "Insulation detect is ON" 0 "Insulation detect is ON" ;
VAL_ 280 InhibitRecuprationAbsStatus 3 "Reserved for future use" 2 "Information given is implausible" 1 "Reserved for future use" 0 "Information given  is correct" ;
VAL_ 280 InhibitRecuprationAbs 1 "Recupration request is active" 0 "Recupration request is not active" ;
VAL_ 730 AcclrmInfoXYZStatus 3 "Signal not available" 2 "Information given is implausible" 1 "Reserved for future use " 0 "Plausible  - Information given is correct" ;
VAL_ 731 GyroInfoXYZStatus 3 "Signal not available" 2 "Information given is implausible" 1 "Reserved for future use " 0 "Plausible  - Information given is correct" ;
VAL_ 582 AvgEnergyConsmpTripBStatus 3 "Reserved" 2 "Information given is implausible due to a detected failure" 1 "Reserved" 0 "Information given is correct and according to specification" ;
VAL_ 582 AvgEnergyConsmpTripAStatus 3 "Reserved" 2 "Information given is implausible due to a detected failure" 1 "Reserved" 0 "Information given is correct and according to specification" ;
VAL_ 582 InstPwrConsumpStatus 3 "Reserved" 2 "Information given is implausible" 1 "Reserved" 0 "Information given is correct" ;
VAL_ 719 PtcHtrForcedCutoff 3 "Signal not available" 2 "Forced cutoff required" 1 "Reserved for future use" 0 "Forced Cutoff not required" ;
VAL_ 1142 PEPS_Invalid_failure_status 3 "Reserved" 2 "Failure healed Ageing in progress" 1 "Failure matured & DTC in memory" 0 "Failure is not detected" ;
VAL_ 1142 Telematics_MTO_Failure_status 3 "Reserved" 2 "Failure healed aging in progress" 1 "Failure matured & DTC in memory" 0 "Failure is not detected" ;
VAL_ 1142 Telematics_Invalid_FailureStatus 3 "Reserved" 2 "Failure healed aging in progress" 1 "Failure matured & DTC in memory" 0 "Failure is not detected" ;
VAL_ 1142 SRS_MTO_Failure_Status 3 "Reserved" 2 "Failure healed aging in progress" 1 "Failure detected DTC in Memory" 0 "Failure is not detected" ;
VAL_ 1142 PEPS_MTO_Failure_Status 3 "Reserved" 2 "Failure healed aging in progress" 1 "Failure detected DTC in Memory" 0 "Failure is not detected" ;
VAL_ 1142 IPcMToFailureStatus 3 "Reserved" 2 "Failure healed Ageing in progress" 1 "Failure matured & DTC in memory" 0 "Failure is not detected" ;
VAL_ 1142 IPcInvalidFailureStatus 3 "Reserved" 2 "Failure healed Ageing in progress" 1 "Failure matured & DTC in memory" 0 "Failure is not detected" ;
VAL_ 1142 ABsMToFailureStatus 3 "Reserved" 2 "Failure healed aging in progress" 1 "Failrue detected DTC in memory" 0 "Failure is not detected" ;
VAL_ 1142 ABsInvalidFailureStatus 3 "Reserved" 2 "Failure healed ageing in progress" 1 "fail detected and DTC  in memory" 0 "failure not detected" ;
VAL_ 1142 VCU_EP_Failure_Status 3 "Historic DTC" 2 "Failurehealed Ageing in progress" 1 "Failure matured & DTC in memory" 0 "Faiulure is not detected " ;
VAL_ 1142 VCU_BO_Failure_Status 3 "Historic DTC" 2 "Failurehealed Ageing in progress" 1 "Failure matured & DTC in memory" 0 "Faiulure is not detected " ;
VAL_ 1142 GSS_EV_Invalid_Failure_Status 3 "Reserved" 2 "Failure Healed; aging in progress" 1 "Failure Detected; DTC in memory" 0 "Failure is not Detected" ;
VAL_ 1142 GSS_EV_MTO_Failure_Status 3 "Reserved" 2 "Failure Healed; aging in progress" 1 "Failure Detected; DTC in memory" 0 "Failure is not Detected" ;
VAL_ 1142 CCM_MTO_Failure_Status 3 "Reserved" 2 "Failure healed & Ageing in progress" 1 "failure is detected & DTC in memeory" 0 "Failure is not detected" ;
VAL_ 1142 CCM_Invalid_Failure_Status 3 "Reserved" 2 "Failure healed Ageing in progress" 1 "Failure matured & DTC in memory" 0 "Failure is not detected" ;
VAL_ 1142 BCmInvalidFailureStatus 3 "Reserved" 2 "Failure healed Ageing in progress" 1 "Failure matured & DTC in memory" 0 "Failure is not detected" ;
VAL_ 1142 BCmMToFailureStatus 3 "Reserved" 2 "Failure healed aging in progress" 1 "Failure detected; DTC in memory" 0 "Failrue is not detected" ;
VAL_ 581 CabinCoolingSolValveStateStatus 3 "Reserved" 2 "Information given is implausible due to a detected failure " 1 "Reserved" 0 "Information given correct and according to specification" ;
VAL_ 581 CabinCoolingSolValveState 3 "Reserved" 2 "Cabin Cooling SV is ON" 1 "Reserved" 0 "Cabin Cooling SV is OFF" ;
VAL_ 581 LowHVBatteryChargeStatus 3 "Reserved" 2 "Information given is implausible due to a detected failure" 1 "Reserved" 0 "Information given is correct and according to specification" ;
VAL_ 581 LowHVBatteryCharge 3 " Reserved for future use" 2 "Low HV Battery Charge lamp ON" 1 "Low HV Battery Charge lamp Flashing" 0 "Low HV Battery Charge lamp is OFF. " ;
VAL_ 581 LowLVBatteryChargeStatus 3 "Reserved" 2 "Information given is implausible due to a detected failure" 1 "Reserved" 0 "Information given is correct and according to specification" ;
VAL_ 581 LowLVBatteryCharge 3 " Reserved for future use" 2 "Low LV Battery Charge lamp ON" 1 "Low LV Battery Charge lamp Flashing" 0 "Low LV Battery Charge lamp is OFF. " ;
VAL_ 581 HvAmpHrStatus 3 "Reserved" 2 "Information  is implausible due to a detected failure " 1 "Reserved" 0 "Information is correct and accord to specification" ;
VAL_ 1288 RepeatMessageReq_TCU 1 "Repeat message state requested" 0 "Repeat message state not requested" ;
VAL_ 1288 PreviousState_TCU 7 "Reserved" 6 "Reserved" 5 "Reserved" 4 " Bus Sleep State" 3 "Prepare Bus Sleep State" 2 "Ready Sleep State" 1 "Normal Operation State" 0 "Repeat Message State" ;
VAL_ 1288 CurrentState_TCU 1 "Normal Operation State" 0 "Repeat Messgae State" ;
VAL_ 1288 ActiveWakeUp_TCU 1 "Node has  woken up the network(Active wakeup)" 0 "Node has not woken up the network(Passive wakeup)" ;
VAL_ 1287 RepeatMessageReq_VCU 1 "Repeat message state requested" 0 "Repeat message state not requested" ;
VAL_ 1287 PreviousState_VCU 7 "Reserved" 6 "Reserved" 5 "Reserved" 4 " Bus Sleep State" 3 "Prepare Bus Sleep State" 2 "Ready Sleep State" 1 "Normal Operation State" 0 "Repeat Message State" ;
VAL_ 1287 CurrentState_VCU 1 "Normal Operation State" 0 "Repeat Messgae State" ;
VAL_ 1287 ActiveWakeUp_VCU 1 "Node has  woken up the network(Active wakeup)" 0 "Node has not woken up the network(Passive wakeup)" ;
VAL_ 703 OATICSigNewStatus 3 "Signal OATSig is not available" 2 "Implausible -Information given at OATICSig is implausible" 1 "Reserved for future use" 0 "Plausible-InformationgivenatOATICSigiscorrectandaccordingtospec" ;
